VERSION ""

NS_ :

BS_:

BU_: ACM AMP BCM DIAG_TEST IPC LBSS SGW MCM MHM RBSS TTM VTM

BO_ 1884 BCM_IGNITION_ON_COUNTER: 2 BCM
 SG_ IgnitionOnCounter : 7|16@0+ (1,0) [0|65535] "-"  ACM,AMP,LBSS,SGW,MCM,RBSS,TTM,VTM

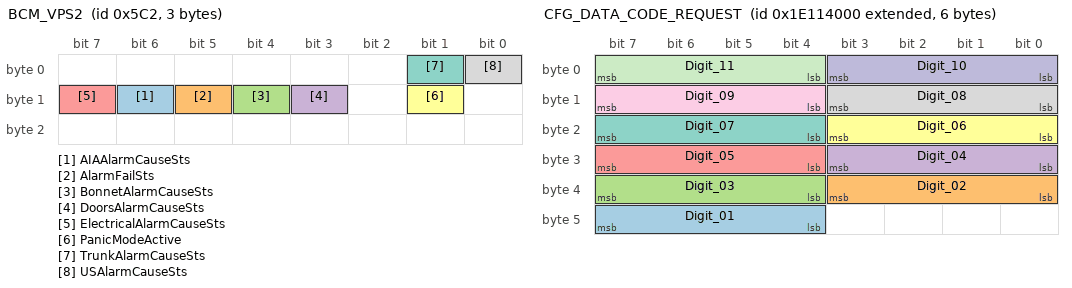
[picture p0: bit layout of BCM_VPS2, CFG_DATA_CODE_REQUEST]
BO_ 1474 BCM_VPS2: 3 BCM
 SG_ AIAAlarmCauseSts : 14|1@0+ (1,0) [0|1] "-"  IPC
 SG_ AlarmFailSts : 13|1@0+ (1,0) [0|1] "-"  IPC
 SG_ BonnetAlarmCauseSts : 12|1@0+ (1,0) [0|1] "-"  IPC
 SG_ DoorsAlarmCauseSts : 11|1@0+ (1,0) [0|1] "-"  IPC
 SG_ ElectricalAlarmCauseSts : 15|1@0+ (1,0) [0|1] "-"  IPC
 SG_ PanicModeActive : 9|1@0+ (1,0) [0|1] "-"  Vector__XXX
 SG_ TrunkAlarmCauseSts : 1|1@0+ (1,0) [0|1] "-"  IPC
 SG_ USAlarmCauseSts : 0|1@0+ (1,0) [0|1] "-"  IPC

BO_ 160 BODY6: 2 BCM
 SG_ BCMFpsCommand : 5|1@0+ (1,0) [0|1] "-"  ACM,MCM,MHM
 SG_ BCMFpsConfirm : 7|1@0+ (1,0) [0|1] "-"  ACM,MCM,MHM
 SG_ BCMFpsFailSts : 6|1@0+ (1,0) [0|1] "-"  ACM,MCM,MHM

BO_ 2651930624 CFG_DATA_CODE_REQUEST: 6 BCM
 SG_ Digit_01 : 47|4@0+ (1,0) [0|15] ""  ACM,AMP,LBSS,SGW,MCM,RBSS,TTM
 SG_ Digit_02 : 35|4@0+ (1,0) [0|15] ""  ACM,AMP,LBSS,SGW,MCM,RBSS,TTM
 SG_ Digit_03 : 39|4@0+ (1,0) [0|15] ""  ACM,AMP,LBSS,SGW,MCM,RBSS,TTM
 SG_ Digit_04 : 27|4@0+ (1,0) [0|15] ""  ACM,AMP,LBSS,SGW,MCM,RBSS,TTM
 SG_ Digit_05 : 31|4@0+ (1,0) [0|15] ""  ACM,AMP,LBSS,SGW,MCM,RBSS,TTM
 SG_ Digit_06 : 19|4@0+ (1,0) [0|15] ""  ACM,AMP,LBSS,SGW,MCM,RBSS,TTM
 SG_ Digit_07 : 23|4@0+ (1,0) [0|15] ""  ACM,AMP,LBSS,SGW,MCM,RBSS,TTM
 SG_ Digit_08 : 11|4@0+ (1,0) [0|15] ""  ACM,AMP,LBSS,SGW,MCM,RBSS,TTM
 SG_ Digit_09 : 15|4@0+ (1,0) [0|15] ""  ACM,AMP,LBSS,SGW,MCM,RBSS,TTM
 SG_ Digit_10 : 3|4@0+ (1,0) [0|15] ""  ACM,AMP,LBSS,SGW,MCM,RBSS,TTM
 SG_ Digit_11 : 7|4@0+ (1,0) [0|15] ""  ACM,AMP,LBSS,SGW,MCM,RBSS,TTM

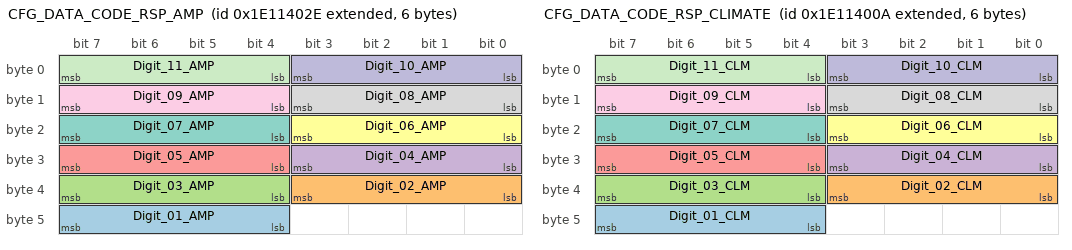
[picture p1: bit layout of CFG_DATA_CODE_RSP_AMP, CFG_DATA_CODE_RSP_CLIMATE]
BO_ 2651930670 CFG_DATA_CODE_RSP_AMP: 6 AMP
 SG_ Digit_01_AMP : 47|4@0+ (1,0) [0|15] "-"  BCM
 SG_ Digit_02_AMP : 35|4@0+ (1,0) [0|15] "-"  BCM
 SG_ Digit_03_AMP : 39|4@0+ (1,0) [0|15] "-"  BCM
 SG_ Digit_04_AMP : 27|4@0+ (1,0) [0|15] "-"  BCM
 SG_ Digit_05_AMP : 31|4@0+ (1,0) [0|15] "-"  BCM
 SG_ Digit_06_AMP : 19|4@0+ (1,0) [0|15] "-"  BCM
 SG_ Digit_07_AMP : 23|4@0+ (1,0) [0|15] "-"  BCM
 SG_ Digit_08_AMP : 11|4@0+ (1,0) [0|15] "-"  BCM
 SG_ Digit_09_AMP : 15|4@0+ (1,0) [0|15] "-"  BCM
 SG_ Digit_10_AMP : 3|4@0+ (1,0) [0|15] "-"  BCM
 SG_ Digit_11_AMP : 7|4@0+ (1,0) [0|15] "-"  BCM

BO_ 2651930634 CFG_DATA_CODE_RSP_CLIMATE: 6 ACM
 SG_ Digit_01_CLM : 47|4@0+ (1,0) [0|15] "-"  BCM
 SG_ Digit_02_CLM : 35|4@0+ (1,0) [0|15] "-"  BCM
 SG_ Digit_03_CLM : 39|4@0+ (1,0) [0|15] "-"  BCM
 SG_ Digit_04_CLM : 27|4@0+ (1,0) [0|15] "-"  BCM
 SG_ Digit_05_CLM : 31|4@0+ (1,0) [0|15] "-"  BCM
 SG_ Digit_06_CLM : 19|4@0+ (1,0) [0|15] "-"  BCM
 SG_ Digit_07_CLM : 23|4@0+ (1,0) [0|15] "-"  BCM
 SG_ Digit_08_CLM : 11|4@0+ (1,0) [0|15] "-"  BCM
 SG_ Digit_09_CLM : 15|4@0+ (1,0) [0|15] "-"  BCM
 SG_ Digit_10_CLM : 3|4@0+ (1,0) [0|15] "-"  BCM
 SG_ Digit_11_CLM : 7|4@0+ (1,0) [0|15] "-"  BCM

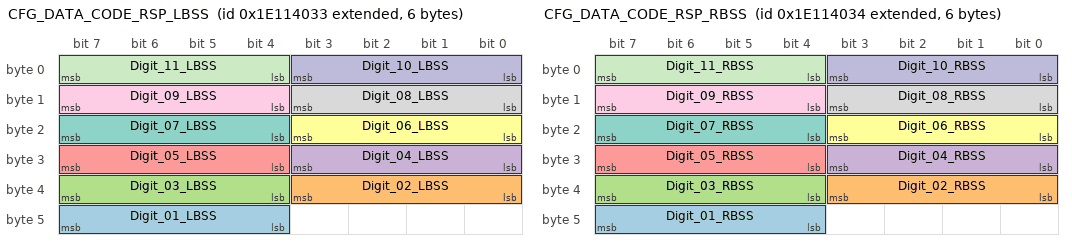
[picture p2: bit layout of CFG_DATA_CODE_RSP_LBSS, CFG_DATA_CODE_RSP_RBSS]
BO_ 2651930675 CFG_DATA_CODE_RSP_LBSS: 6 LBSS
 SG_ Digit_01_LBSS : 47|4@0+ (1,0) [0|15] "-"  BCM
 SG_ Digit_02_LBSS : 35|4@0+ (1,0) [0|15] "-"  BCM
 SG_ Digit_03_LBSS : 39|4@0+ (1,0) [0|15] "-"  BCM
 SG_ Digit_04_LBSS : 27|4@0+ (1,0) [0|15] "-"  BCM
 SG_ Digit_05_LBSS : 31|4@0+ (1,0) [0|15] "-"  BCM
 SG_ Digit_06_LBSS : 19|4@0+ (1,0) [0|15] "-"  BCM
 SG_ Digit_07_LBSS : 23|4@0+ (1,0) [0|15] "-"  BCM
 SG_ Digit_08_LBSS : 11|4@0+ (1,0) [0|15] "-"  BCM
 SG_ Digit_09_LBSS : 15|4@0+ (1,0) [0|15] "-"  BCM
 SG_ Digit_10_LBSS : 3|4@0+ (1,0) [0|15] "-"  BCM
 SG_ Digit_11_LBSS : 7|4@0+ (1,0) [0|15] "-"  BCM

BO_ 2651930676 CFG_DATA_CODE_RSP_RBSS: 6 RBSS
 SG_ Digit_01_RBSS : 47|4@0+ (1,0) [0|15] "-"  BCM
 SG_ Digit_02_RBSS : 35|4@0+ (1,0) [0|15] "-"  BCM
 SG_ Digit_03_RBSS : 39|4@0+ (1,0) [0|15] "-"  BCM
 SG_ Digit_04_RBSS : 27|4@0+ (1,0) [0|15] "-"  BCM
 SG_ Digit_05_RBSS : 31|4@0+ (1,0) [0|15] "-"  BCM
 SG_ Digit_06_RBSS : 19|4@0+ (1,0) [0|15] "-"  BCM
 SG_ Digit_07_RBSS : 23|4@0+ (1,0) [0|15] "-"  BCM
 SG_ Digit_08_RBSS : 11|4@0+ (1,0) [0|15] "-"  BCM
 SG_ Digit_09_RBSS : 15|4@0+ (1,0) [0|15] "-"  BCM
 SG_ Digit_10_RBSS : 3|4@0+ (1,0) [0|15] "-"  BCM
 SG_ Digit_11_RBSS : 7|4@0+ (1,0) [0|15] "-"  BCM

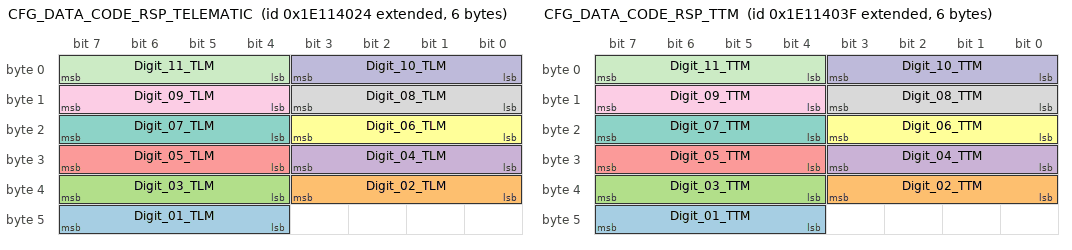
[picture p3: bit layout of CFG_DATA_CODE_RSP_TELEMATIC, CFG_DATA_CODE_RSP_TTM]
BO_ 2651930660 CFG_DATA_CODE_RSP_TELEMATIC: 6 SGW
 SG_ Digit_01_TLM : 47|4@0+ (1,0) [0|15] "-"  BCM
 SG_ Digit_02_TLM : 35|4@0+ (1,0) [0|15] "-"  BCM
 SG_ Digit_03_TLM : 39|4@0+ (1,0) [0|15] "-"  BCM
 SG_ Digit_04_TLM : 27|4@0+ (1,0) [0|15] "-"  BCM
 SG_ Digit_05_TLM : 31|4@0+ (1,0) [0|15] "-"  BCM
 SG_ Digit_06_TLM : 19|4@0+ (1,0) [0|15] "-"  BCM
 SG_ Digit_07_TLM : 23|4@0+ (1,0) [0|15] "-"  BCM
 SG_ Digit_08_TLM : 11|4@0+ (1,0) [0|15] "-"  BCM
 SG_ Digit_09_TLM : 15|4@0+ (1,0) [0|15] "-"  BCM
 SG_ Digit_10_TLM : 3|4@0+ (1,0) [0|15] "-"  BCM
 SG_ Digit_11_TLM : 7|4@0+ (1,0) [0|15] "-"  BCM

BO_ 2651930687 CFG_DATA_CODE_RSP_TTM: 6 TTM
 SG_ Digit_01_TTM : 47|4@0+ (1,0) [0|15] "-"  BCM
 SG_ Digit_02_TTM : 35|4@0+ (1,0) [0|15] "-"  BCM
 SG_ Digit_03_TTM : 39|4@0+ (1,0) [0|15] "-"  BCM
 SG_ Digit_04_TTM : 27|4@0+ (1,0) [0|15] "-"  BCM
 SG_ Digit_05_TTM : 31|4@0+ (1,0) [0|15] "-"  BCM
 SG_ Digit_06_TTM : 19|4@0+ (1,0) [0|15] "-"  BCM
 SG_ Digit_07_TTM : 23|4@0+ (1,0) [0|15] "-"  BCM
 SG_ Digit_08_TTM : 11|4@0+ (1,0) [0|15] "-"  BCM
 SG_ Digit_09_TTM : 15|4@0+ (1,0) [0|15] "-"  BCM
 SG_ Digit_10_TTM : 3|4@0+ (1,0) [0|15] "-"  BCM
 SG_ Digit_11_TTM : 7|4@0+ (1,0) [0|15] "-"  BCM

BO_ 134 CLIMATE_REQ: 2 ACM
 SG_ FPS_Status_Request : 7|1@0+ (1,0) [0|1] "-"  BCM

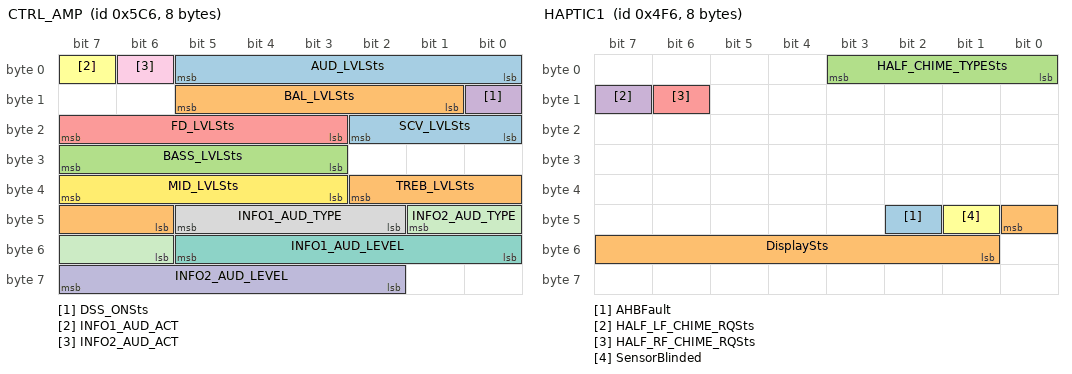
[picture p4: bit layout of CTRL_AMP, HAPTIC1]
BO_ 1478 CTRL_AMP: 8 SGW
 SG_ AUD_LVLSts : 5|6@0+ (1,0) [0|63] ""  AMP
 SG_ BAL_LVLSts : 13|5@0+ (1,0) [0|31] ""  AMP
 SG_ BASS_LVLSts : 31|5@0+ (1,0) [0|31] ""  AMP
 SG_ DSS_ONSts : 8|1@0+ (1,0) [0|1] ""  AMP
 SG_ FD_LVLSts : 23|5@0+ (1,0) [0|31] ""  AMP
 SG_ INFO1_AUD_ACT : 7|1@0+ (1,0) [0|1] ""  AMP
 SG_ INFO1_AUD_LEVEL : 53|6@0+ (1,0) [0|63] ""  AMP
 SG_ INFO1_AUD_TYPE : 45|4@0+ (1,0) [0|15] ""  AMP
 SG_ INFO2_AUD_ACT : 6|1@0+ (1,0) [0|1] ""  AMP
 SG_ INFO2_AUD_LEVEL : 63|6@0+ (1,0) [0|63] ""  AMP
 SG_ INFO2_AUD_TYPE : 41|4@0+ (1,0) [0|15] ""  AMP
 SG_ MID_LVLSts : 39|5@0+ (1,0) [0|31] ""  AMP
 SG_ SCV_LVLSts : 18|3@0+ (1,0) [0|6] ""  AMP
 SG_ TREB_LVLSts : 34|5@0+ (1,0) [0|31] ""  AMP

BO_ 2564554481 DIAGNOSTIC_REQ_FUNC_BH_C2: 8 DIAG_TEST
 SG_ N_PDU : 7|64@0+ (1,0) [0|0] ""  ACM,AMP,BCM,LBSS,MCM,RBSS,TTM,VTM

BO_ 2564457457 DIAGNOSTIC_REQUEST_AMP: 8 BCM
 SG_ N_PDU : 7|64@0+ (1,0) [0|0] ""  AMP

BO_ 2564462833 DIAGNOSTIC_REQUEST_CLIMATE: 8 BCM
 SG_ N_PDU : 7|64@0+ (1,0) [0|0] ""  ACM,MCM

BO_ 2564449009 DIAGNOSTIC_REQUEST_LBSS: 8 BCM
 SG_ N_PDU : 7|64@0+ (1,0) [0|0] ""  LBSS

BO_ 2564449777 DIAGNOSTIC_REQUEST_RBSS: 8 BCM
 SG_ N_PDU : 7|64@0+ (1,0) [0|0] ""  RBSS

BO_ 2564442865 DIAGNOSTIC_REQUEST_TTM: 8 BCM
 SG_ N_PDU : 7|64@0+ (1,0) [0|0] ""  TTM

BO_ 2564473329 DIAGNOSTIC_REQUEST_VTM: 8 BCM
 SG_ N_PDU : 7|64@0+ (1,0) [0|0] "-"  VTM

BO_ 2564485507 DIAGNOSTIC_RESPONSE_AMP: 8 AMP
 SG_ N_PDU : 7|64@0+ (1,0) [0|0] "-"  BCM,DIAG_TEST,SGW

BO_ 2564485528 DIAGNOSTIC_RESPONSE_CLIMATE: 8 ACM
 SG_ N_PDU : 7|64@0+ (1,0) [0|0] ""  BCM,DIAG_TEST,SGW

BO_ 2564485474 DIAGNOSTIC_RESPONSE_LBSS: 8 LBSS
 SG_ N_PDU : 7|64@0+ (1,0) [0|0] "-"  BCM,DIAG_TEST,SGW

BO_ 2564485477 DIAGNOSTIC_RESPONSE_RBSS: 8 RBSS
 SG_ N_PDU : 7|64@0+ (1,0) [0|0] "-"  BCM,DIAG_TEST,SGW

BO_ 2564485450 DIAGNOSTIC_RESPONSE_TTM: 8 TTM
 SG_ N_PDU : 7|64@0+ (1,0) [0|0] "-"  BCM,DIAG_TEST,SGW

BO_ 2564485569 DIAGNOSTIC_RESPONSE_VTM: 8 VTM
 SG_ N_PDU : 7|64@0+ (1,0) [0|0] "-"  BCM,DIAG_TEST,SGW

BO_ 852 EXTERNAL_LIGHTS: 4 BCM
 SG_ AHBFeature : 19|1@0+ (1,0) [0|1] "-"  IPC
 SG_ AlertLightsON : 31|1@0+ (1,0) [0|1] "-"  IPC
 SG_ DRLFault : 6|1@0+ (1,0) [0|1] "-"  IPC
 SG_ FHeatedWindowSts : 5|1@0+ (1,0) [0|1] "-"  ACM,MCM
 SG_ FrontFogLightSts : 4|1@0+ (1,0) [0|1] "-"  IPC
 SG_ HeatedMirrorSts : 3|1@0+ (1,0) [0|1] "-"  Vector__XXX
 SG_ HighBeamSts : 2|1@0+ (1,0) [0|1] "-"  IPC
 SG_ L_TurnLightActivationSts : 17|1@0+ (1,0) [0|1] "-"  TTM
 SG_ LHParkingLightSts : 1|1@0+ (1,0) [0|1] "-"  IPC,TTM
 SG_ LHTurnLightFault : 0|1@0+ (1,0) [0|1] "-"  IPC
 SG_ LHTurnSignalSts : 15|1@0+ (1,0) [0|1] "-"  IPC,TTM
 SG_ LowBeamSts : 14|1@0+ (1,0) [0|1] "-"  IPC
 SG_ ParkingLightFault : 13|1@0+ (1,0) [0|1] "-"  IPC
 SG_ PlateLightFault : 12|1@0+ (1,0) [0|1] "-"  IPC
 SG_ R_TurnLightActivationSts : 16|1@0+ (1,0) [0|1] "-"  TTM
 SG_ RearFogLightFault : 11|1@0+ (1,0) [0|1] "-"  IPC
 SG_ RearFogLightSts : 10|1@0+ (1,0) [0|1] "-"  IPC,TTM
 SG_ ReverseGearLightFault : 9|1@0+ (1,0) [0|1] "-"  IPC
 SG_ RHeatedWindowSts : 8|1@0+ (1,0) [0|1] "-"  ACM,MCM
 SG_ RHParkingLightSts : 23|1@0+ (1,0) [0|1] "-"  IPC,TTM
 SG_ RHTurnLightFault : 22|1@0+ (1,0) [0|1] "-"  IPC
 SG_ RHTurnSignalSts : 21|1@0+ (1,0) [0|1] "-"  IPC,TTM
 SG_ StopLightFault : 20|1@0+ (1,0) [0|1] "-"  IPC
 SG_ StopLightSts : 18|1@0+ (1,0) [0|1] "-"  TTM

BO_ 1270 HAPTIC1: 8 BCM
 SG_ AHBFault : 42|1@0+ (1,0) [0|1] ""  IPC
 SG_ DisplaySts : 40|8@0+ (1,0) [0|255] "-"  IPC
 SG_ HALF_CHIME_TYPESts : 3|4@0+ (1,0) [0|15] "-"  AMP,SGW
 SG_ HALF_LF_CHIME_RQSts : 15|1@0+ (1,0) [0|1] "-"  AMP,SGW
 SG_ HALF_RF_CHIME_RQSts : 14|1@0+ (1,0) [0|1] "-"  AMP,SGW
 SG_ SensorBlinded : 41|1@0+ (1,0) [0|1] ""  IPC

BO_ 986 IPC_ACK: 1 IPC
 SG_ DisplayInfoReceptionSts : 7|1@0+ (1,0) [0|1] "-"  SGW

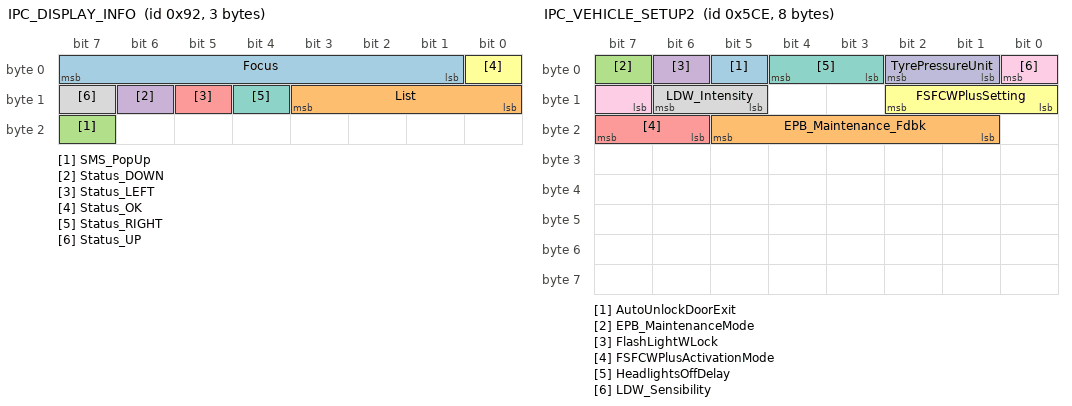
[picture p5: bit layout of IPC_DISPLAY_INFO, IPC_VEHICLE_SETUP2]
BO_ 146 IPC_DISPLAY_INFO: 3 IPC
 SG_ Focus : 7|7@0+ (1,0) [0|127] "-"  SGW
 SG_ List : 11|4@0+ (1,0) [0|15] ""  SGW
 SG_ SMS_PopUp : 23|1@0+ (1,0) [0|1] "-"  SGW
 SG_ Status_DOWN : 14|1@0+ (1,0) [0|1] "-"  SGW
 SG_ Status_LEFT : 13|1@0+ (1,0) [0|1] "-"  SGW
 SG_ Status_OK : 0|1@0+ (1,0) [0|1] "-"  SGW
 SG_ Status_RIGHT : 12|1@0+ (1,0) [0|1] "-"  SGW
 SG_ Status_UP : 15|1@0+ (1,0) [0|1] "-"  SGW

BO_ 1468 IPC_VEHICLE_SETUP: 8 IPC
 SG_ AmbientLightingLevel : 48|4@0+ (1,0) [0|15] ""  BCM,SGW
 SG_ AudioRepetition : 46|1@0+ (1,0) [0|1] ""  SGW
 SG_ AutoHighBeamEnable : 21|1@0+ (1,0) [0|1] "-"  BCM,SGW
 SG_ AutomaticResetTripB : 37|2@0+ (1,0) [0|3] ""  SGW
 SG_ AutoParkBrake : 47|1@0+ (1,0) [0|1] ""  SGW
 SG_ AutoRelock : 51|1@0+ (1,0) [0|1] ""  BCM
 SG_ BSDEnable : 30|2@0+ (1,0) [0|3] ""  LBSS,SGW,RBSS
 SG_ ConsumptionUnit : 15|3@0+ (1,0) [0|7] "-"  SGW
 SG_ CorneringEnable : 18|1@0+ (1,0) [0|1] "-"  BCM,SGW
 SG_ DistanceUnit : 10|1@0+ (1,0) [0|1] "-"  SGW
 SG_ DRLEnable : 12|1@0+ (1,0) [0|1] "-"  BCM,SGW
 SG_ ExternalLightSensorLevel : 9|2@0+ (1,0) [0|3] "-"  BCM,SGW
 SG_ GreetingLightsEnable : 11|1@0+ (1,0) [0|1] "-"  BCM,SGW
 SG_ HourMode : 23|1@0+ (1,0) [0|1] "-"  SGW
 SG_ LanguageSelection : 7|8@0+ (1,0) [0|255] "-"  SGW
 SG_ NavRepetition : 50|1@0+ (1,0) [0|1] ""  SGW
 SG_ PamAlertMode : 43|2@0+ (1,0) [0|3] "-"  AMP,BCM,SGW
 SG_ PamChimeVolumeFront : 45|2@0+ (1,0) [0|3] ""  AMP,SGW
 SG_ PamChimeVolumeRear : 41|2@0+ (1,0) [0|3] ""  AMP,SGW
 SG_ PassiveEntry : 28|1@0+ (1,0) [0|1] ""  BCM,SGW
 SG_ PhoneRepetition : 49|1@0+ (1,0) [0|1] ""  SGW
 SG_ RainSensorLevel : 22|1@0+ (1,0) [0|1] "-"  BCM,SGW
 SG_ RemoteDoorUnlock : 32|1@0+ (1,0) [0|1] ""  BCM,SGW
 SG_ Sdw : 55|2@0+ (1,0) [0|3] ""  AMP,BCM,SGW
 SG_ SdwChimeVolume : 53|2@0+ (1,0) [0|3] ""  AMP,SGW
 SG_ SoundHornLock : 35|2@0+ (1,0) [0|3] ""  SGW
 SG_ SoundHornRemoteStart : 33|1@0+ (1,0) [0|1] ""  SGW
 SG_ SpeedLockDoorEnable : 20|1@0+ (1,0) [0|1] "-"  BCM,SGW
 SG_ TelematicSetupACK : 16|2@0+ (1,0) [0|3] "-"  SGW
 SG_ TemperatureUnit : 19|1@0+ (1,0) [0|1] "-"  ACM,SGW

BO_ 1486 IPC_VEHICLE_SETUP2: 8 IPC
 SG_ AutoUnlockDoorExit : 5|1@0+ (1,0) [0|1] "-"  BCM,SGW
 SG_ EPB_Maintenance_Fdbk : 21|5@0+ (1,0) [0|31] "-"  SGW
 SG_ EPB_MaintenanceMode : 7|1@0+ (1,0) [0|1] "-"  SGW
 SG_ FlashLightWLock : 6|1@0+ (1,0) [0|1] "-"  BCM,SGW
 SG_ FSFCWPlusActivationMode : 23|2@0+ (1,0) [0|3] "-"  SGW
 SG_ FSFCWPlusSetting : 10|3@0+ (1,0) [0|7] "-"  SGW
 SG_ HeadlightsOffDelay : 4|2@0+ (1,0) [0|3] "-"  BCM,SGW
 SG_ LDW_Intensity : 14|2@0+ (1,0) [0|3] "-"  BCM,SGW
 SG_ LDW_Sensibility : 0|2@0+ (1,0) [0|3] "-"  BCM,SGW
 SG_ TyrePressureUnit : 2|2@0+ (1,0) [0|3] "-"  SGW

BO_ 773 LBSS_STAT: 2 LBSS
 SG_ LbssSysBlockIndSts : 7|1@0+ (1,0) [0|1] ""  RBSS
 SG_ LbssSysInterfIndSts : 3|1@0+ (1,0) [0|1] ""  RBSS
 SG_ LbssSysSrvIndSts : 5|1@0+ (1,0) [0|1] ""  RBSS
 SG_ LbssTmpUnavIndSts : 4|1@0+ (1,0) [0|1] ""  RBSS

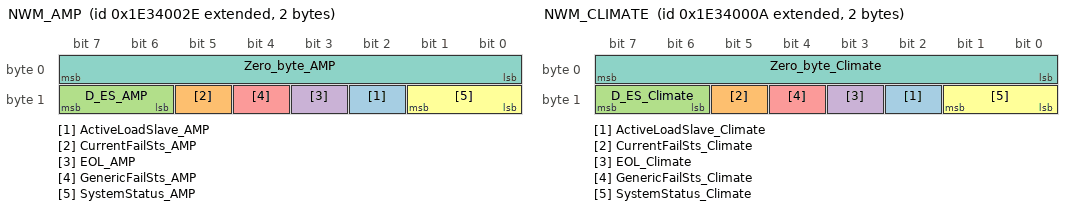
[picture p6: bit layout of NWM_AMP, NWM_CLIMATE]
BO_ 2654208046 NWM_AMP: 2 AMP
 SG_ ActiveLoadSlave_AMP : 10|1@0+ (1,0) [0|1] "-"  BCM
 SG_ CurrentFailSts_AMP : 13|1@0+ (1,0) [0|1] "-"  BCM
 SG_ D_ES_AMP : 15|2@0+ (1,0) [0|3] "-"  Vector__XXX
 SG_ EOL_AMP : 11|1@0+ (1,0) [0|1] "-"  BCM
 SG_ GenericFailSts_AMP : 12|1@0+ (1,0) [0|1] "-"  BCM
 SG_ SystemStatus_AMP : 9|2@0+ (1,0) [0|3] "-"  BCM
 SG_ Zero_byte_AMP : 7|8@0+ (1,0) [0|0] "-"  BCM

BO_ 2654208000 NWM_BCM: 6 BCM
 SG_ ActiveLoadMaster : 10|1@0+ (1,0) [0|1] "-"  ACM,AMP,IPC,LBSS,SGW,MCM,RBSS,TTM,VTM
 SG_ D_ES_BCM : 15|2@0+ (1,0) [0|3] "-"  ACM,AMP,IPC,LBSS,SGW,MCM,RBSS,TTM,VTM
 SG_ EOL_BCM : 11|1@0+ (1,0) [0|1] "-"  ACM,AMP,IPC,LBSS,SGW,MCM,RBSS,TTM,VTM
 SG_ GenericFailSts_BCM : 12|1@0+ (1,0) [0|1] "-"  ACM,AMP,IPC,LBSS,SGW,MCM,RBSS,TTM,VTM
 SG_ Node0 : 40|1@0+ (1,0) [0|1] "-"  ACM,AMP,IPC,LBSS,SGW,MCM,RBSS,TTM,VTM
 SG_ Node1 : 41|1@0+ (1,0) [0|1] "-"  ACM,AMP,IPC,LBSS,SGW,MCM,RBSS,TTM,VTM
 SG_ Node10 : 34|1@0+ (1,0) [0|1] "-"  ACM,AMP,IPC,LBSS,SGW,MCM,RBSS,TTM,VTM
 SG_ Node11 : 35|1@0+ (1,0) [0|1] "-"  ACM,AMP,IPC,LBSS,SGW,MCM,RBSS,TTM,VTM
 SG_ Node12 : 36|1@0+ (1,0) [0|1] "-"  ACM,AMP,IPC,LBSS,SGW,MCM,RBSS,TTM,VTM
 SG_ Node13 : 37|1@0+ (1,0) [0|1] "-"  ACM,AMP,IPC,LBSS,SGW,MCM,RBSS,TTM,VTM
 SG_ Node14 : 38|1@0+ (1,0) [0|1] "-"  ACM,AMP,IPC,LBSS,SGW,MCM,RBSS,TTM,VTM
 SG_ Node15 : 39|1@0+ (1,0) [0|1] "-"  ACM,AMP,IPC,LBSS,SGW,MCM,RBSS,TTM,VTM
 SG_ Node16 : 24|1@0+ (1,0) [0|1] "-"  ACM,AMP,IPC,LBSS,SGW,MCM,RBSS,TTM,VTM
 SG_ Node17 : 25|1@0+ (1,0) [0|1] "-"  ACM,AMP,IPC,LBSS,SGW,MCM,RBSS,TTM,VTM
 SG_ Node18 : 26|1@0+ (1,0) [0|1] "-"  ACM,AMP,IPC,LBSS,SGW,MCM,RBSS,TTM,VTM
 SG_ Node19 : 27|1@0+ (1,0) [0|1] "-"  ACM,AMP,IPC,LBSS,SGW,MCM,RBSS,TTM,VTM
 SG_ Node2 : 42|1@0+ (1,0) [0|1] "-"  ACM,AMP,IPC,LBSS,SGW,MCM,RBSS,TTM,VTM
 SG_ Node20 : 28|1@0+ (1,0) [0|1] "-"  ACM,AMP,IPC,LBSS,SGW,MCM,RBSS,TTM,VTM
 SG_ Node21 : 29|1@0+ (1,0) [0|1] "-"  ACM,AMP,IPC,LBSS,SGW,MCM,RBSS,TTM,VTM
 SG_ Node22 : 30|1@0+ (1,0) [0|1] "-"  ACM,AMP,IPC,LBSS,SGW,MCM,RBSS,TTM,VTM
 SG_ Node23 : 31|1@0+ (1,0) [0|1] "-"  ACM,AMP,IPC,LBSS,SGW,MCM,RBSS,TTM,VTM
 SG_ Node24 : 16|1@0+ (1,0) [0|1] "-"  ACM,AMP,IPC,LBSS,SGW,MCM,RBSS,TTM,VTM
 SG_ Node25 : 17|1@0+ (1,0) [0|1] "-"  ACM,AMP,IPC,LBSS,SGW,MCM,RBSS,TTM,VTM
 SG_ Node26 : 18|1@0+ (1,0) [0|1] "-"  ACM,AMP,IPC,LBSS,SGW,MCM,RBSS,TTM,VTM
 SG_ Node27 : 19|1@0+ (1,0) [0|1] "-"  ACM,AMP,IPC,LBSS,SGW,MCM,RBSS,TTM,VTM
 SG_ Node28 : 20|1@0+ (1,0) [0|1] "-"  ACM,AMP,IPC,LBSS,SGW,MCM,RBSS,TTM,VTM
 SG_ Node29 : 21|1@0+ (1,0) [0|1] "-"  ACM,AMP,IPC,LBSS,SGW,MCM,RBSS,TTM,VTM
 SG_ Node3 : 43|1@0+ (1,0) [0|1] "-"  ACM,AMP,IPC,LBSS,SGW,MCM,RBSS,TTM,VTM
 SG_ Node30 : 22|1@0+ (1,0) [0|1] "-"  ACM,AMP,IPC,LBSS,SGW,MCM,RBSS,TTM,VTM
 SG_ Node31 : 23|1@0+ (1,0) [0|1] "-"  ACM,AMP,IPC,LBSS,SGW,MCM,RBSS,TTM,VTM
 SG_ Node4 : 44|1@0+ (1,0) [0|1] "-"  ACM,AMP,IPC,LBSS,SGW,MCM,RBSS,TTM,VTM
 SG_ Node5 : 45|1@0+ (1,0) [0|1] "-"  ACM,AMP,IPC,LBSS,SGW,MCM,RBSS,TTM,VTM
 SG_ Node6 : 46|1@0+ (1,0) [0|1] "-"  ACM,AMP,IPC,LBSS,SGW,MCM,RBSS,TTM,VTM
 SG_ Node7 : 47|1@0+ (1,0) [0|1] "-"  ACM,AMP,IPC,LBSS,SGW,MCM,RBSS,TTM,VTM
 SG_ Node8 : 32|1@0+ (1,0) [0|1] "-"  ACM,AMP,IPC,LBSS,SGW,MCM,RBSS,TTM,VTM
 SG_ Node9 : 33|1@0+ (1,0) [0|1] "-"  ACM,AMP,IPC,LBSS,SGW,MCM,RBSS,TTM,VTM
 SG_ P_ES : 13|1@0+ (1,0) [0|1] "-"  ACM,AMP,IPC,LBSS,SGW,MCM,RBSS,TTM,VTM
 SG_ SystemCommand : 9|2@0+ (1,0) [0|3] "-"  ACM,AMP,IPC,LBSS,SGW,MCM,RBSS,TTM,VTM
 SG_ Zero_byte_BCM : 7|8@0+ (1,0) [0|0] "-"  ACM,AMP,IPC,LBSS,SGW,MCM,RBSS,TTM,VTM

BO_ 2654208010 NWM_CLIMATE: 2 ACM
 SG_ ActiveLoadSlave_Climate : 10|1@0+ (1,0) [0|1] "-"  BCM
 SG_ CurrentFailSts_Climate : 13|1@0+ (1,0) [0|1] "-"  BCM
 SG_ D_ES_Climate : 15|2@0+ (1,0) [0|3] "-"  Vector__XXX
 SG_ EOL_Climate : 11|1@0+ (1,0) [0|1] "-"  BCM
 SG_ GenericFailSts_Climate : 12|1@0+ (1,0) [0|1] "-"  BCM
 SG_ SystemStatus_Climate : 9|2@0+ (1,0) [0|3] "-"  BCM
 SG_ Zero_byte_Climate : 7|8@0+ (1,0) [0|0] "-"  BCM

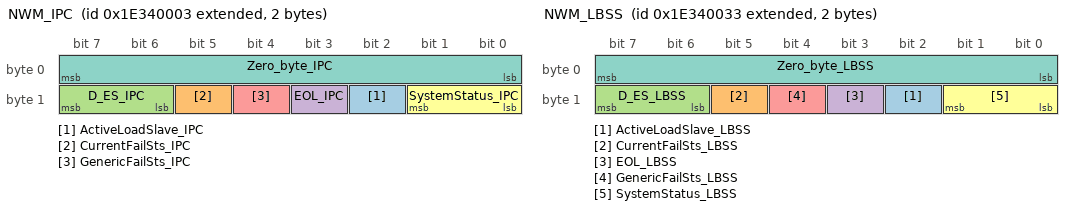
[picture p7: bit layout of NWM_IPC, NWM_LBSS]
BO_ 2654208003 NWM_IPC: 2 IPC
 SG_ ActiveLoadSlave_IPC : 10|1@0+ (1,0) [0|1] "-"  BCM
 SG_ CurrentFailSts_IPC : 13|1@0+ (1,0) [0|1] "-"  BCM
 SG_ D_ES_IPC : 15|2@0+ (1,0) [0|3] "-"  Vector__XXX
 SG_ EOL_IPC : 11|1@0+ (1,0) [0|1] "-"  BCM
 SG_ GenericFailSts_IPC : 12|1@0+ (1,0) [0|1] "-"  BCM
 SG_ SystemStatus_IPC : 9|2@0+ (1,0) [0|3] "-"  BCM
 SG_ Zero_byte_IPC : 7|8@0+ (1,0) [0|0] "-"  BCM

BO_ 2654208051 NWM_LBSS: 2 LBSS
 SG_ ActiveLoadSlave_LBSS : 10|1@0+ (1,0) [0|1] "-"  BCM
 SG_ CurrentFailSts_LBSS : 13|1@0+ (1,0) [0|1] "-"  BCM
 SG_ D_ES_LBSS : 15|2@0+ (1,0) [0|3] "-"  Vector__XXX
 SG_ EOL_LBSS : 11|1@0+ (1,0) [0|1] "-"  BCM
 SG_ GenericFailSts_LBSS : 12|1@0+ (1,0) [0|1] "-"  BCM
 SG_ SystemStatus_LBSS : 9|2@0+ (1,0) [0|3] "-"  BCM
 SG_ Zero_byte_LBSS : 7|8@0+ (1,0) [0|0] "-"  BCM

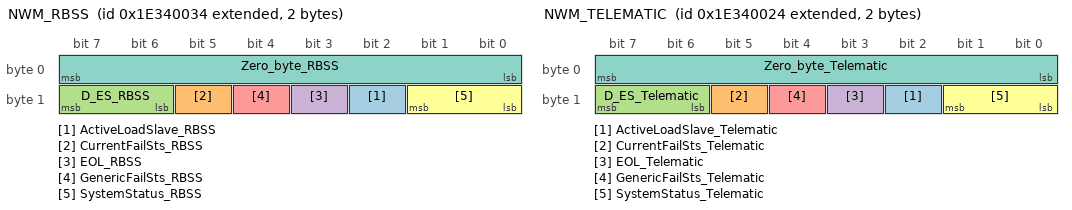
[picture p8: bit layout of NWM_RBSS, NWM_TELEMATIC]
BO_ 2654208052 NWM_RBSS: 2 RBSS
 SG_ ActiveLoadSlave_RBSS : 10|1@0+ (1,0) [0|1] "-"  BCM
 SG_ CurrentFailSts_RBSS : 13|1@0+ (1,0) [0|1] "-"  BCM
 SG_ D_ES_RBSS : 15|2@0+ (1,0) [0|3] "-"  Vector__XXX
 SG_ EOL_RBSS : 11|1@0+ (1,0) [0|1] "-"  BCM
 SG_ GenericFailSts_RBSS : 12|1@0+ (1,0) [0|1] "-"  BCM
 SG_ SystemStatus_RBSS : 9|2@0+ (1,0) [0|3] "-"  BCM
 SG_ Zero_byte_RBSS : 7|8@0+ (1,0) [0|0] "-"  BCM

BO_ 2654208036 NWM_TELEMATIC: 2 SGW
 SG_ ActiveLoadSlave_Telematic : 10|1@0+ (1,0) [0|1] "-"  BCM
 SG_ CurrentFailSts_Telematic : 13|1@0+ (1,0) [0|1] "-"  BCM
 SG_ D_ES_Telematic : 15|2@0+ (1,0) [0|3] "-"  Vector__XXX
 SG_ EOL_Telematic : 11|1@0+ (1,0) [0|1] "-"  BCM
 SG_ GenericFailSts_Telematic : 12|1@0+ (1,0) [0|1] "-"  BCM
 SG_ SystemStatus_Telematic : 9|2@0+ (1,0) [0|3] "-"  BCM
 SG_ Zero_byte_Telematic : 7|8@0+ (1,0) [0|0] "-"  BCM

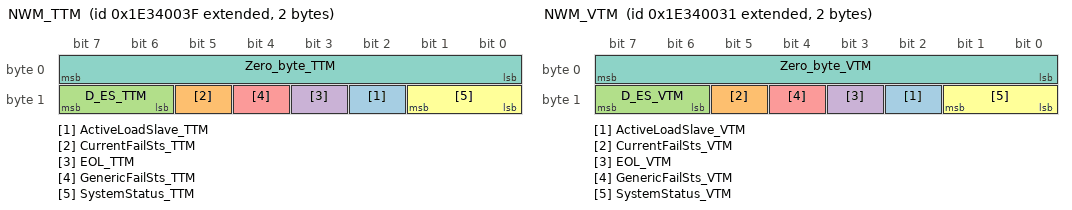
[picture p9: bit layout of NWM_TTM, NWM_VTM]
BO_ 2654208063 NWM_TTM: 2 TTM
 SG_ ActiveLoadSlave_TTM : 10|1@0+ (1,0) [0|1] "-"  BCM
 SG_ CurrentFailSts_TTM : 13|1@0+ (1,0) [0|1] "-"  BCM
 SG_ D_ES_TTM : 15|2@0+ (1,0) [0|3] "-"  Vector__XXX
 SG_ EOL_TTM : 11|1@0+ (1,0) [0|1] "-"  BCM
 SG_ GenericFailSts_TTM : 12|1@0+ (1,0) [0|1] "-"  BCM
 SG_ SystemStatus_TTM : 9|2@0+ (1,0) [0|3] "-"  BCM
 SG_ Zero_byte_TTM : 7|8@0+ (1,0) [0|0] "-"  BCM

BO_ 2654208049 NWM_VTM: 2 VTM
 SG_ ActiveLoadSlave_VTM : 10|1@0+ (1,0) [0|1] "-"  BCM
 SG_ CurrentFailSts_VTM : 13|1@0+ (1,0) [0|1] "-"  BCM
 SG_ D_ES_VTM : 15|2@0+ (1,0) [0|3] "-"  Vector__XXX
 SG_ EOL_VTM : 11|1@0+ (1,0) [0|1] "-"  BCM
 SG_ GenericFailSts_VTM : 12|1@0+ (1,0) [0|1] "-"  BCM
 SG_ SystemStatus_VTM : 9|2@0+ (1,0) [0|3] "-"  BCM
 SG_ Zero_byte_VTM : 7|8@0+ (1,0) [0|0] "-"  BCM

BO_ 950 PARK_INFO: 6 BCM
 SG_ Alert_CHF : 12|3@0+ (1,0) [0|7] "-"  IPC
 SG_ Alert_CHR : 5|3@0+ (1,0) [0|7] "-"  IPC
 SG_ Alert_LHF : 9|3@0+ (1,0) [0|7] "-"  IPC
 SG_ Alert_LHR : 2|3@0+ (1,0) [0|7] "-"  IPC
 SG_ Alert_RHF : 22|3@0+ (1,0) [0|7] "-"  IPC
 SG_ Alert_RHR : 15|3@0+ (1,0) [0|7] "-"  IPC
 SG_ ChimeActivation_LHF : 36|1@0+ (1,0) [0|1] "-"  AMP,SGW
 SG_ ChimeActivation_LHR : 38|1@0+ (1,0) [0|1] "-"  AMP,IPC,SGW
 SG_ ChimeActivation_RHF : 37|1@0+ (1,0) [0|1] "-"  AMP,SGW
 SG_ ChimeActivation_RHR : 39|1@0+ (1,0) [0|1] "-"  AMP,IPC,SGW
 SG_ ChimeRepetitionRate_Front : 47|4@0+ (1,0) [0|15] "Hz"  AMP,SGW
 SG_ ChimeRepetitionRate_Rear : 43|4@0+ (1,0) [0|15] "Hz"  AMP,IPC,SGW
 SG_ ChimeType_Front : 33|2@0+ (1,0) [0|3] "-"  AMP,SGW
 SG_ ChimeType_Rear : 35|2@0+ (1,0) [0|3] "-"  AMP,IPC,SGW
 SG_ DisplayActivation : 6|1@0+ (1,0) [0|1] "-"  IPC
 SG_ Graphic_CHF : 29|2@0+ (1,0) [0|3] "-"  IPC
 SG_ Graphic_CHR : 19|2@0+ (1,0) [0|3] "-"  IPC
 SG_ Graphic_LHF : 27|2@0+ (1,0) [0|3] "-"  IPC
 SG_ Graphic_LHR : 17|2@0+ (1,0) [0|3] "-"  IPC
 SG_ Graphic_RHF : 25|2@0+ (1,0) [0|3] "-"  IPC
 SG_ Graphic_RHR : 31|2@0+ (1,0) [0|3] "-"  IPC

BO_ 775 RBSS_STAT: 2 RBSS
 SG_ RbssSysBlockIndSts : 1|1@0+ (1,0) [0|1] ""  LBSS
 SG_ RbssSysInterfIndSts : 15|1@0+ (1,0) [0|1] ""  LBSS
 SG_ RbssSysSrvIndSts : 7|1@0+ (1,0) [0|1] ""  LBSS
 SG_ RbssTmpUnavIndSts : 0|1@0+ (1,0) [0|1] ""  LBSS

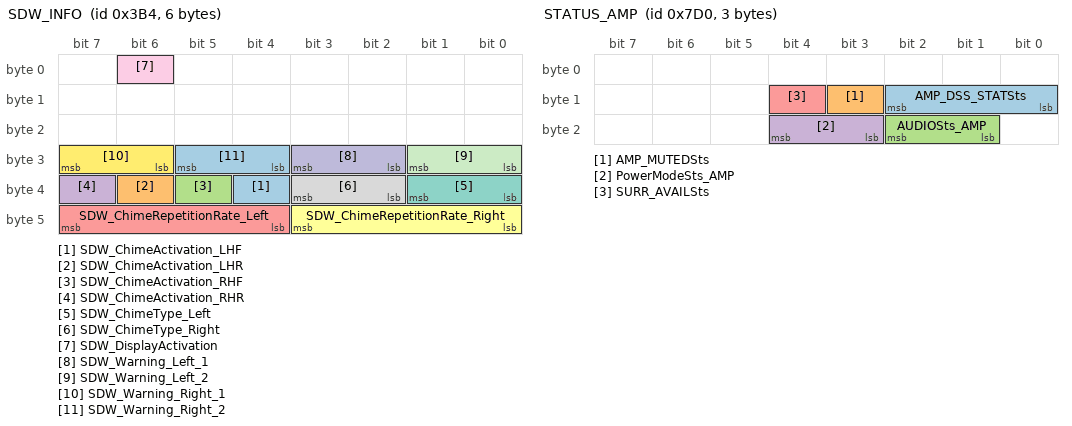
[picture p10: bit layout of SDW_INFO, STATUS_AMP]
BO_ 948 SDW_INFO: 6 BCM
 SG_ SDW_ChimeActivation_LHF : 36|1@0+ (1,0) [0|1] "-"  AMP,SGW
 SG_ SDW_ChimeActivation_LHR : 38|1@0+ (1,0) [0|1] "-"  AMP,SGW
 SG_ SDW_ChimeActivation_RHF : 37|1@0+ (1,0) [0|1] "-"  AMP,SGW
 SG_ SDW_ChimeActivation_RHR : 39|1@0+ (1,0) [0|1] "-"  AMP,SGW
 SG_ SDW_ChimeRepetitionRate_Left : 47|4@0+ (1,0) [0|15] "Hz"  AMP,SGW
 SG_ SDW_ChimeRepetitionRate_Right : 43|4@0+ (1,0) [0|15] "Hz"  AMP,SGW
 SG_ SDW_ChimeType_Left : 33|2@0+ (1,0) [0|3] "-"  AMP,SGW
 SG_ SDW_ChimeType_Right : 35|2@0+ (1,0) [0|3] "-"  AMP,SGW
 SG_ SDW_DisplayActivation : 6|1@0+ (1,0) [0|1] "-"  IPC
 SG_ SDW_Warning_Left_1 : 27|2@0+ (1,0) [0|2] "-"  IPC
 SG_ SDW_Warning_Left_2 : 25|2@0+ (1,0) [0|2] "-"  IPC
 SG_ SDW_Warning_Right_1 : 31|2@0+ (1,0) [0|2] "-"  IPC
 SG_ SDW_Warning_Right_2 : 29|2@0+ (1,0) [0|2] "-"  IPC

BO_ 1890 SERVICEINFO2: 6 IPC
 SG_ DaysToService : 22|9@0+ (1,0) [0|366] "day"  Vector__XXX
 SG_ DistanceToService : 7|17@0+ (1,0) [0|131071] "km_or_mi"  SGW

BO_ 2000 STATUS_AMP: 3 AMP
 SG_ AMP_DSS_STATSts : 10|3@0+ (1,0) [0|7] ""  SGW
 SG_ AMP_MUTEDSts : 11|1@0+ (1,0) [0|1] ""  SGW
 SG_ AUDIOSts_AMP : 18|2@0+ (1,0) [0|3] ""  SGW
 SG_ PowerModeSts_AMP : 20|2@0+ (1,0) [0|3] ""  BCM
 SG_ SURR_AVAILSts : 12|1@0+ (1,0) [0|1] ""  SGW

BO_ 854 STATUS_BH_BCM1: 8 BCM
 SG_ AlarmSysTurnOn : 49|5@0+ (1,0) [0|31] "-"  Vector__XXX
 SG_ AutoCloseSts : 60|1@0+ (1,0) [0|1] ""  Vector__XXX
 SG_ AutoOpenSts : 59|1@0+ (1,0) [0|1] ""  Vector__XXX
 SG_ BonnetSts : 26|1@0+ (1,0) [0|1] "-"  IPC
 SG_ BrakeFluidLevelSts : 25|1@0+ (1,0) [0|1] "-"  SGW
 SG_ BrakePedalSwitchNOSts : 36|1@0+ (1,0) [0|1] "-"  SGW
 SG_ DriverDoorSts : 31|1@0+ (1,0) [0|1] "-"  ACM,IPC,SGW,MCM
 SG_ FrontWiperMoveSts : 42|1@0+ (1,0) [0|1] ""  ACM,MCM
 SG_ FuelLevel : 7|8@0+ (1,0) [0|255] "%"  SGW
 SG_ FuelLevelFailSts : 15|1@0+ (1,0) [0|1] "-"  SGW
 SG_ IMMOCodeWarningLightSts : 14|7@0+ (1,0) [0|18] "-"  IPC
 SG_ LHRDoorSts : 29|1@0+ (1,0) [0|1] "-"  ACM,IPC,MCM
 SG_ LowFuelWarningSts : 39|1@0+ (1,0) [0|1] "-"  IPC
 SG_ NightAndDaySensorFailSts : 33|1@0+ (1,0) [0|1] ""  IPC
 SG_ OperationalModeSts : 23|4@0+ (1,0) [0|15] ""  ACM,AMP,LBSS,SGW,MCM,RBSS,TTM,VTM
 SG_ ParkBrakeSts : 24|1@0+ (1,0) [0|1] "-"  LBSS,RBSS
 SG_ PowerModeSts : 19|2@0+ (1,0) [0|3] ""  ACM,AMP,SGW,MCM
 SG_ PsngrDoorSts : 30|1@0+ (1,0) [0|1] "-"  ACM,IPC,SGW,MCM
 SG_ RainSensorFailSts : 38|1@0+ (1,0) [0|1] "-"  IPC
 SG_ RHatchSts : 35|1@0+ (1,0) [0|1] "-"  ACM,IPC,SGW,MCM
 SG_ RHRDoorSts : 28|1@0+ (1,0) [0|1] "-"  ACM,IPC,MCM
 SG_ StopStartActivationSts : 32|2@0+ (1,0) [0|3] ""  IPC
 SG_ StopStartVisualizationCode : 46|3@0+ (1,0) [0|7] ""  IPC
 SG_ SysEOLSts : 34|1@0+ (1,0) [0|1] "-"  IPC
 SG_ WarningKeyInSts : 37|1@0+ (1,0) [0|1] ""  IPC

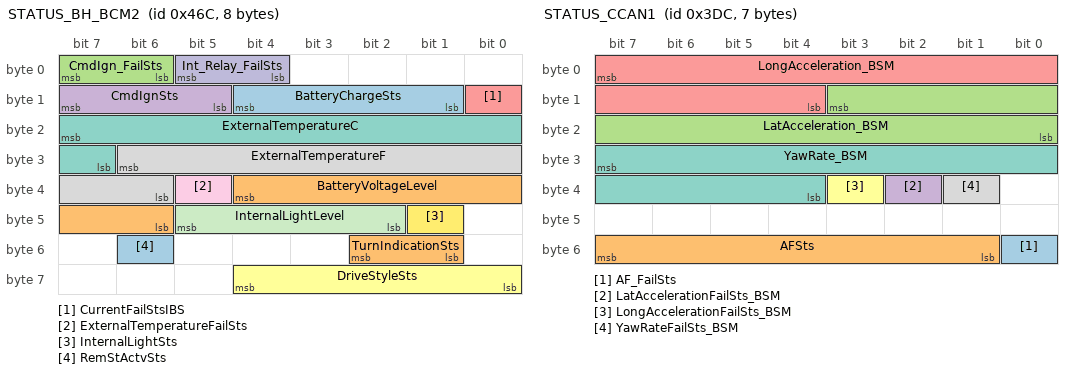
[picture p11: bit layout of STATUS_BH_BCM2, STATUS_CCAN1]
BO_ 1132 STATUS_BH_BCM2: 8 BCM
 SG_ BatteryChargeSts : 12|4@0+ (5,40) [40|110] "%"  Vector__XXX
 SG_ BatteryVoltageLevel : 36|7@0+ (0.16,0) [0|18] "Volt"  ACM,IPC,LBSS,MCM,RBSS
 SG_ CmdIgn_FailSts : 7|2@0+ (1,0) [0|3] ""  ACM,AMP,LBSS,SGW,MCM,RBSS,TTM,VTM
 SG_ CmdIgnSts : 15|3@0+ (1,0) [0|7] ""  ACM,AMP,LBSS,SGW,MCM,RBSS,TTM,VTM
 SG_ CurrentFailStsIBS : 8|1@0+ (1,0) [0|1] "-"  Vector__XXX
 SG_ DriveStyleSts : 60|5@0+ (1,0) [0|31] "-"  SGW
 SG_ ExternalTemperatureC : 23|9@0+ (0.5,-85) [-85|170] "°C"  ACM,IPC,SGW,MCM
 SG_ ExternalTemperatureF : 30|9@0+ (1,-121) [-121|389] "°F"  IPC,SGW
 SG_ ExternalTemperatureFailSts : 37|1@0+ (1,0) [0|1] "-"  ACM,IPC,SGW,MCM
 SG_ Int_Relay_FailSts : 5|2@0+ (1,0) [0|3] ""  Vector__XXX
 SG_ InternalLightLevel : 45|4@0+ (1,0) [0|15] ""  ACM,SGW,MCM
 SG_ InternalLightSts : 41|1@0+ (1,0) [0|1] ""  ACM,LBSS,SGW,MCM,RBSS
 SG_ RemStActvSts : 54|1@0+ (1,0) [0|1] ""  ACM,SGW,MCM
 SG_ TurnIndicationSts : 50|2@0+ (1,0) [0|3] ""  LBSS,RBSS

BO_ 1128 STATUS_BH_IPC: 2 IPC
 SG_ ClusterLightSts : 5|1@0+ (1,0) [0|1] ""  BCM
 SG_ SPM_Mode_Selection : 14|3@0+ (1,0) [0|3] "-"  BCM

BO_ 988 STATUS_CCAN1: 7 BCM
 SG_ AF_FailSts : 48|1@0+ (1,0) [0|1] ""  SGW
 SG_ AFSts : 55|7@0+ (0.1,8) [8|20.7] ""  SGW
 SG_ LatAcceleration_BSM : 11|12@0+ (0.02,-40.96) [-40.96|40.92] "m/s^2"  SGW
 SG_ LatAccelerationFailSts_BSM : 34|1@0+ (1,0) [0|1] "-"  SGW
 SG_ LongAcceleration_BSM : 7|12@0+ (0.02,-40.96) [-40.96|40.92] "m/s^2"  SGW
 SG_ LongAccelerationFailSts_BSM : 35|1@0+ (1,0) [0|1] "-"  SGW
 SG_ YawRate_BSM : 31|12@0+ (0.08,-163.84) [-163.84|163.68] "deg/s"  LBSS,SGW,RBSS
 SG_ YawRateFailSts_BSM : 33|1@0+ (1,0) [0|1] "-"  LBSS,SGW,RBSS

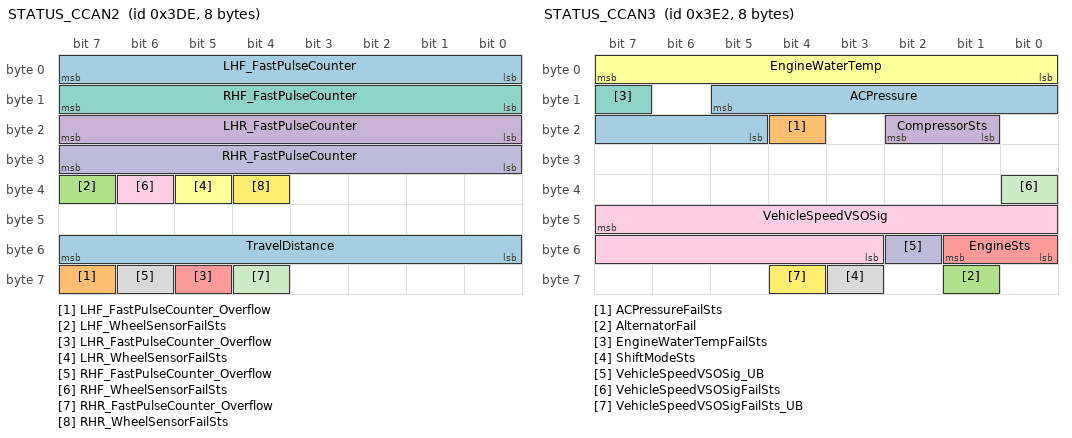
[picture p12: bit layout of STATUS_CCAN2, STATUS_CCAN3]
BO_ 990 STATUS_CCAN2: 8 BCM
 SG_ LHF_FastPulseCounter : 7|8@0+ (1,0) [0|255] "pulse"  SGW
 SG_ LHF_FastPulseCounter_Overflow : 63|1@0+ (1,0) [0|1] "-"  SGW
 SG_ LHF_WheelSensorFailSts : 39|1@0+ (1,0) [0|1] "-"  SGW
 SG_ LHR_FastPulseCounter : 23|8@0+ (1,0) [0|255] "pulse"  SGW
 SG_ LHR_FastPulseCounter_Overflow : 61|1@0+ (1,0) [0|1] "-"  SGW
 SG_ LHR_WheelSensorFailSts : 37|1@0+ (1,0) [0|1] "-"  SGW
 SG_ RHF_FastPulseCounter : 15|8@0+ (1,0) [0|255] "pulse"  SGW
 SG_ RHF_FastPulseCounter_Overflow : 62|1@0+ (1,0) [0|1] "-"  SGW
 SG_ RHF_WheelSensorFailSts : 38|1@0+ (1,0) [0|1] "-"  SGW
 SG_ RHR_FastPulseCounter : 31|8@0+ (1,0) [0|255] "pulse"  SGW
 SG_ RHR_FastPulseCounter_Overflow : 60|1@0+ (1,0) [0|1] "-"  SGW
 SG_ RHR_WheelSensorFailSts : 36|1@0+ (1,0) [0|1] "-"  SGW
 SG_ TravelDistance : 55|8@0+ (1,0) [0|255] "m"  SGW

BO_ 994 STATUS_CCAN3: 8 BCM
 SG_ ACPressure : 13|9@0+ (0.1,0) [0|40] "bar"  ACM,MCM
 SG_ ACPressureFailSts : 20|1@0+ (1,0) [0|1] ""  ACM,MCM
 SG_ AlternatorFail : 57|1@0+ (1,0) [0|1] ""  ACM,MCM
 SG_ CompressorSts : 18|2@0+ (1,0) [0|3] ""  ACM,SGW,MCM
 SG_ EngineSts : 49|2@0+ (1,0) [0|3] ""  ACM,AMP,LBSS,SGW,MCM,RBSS,TTM,VTM
 SG_ EngineWaterTemp : 7|8@0+ (1,-40) [-40|215] "°C"  ACM,SGW,MCM
 SG_ EngineWaterTempFailSts : 15|1@0+ (1,0) [0|1] "-"  ACM,SGW,MCM
 SG_ ShiftModeSts : 59|1@0+ (1,0) [0|1] ""  SGW
 SG_ VehicleSpeedVSOSig : 47|13@0+ (0.0625,0) [0|511.9375] "Km/h"  ACM,AMP,LBSS,SGW,MCM,RBSS,TTM,VTM
 SG_ VehicleSpeedVSOSig_UB : 50|1@0+ (1,0) [0|1] ""  VTM
 SG_ VehicleSpeedVSOSigFailSts : 32|1@0+ (1,0) [0|1] ""  ACM,AMP,LBSS,SGW,MCM,RBSS,TTM,VTM
 SG_ VehicleSpeedVSOSigFailSts_UB : 60|1@0+ (1,0) [0|1] ""  VTM

BO_ 996 STATUS_CCAN4: 8 BCM
 SG_ DPFSts : 41|1@0+ (1,0) [0|1] ""  SGW
 SG_ FuelConsumption_GAG : 31|16@0+ (0.0022,0) [0|144.1748] "litres/hour"  SGW
 SG_ GearShiftIndication : 55|2@0+ (1,0) [0|3] "-"  SGW
 SG_ OilLifeSts : 49|2@0+ (1,0) [0|3] ""  SGW
 SG_ ReverseGearSts : 62|2@0+ (1,0) [0|3] ""  LBSS,SGW,RBSS,TTM

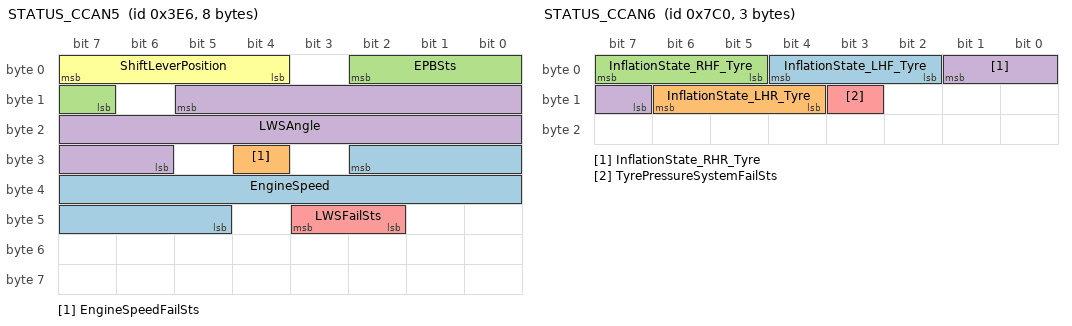
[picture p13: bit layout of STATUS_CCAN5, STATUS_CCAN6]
BO_ 998 STATUS_CCAN5: 8 BCM
 SG_ EngineSpeed : 26|14@0+ (1,0) [0|16382] "1/min"  ACM,SGW,MCM
 SG_ EngineSpeedFailSts : 28|1@0+ (1,0) [0|1] ""  ACM,SGW,MCM
 SG_ EPBSts : 2|4@0+ (1,0) [0|14] ""  LBSS,RBSS
 SG_ LWSAngle : 13|16@0+ (0.1,-720) [-720|720] "°"  LBSS,RBSS
 SG_ LWSFailSts : 43|2@0+ (1,0) [0|3] ""  LBSS,RBSS
 SG_ ShiftLeverPosition : 7|4@0+ (1,0) [0|15] ""  LBSS,SGW,RBSS

BO_ 1984 STATUS_CCAN6: 3 BCM
 SG_ InflationState_LHF_Tyre : 4|3@0+ (1,0) [0|4] "-"  SGW
 SG_ InflationState_LHR_Tyre : 14|3@0+ (1,0) [0|4] "-"  SGW
 SG_ InflationState_RHF_Tyre : 7|3@0+ (1,0) [0|4] "-"  SGW
 SG_ InflationState_RHR_Tyre : 1|3@0+ (1,0) [0|4] "-"  SGW
 SG_ TyrePressureSystemFailSts : 11|1@0+ (1,0) [0|1] "-"  SGW

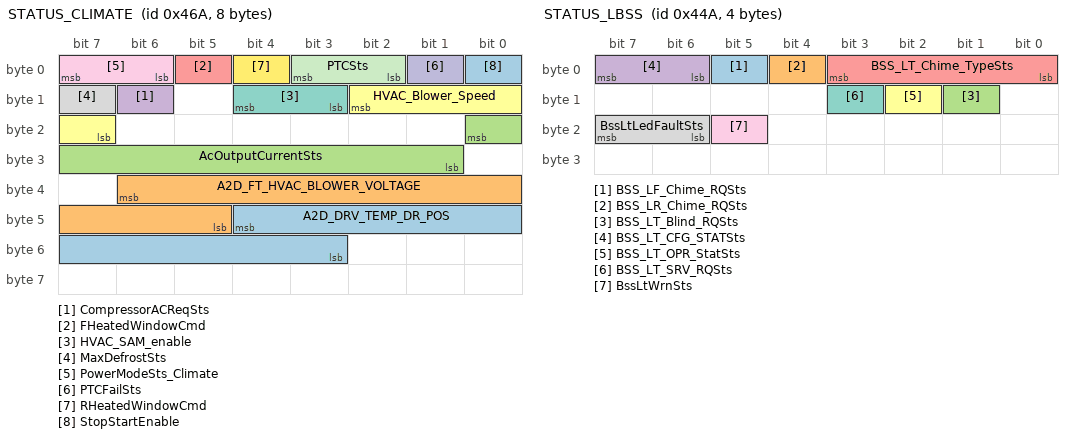
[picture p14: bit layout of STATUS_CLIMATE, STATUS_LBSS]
BO_ 1130 STATUS_CLIMATE: 8 ACM
 SG_ A2D_DRV_TEMP_DR_POS : 44|10@0+ (0.0048828125,0) [0|4.9951171875] "Volt"  BCM
 SG_ A2D_FT_HVAC_BLOWER_VOLTAGE : 38|10@0+ (0.0048828125,0) [0|4.9951171875] "Volt"  BCM
 SG_ AcOutputCurrentSts : 16|8@0+ (0.008,0) [0|2.04] "A"  BCM
 SG_ CompressorACReqSts : 14|1@0+ (1,0) [0|1] "-"  BCM
 SG_ FHeatedWindowCmd : 5|1@0+ (1,0) [0|1] "-"  BCM
 SG_ HVAC_Blower_Speed : 10|4@0+ (1,0) [0|14] ""  Vector__XXX
 SG_ HVAC_SAM_enable : 12|2@0+ (1,0) [0|3] "-"  BCM
 SG_ MaxDefrostSts : 15|1@0+ (1,0) [0|1] "-"  BCM
 SG_ PowerModeSts_Climate : 7|2@0+ (1,0) [0|3] "-"  BCM
 SG_ PTCFailSts : 1|1@0+ (1,0) [0|1] "-"  BCM
 SG_ PTCSts : 3|2@0+ (1,0) [0|3] "-"  BCM
 SG_ RHeatedWindowCmd : 4|1@0+ (1,0) [0|1] "-"  BCM
 SG_ StopStartEnable : 0|1@0+ (1,0) [0|1] "-"  BCM

BO_ 1098 STATUS_LBSS: 4 LBSS
 SG_ BSS_LF_Chime_RQSts : 5|1@0+ (1,0) [0|1] ""  AMP,IPC,SGW,RBSS
 SG_ BSS_LR_Chime_RQSts : 4|1@0+ (1,0) [0|1] ""  AMP,IPC,SGW,RBSS
 SG_ BSS_LT_Blind_RQSts : 9|1@0+ (1,0) [0|1] ""  IPC
 SG_ BSS_LT_CFG_STATSts : 7|2@0+ (1,0) [0|2] ""  AMP,IPC,SGW,RBSS
 SG_ BSS_LT_Chime_TypeSts : 3|4@0+ (1,0) [0|14] ""  AMP,IPC,SGW,RBSS
 SG_ BSS_LT_OPR_StatSts : 10|1@0+ (1,0) [0|1] ""  IPC
 SG_ BSS_LT_SRV_RQSts : 11|1@0+ (1,0) [0|1] ""  IPC
 SG_ BssLtLedFaultSts : 23|2@0+ (1,0) [0|3] ""  RBSS
 SG_ BssLtWrnSts : 21|1@0+ (1,0) [0|1] ""  RBSS

BO_ 1462 STATUS_LIN: 8 BCM
 SG_ DynamicGridFailSts : 2|1@0+ (1,0) [0|1] ""  SGW
 SG_ DynamicGridSts : 3|1@0+ (1,0) [0|1] ""  SGW
 SG_ SWSError : 17|1@0+ (1,0) [0|1] ""  IPC,SGW

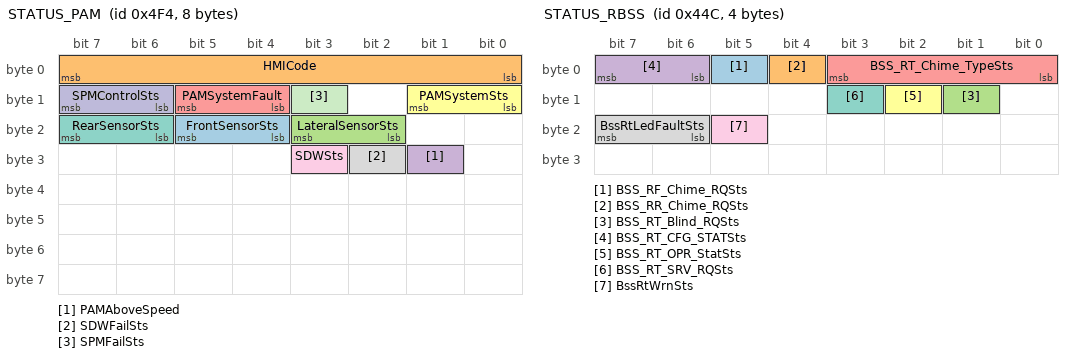
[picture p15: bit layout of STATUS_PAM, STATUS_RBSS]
BO_ 1268 STATUS_PAM: 8 BCM
 SG_ FrontSensorSts : 21|2@0+ (1,0) [0|3] ""  IPC
 SG_ HMICode : 7|8@0+ (1,0) [0|255] "-"  IPC
 SG_ LateralSensorSts : 19|2@0+ (1,0) [0|3] ""  IPC
 SG_ PAMAboveSpeed : 25|1@0+ (1,0) [0|1] ""  IPC
 SG_ PAMSystemFault : 13|2@0+ (1,0) [0|3] "-"  IPC
 SG_ PAMSystemSts : 9|2@0+ (1,0) [0|3] ""  IPC
 SG_ RearSensorSts : 23|2@0+ (1,0) [0|3] ""  IPC
 SG_ SDWFailSts : 26|1@0+ (1,0) [0|1] ""  IPC
 SG_ SDWSts : 27|1@0+ (1,0) [0|1] ""  IPC
 SG_ SPMControlSts : 15|2@0+ (1,0) [0|1] ""  IPC
 SG_ SPMFailSts : 11|1@0+ (1,0) [0|1] "-"  IPC

BO_ 1100 STATUS_RBSS: 4 RBSS
 SG_ BSS_RF_Chime_RQSts : 5|1@0+ (1,0) [0|1] ""  AMP,IPC,LBSS,SGW
 SG_ BSS_RR_Chime_RQSts : 4|1@0+ (1,0) [0|1] ""  AMP,IPC,LBSS,SGW
 SG_ BSS_RT_Blind_RQSts : 9|1@0+ (1,0) [0|1] ""  IPC
 SG_ BSS_RT_CFG_STATSts : 7|2@0+ (1,0) [0|2] ""  AMP,IPC,LBSS,SGW
 SG_ BSS_RT_Chime_TypeSts : 3|4@0+ (1,0) [0|14] ""  AMP,IPC,LBSS,SGW
 SG_ BSS_RT_OPR_StatSts : 10|1@0+ (1,0) [0|1] ""  IPC
 SG_ BSS_RT_SRV_RQSts : 11|1@0+ (1,0) [0|1] ""  IPC
 SG_ BssRtLedFaultSts : 23|2@0+ (1,0) [0|3] ""  LBSS
 SG_ BssRtWrnSts : 21|1@0+ (1,0) [0|1] ""  LBSS

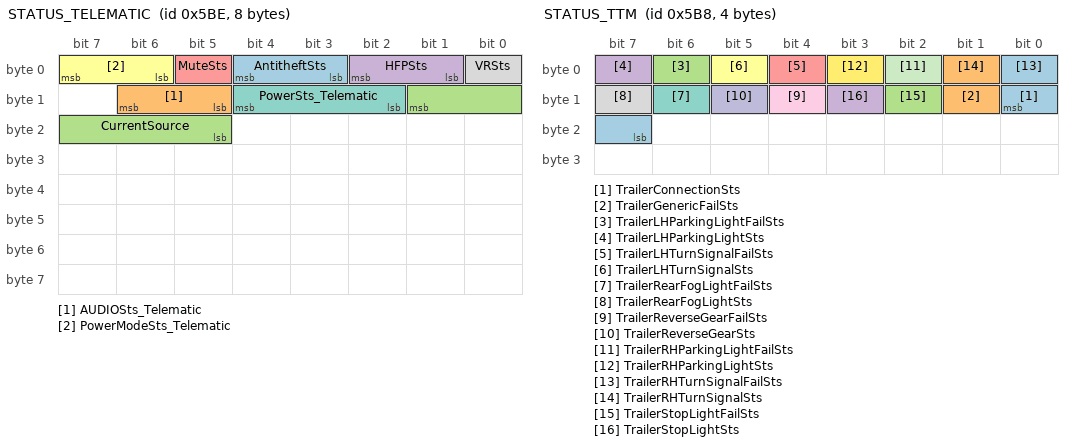
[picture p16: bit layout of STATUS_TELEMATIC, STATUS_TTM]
BO_ 1470 STATUS_TELEMATIC: 8 SGW
 SG_ AntitheftSts : 4|2@0+ (1,0) [0|3] "-"  Vector__XXX
 SG_ AUDIOSts_Telematic : 14|2@0+ (1,0) [0|3] "-"  AMP,BCM,IPC
 SG_ CurrentSource : 9|5@0+ (1,0) [0|31] "-"  AMP
 SG_ HFPSts : 2|2@0+ (1,0) [0|3] "-"  Vector__XXX
 SG_ MuteSts : 5|1@0+ (1,0) [0|1] "-"  AMP
 SG_ PowerModeSts_Telematic : 7|2@0+ (1,0) [0|3] "-"  BCM
 SG_ PowerSts_Telematic : 12|3@0+ (1,0) [0|7] "-"  AMP
 SG_ VRSts : 0|1@0+ (1,0) [0|1] "-"  Vector__XXX

BO_ 1464 STATUS_TTM: 4 TTM
 SG_ TrailerConnectionSts : 8|2@0+ (1,0) [0|3] ""  BCM,LBSS,RBSS
 SG_ TrailerGenericFailSts : 9|1@0+ (1,0) [0|1] ""  BCM,IPC,LBSS,RBSS
 SG_ TrailerLHParkingLightFailSts : 6|1@0+ (1,0) [0|1] ""  IPC
 SG_ TrailerLHParkingLightSts : 7|1@0+ (1,0) [0|1] ""  Vector__XXX
 SG_ TrailerLHTurnSignalFailSts : 4|1@0+ (1,0) [0|1] ""  BCM,IPC
 SG_ TrailerLHTurnSignalSts : 5|1@0+ (1,0) [0|1] ""  Vector__XXX
 SG_ TrailerRearFogLightFailSts : 14|1@0+ (1,0) [0|1] ""  Vector__XXX
 SG_ TrailerRearFogLightSts : 15|1@0+ (1,0) [0|1] ""  Vector__XXX
 SG_ TrailerReverseGearFailSts : 12|1@0+ (1,0) [0|1] ""  Vector__XXX
 SG_ TrailerReverseGearSts : 13|1@0+ (1,0) [0|1] ""  Vector__XXX
 SG_ TrailerRHParkingLightFailSts : 2|1@0+ (1,0) [0|1] ""  IPC
 SG_ TrailerRHParkingLightSts : 3|1@0+ (1,0) [0|1] ""  Vector__XXX
 SG_ TrailerRHTurnSignalFailSts : 0|1@0+ (1,0) [0|1] ""  BCM,IPC
 SG_ TrailerRHTurnSignalSts : 1|1@0+ (1,0) [0|1] ""  Vector__XXX
 SG_ TrailerStopLightFailSts : 10|1@0+ (1,0) [0|1] ""  IPC
 SG_ TrailerStopLightSts : 11|1@0+ (1,0) [0|1] ""  Vector__XXX

BO_ 846 STATUS_VTM: 2 VTM
 SG_ VTMFailSts : 5|1@0+ (1,0) [0|1] "-"  Vector__XXX
 SG_ VTMLightFailSts : 4|1@0+ (1,0) [0|1] "-"  Vector__XXX
 SG_ VTMSts : 7|2@0+ (1,0) [0|3] ""  Vector__XXX

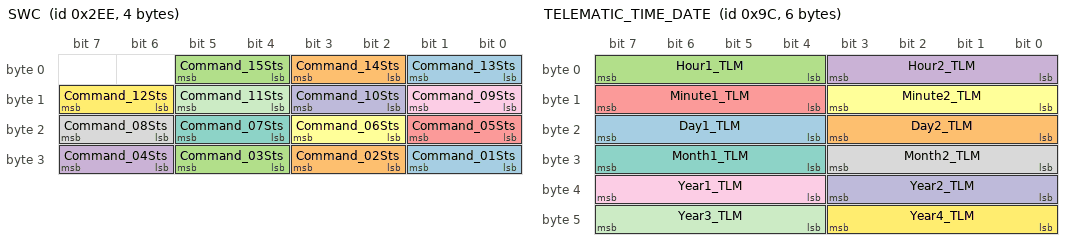
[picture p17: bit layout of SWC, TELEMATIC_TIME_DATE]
BO_ 750 SWC: 4 BCM
 SG_ Command_01Sts : 25|2@0+ (1,0) [0|2] ""  SGW
 SG_ Command_02Sts : 27|2@0+ (1,0) [0|2] ""  SGW
 SG_ Command_03Sts : 29|2@0+ (1,0) [0|2] ""  SGW
 SG_ Command_04Sts : 31|2@0+ (1,0) [0|2] ""  SGW
 SG_ Command_05Sts : 17|2@0+ (1,0) [0|2] ""  SGW
 SG_ Command_06Sts : 19|2@0+ (1,0) [0|2] ""  SGW
 SG_ Command_07Sts : 21|2@0+ (1,0) [0|2] ""  SGW
 SG_ Command_08Sts : 23|2@0+ (1,0) [0|2] ""  SGW
 SG_ Command_09Sts : 9|2@0+ (1,0) [0|2] ""  SGW
 SG_ Command_10Sts : 11|2@0+ (1,0) [0|2] ""  SGW
 SG_ Command_11Sts : 13|2@0+ (1,0) [0|2] ""  IPC
 SG_ Command_12Sts : 15|2@0+ (1,0) [0|2] ""  IPC
 SG_ Command_13Sts : 1|2@0+ (1,0) [0|2] ""  IPC
 SG_ Command_14Sts : 3|2@0+ (1,0) [0|2] ""  IPC
 SG_ Command_15Sts : 5|2@0+ (1,0) [0|2] ""  IPC

BO_ 144 TELEMATIC_DISPLAY_INFO: 8 SGW
 SG_ FrameNumber : 2|5@0+ (1,0) [0|31] "-"  IPC
 SG_ InfoCode : 13|6@0+ (1,0) [0|63] "-"  IPC
 SG_ TotalFrameNumber : 7|5@0+ (1,0) [0|31] "-"  IPC
 SG_ UTF_Text_1 : 23|16@0+ (1,0) [0|65535] "-"  IPC
 SG_ UTF_Text_2 : 39|16@0+ (1,0) [0|65535] "-"  IPC
 SG_ UTF_Text_3 : 55|16@0+ (1,0) [0|65535] "-"  IPC

BO_ 136 TELEMATIC_NAV_INFO: 5 SGW
 SG_ Direction : 17|7@0+ (1,0) [0|127] "-"  IPC
 SG_ DistToTurn : 7|20@0+ (1,0) [0|1048575] "-"  IPC
 SG_ LastAnnouncement : 39|1@0+ (1,0) [0|1] "-"  IPC
 SG_ ResolutionDistToTurn : 19|2@0+ (1,0) [0|2] "-"  IPC
 SG_ Unit : 26|3@0+ (1,0) [0|6] "-"  IPC

BO_ 156 TELEMATIC_TIME_DATE: 6 SGW
 SG_ Day1_TLM : 23|4@0+ (1,0) [0|3] "-"  IPC
 SG_ Day2_TLM : 19|4@0+ (1,0) [0|9] "-"  IPC
 SG_ Hour1_TLM : 7|4@0+ (1,0) [0|2] "-"  IPC
 SG_ Hour2_TLM : 3|4@0+ (1,0) [0|9] "-"  IPC
 SG_ Minute1_TLM : 15|4@0+ (1,0) [0|5] "-"  IPC
 SG_ Minute2_TLM : 11|4@0+ (1,0) [0|9] "-"  IPC
 SG_ Month1_TLM : 31|4@0+ (1,0) [0|1] "-"  IPC
 SG_ Month2_TLM : 27|4@0+ (1,0) [0|9] "-"  IPC
 SG_ Year1_TLM : 39|4@0+ (1,0) [0|2] "-"  IPC
 SG_ Year2_TLM : 35|4@0+ (1,0) [0|9] "-"  IPC
 SG_ Year3_TLM : 47|4@0+ (1,0) [0|9] "-"  IPC
 SG_ Year4_TLM : 43|4@0+ (1,0) [0|9] "-"  IPC

BO_ 158 TELEMATIC_VEHICLE_SETUP: 8 SGW
 SG_ AmbientLightingLevel_Req : 50|4@0+ (1,0) [0|15] ""  IPC
 SG_ AutoHighBeamEnable_Req : 21|1@0+ (1,0) [0|1] "-"  IPC
 SG_ AutoParkBrake_Req : 33|1@0+ (1,0) [0|1] ""  IPC
 SG_ BSDEnable_Req : 30|2@0+ (1,0) [0|2] "-"  IPC
 SG_ ConsumptionUnit_Req : 15|3@0+ (1,0) [0|3] "-"  IPC
 SG_ CorneringEnable_Req : 18|1@0+ (1,0) [0|1] "-"  IPC
 SG_ DistanceUnit_Req : 10|1@0+ (1,0) [0|1] "-"  IPC
 SG_ DRLEnable_Req : 12|1@0+ (1,0) [0|1] "-"  IPC
 SG_ DynamicGrid_Req : 24|1@0+ (1,0) [0|1] ""  BCM
 SG_ ExternalLightSensorLevel_Req : 9|2@0+ (1,0) [0|3] "-"  IPC
 SG_ GreetingLightsEnable_Req : 11|1@0+ (1,0) [0|1] "-"  IPC
 SG_ HourMode_Req : 23|1@0+ (1,0) [0|1] "-"  IPC
 SG_ LanguageSelection_Req : 7|8@0+ (1,0) [0|255] "-"  IPC
 SG_ PamAlertMode_Req : 43|2@0+ (1,0) [0|3] ""  IPC
 SG_ PamChimeVolumeFront_Req : 45|2@0+ (1,0) [0|3] ""  IPC
 SG_ PamChimeVolumeRear_Req : 41|2@0+ (1,0) [0|3] ""  IPC
 SG_ PassiveEntry_Req : 28|1@0+ (1,0) [0|1] ""  IPC
 SG_ PhoneRepetition_Req : 47|1@0+ (1,0) [0|1] ""  Vector__XXX
 SG_ RainSensorLevel_Req : 22|1@0+ (1,0) [0|1] "-"  IPC
 SG_ RemoteDoorUnlock_Req : 34|1@0+ (1,0) [0|1] ""  IPC
 SG_ ResetTripA_Req : 16|1@0+ (1,0) [0|1] "-"  IPC
 SG_ ResetTripB_Req : 31|1@0+ (1,0) [0|1] "-"  IPC
 SG_ Sdw_Req : 55|2@0+ (1,0) [0|3] ""  IPC
 SG_ SdwChimeVolume_Req : 53|2@0+ (1,0) [0|3] ""  IPC
 SG_ SoundHornLock_Req : 37|2@0+ (1,0) [0|3] ""  IPC
 SG_ SoundHornRemoteStart_Req : 35|1@0+ (1,0) [0|1] ""  IPC
 SG_ SpeedLockDoorEnable_Req : 20|1@0+ (1,0) [0|1] "-"  IPC
 SG_ TemperatureUnit_Req : 19|1@0+ (1,0) [0|1] "-"  IPC

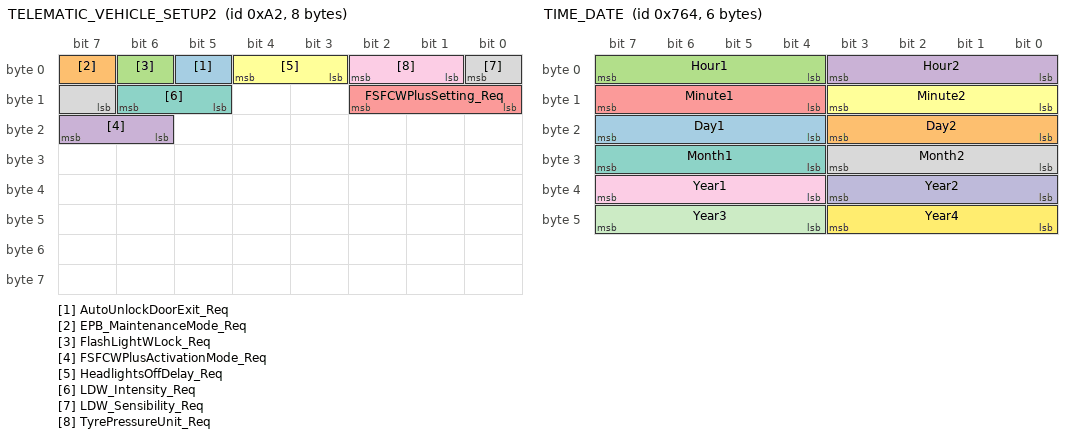
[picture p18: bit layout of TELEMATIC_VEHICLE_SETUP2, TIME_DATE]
BO_ 162 TELEMATIC_VEHICLE_SETUP2: 8 SGW
 SG_ AutoUnlockDoorExit_Req : 5|1@0+ (1,0) [0|1] "-"  IPC
 SG_ EPB_MaintenanceMode_Req : 7|1@0+ (1,0) [0|1] "-"  IPC
 SG_ FlashLightWLock_Req : 6|1@0+ (1,0) [0|1] "-"  IPC
 SG_ FSFCWPlusActivationMode_Req : 23|2@0+ (1,0) [0|3] "-"  IPC
 SG_ FSFCWPlusSetting_Req : 10|3@0+ (1,0) [0|7] "-"  IPC
 SG_ HeadlightsOffDelay_Req : 4|2@0+ (1,0) [0|3] "-"  IPC
 SG_ LDW_Intensity_Req : 14|2@0+ (1,0) [0|3] "-"  IPC
 SG_ LDW_Sensibility_Req : 0|2@0+ (1,0) [0|3] "-"  IPC
 SG_ TyrePressureUnit_Req : 2|2@0+ (1,0) [0|3] "-"  IPC

BO_ 1892 TIME_DATE: 6 IPC
 SG_ Day1 : 23|4@0+ (1,0) [0|9] "-"  SGW
 SG_ Day2 : 19|4@0+ (1,0) [0|9] "-"  SGW
 SG_ Hour1 : 7|4@0+ (1,0) [0|9] "-"  SGW
 SG_ Hour2 : 3|4@0+ (1,0) [0|9] "-"  SGW
 SG_ Minute1 : 15|4@0+ (1,0) [0|9] "-"  SGW
 SG_ Minute2 : 11|4@0+ (1,0) [0|9] "-"  SGW
 SG_ Month1 : 31|4@0+ (1,0) [0|9] "-"  SGW
 SG_ Month2 : 27|4@0+ (1,0) [0|9] "-"  SGW
 SG_ Year1 : 39|4@0+ (1,0) [0|9] "-"  SGW
 SG_ Year2 : 35|4@0+ (1,0) [0|9] "-"  SGW
 SG_ Year3 : 47|4@0+ (1,0) [0|9] "-"  SGW
 SG_ Year4 : 43|4@0+ (1,0) [0|9] "-"  SGW

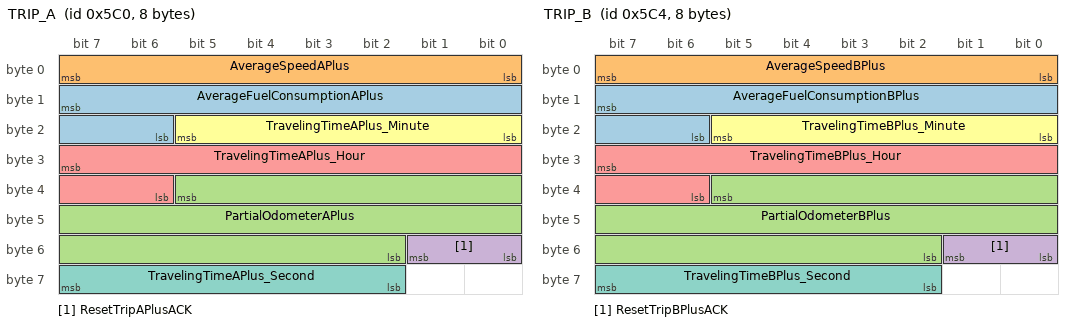
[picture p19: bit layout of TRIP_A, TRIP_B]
BO_ 1472 TRIP_A: 8 IPC
 SG_ AverageFuelConsumptionAPlus : 15|10@0+ (0.1,0) [0|102.3] "km/l or l/100km"  SGW
 SG_ AverageSpeedAPlus : 7|8@0+ (1,0) [0|255] "km/h or mph"  SGW
 SG_ PartialOdometerAPlus : 37|20@0+ (0.1,0) [0|104857.5] "km or mi."  SGW
 SG_ ResetTripAPlusACK : 49|2@0+ (1,0) [0|3] "-"  SGW
 SG_ TravelingTimeAPlus_Hour : 31|10@0+ (1,0) [0|1023] "Hour"  SGW
 SG_ TravelingTimeAPlus_Minute : 21|6@0+ (1,0) [0|63] "Minute"  SGW
 SG_ TravelingTimeAPlus_Second : 63|6@0+ (1,0) [0|63] "Second"  SGW

BO_ 1888 TRIP_A_B: 6 IPC
 SG_ AutonomyDistance : 39|11@0+ (1,0) [0|2047] "km"  SGW
 SG_ InstantaneousFuelConsumption1 : 7|4@0+ (1,0) [0|15] "-"  SGW
 SG_ InstantaneousFuelConsumption2 : 3|4@0+ (1,0) [0|15] "-"  SGW
 SG_ InstantaneousFuelConsumption3 : 15|4@0+ (1,0) [0|15] "-"  SGW
 SG_ TotalOdometer : 11|20@0+ (1,0) [0|1048575] "km"  ACM,AMP,LBSS,SGW,MCM,RBSS,TTM

BO_ 1476 TRIP_B: 8 IPC
 SG_ AverageFuelConsumptionBPlus : 15|10@0+ (0.1,0) [0|102.3] "km/l or l/100km"  SGW
 SG_ AverageSpeedBPlus : 7|8@0+ (1,0) [0|255] "km/h or mph"  SGW
 SG_ PartialOdometerBPlus : 37|20@0+ (0.1,0) [0|104857.5] "km or mi."  SGW
 SG_ ResetTripBPlusACK : 49|2@0+ (1,0) [0|3] "-"  SGW
 SG_ TravelingTimeBPlus_Hour : 31|10@0+ (1,0) [0|1023] "Hour"  SGW
 SG_ TravelingTimeBPlus_Minute : 21|6@0+ (1,0) [0|63] "Minute"  SGW
 SG_ TravelingTimeBPlus_Second : 63|6@0+ (1,0) [0|63] "Second"  SGW

BO_ 748 U_CONN_REQ: 5 Vector__XXX
 SG_ UConnReq : 7|5@0+ (1,0) [0|31] "-"  BCM
 SG_ UConnReqAuthCode : 2|16@0+ (1,0) [0|65535] "-"  BCM
 SG_ UConnReqFOBNum : 18|4@0+ (1,0) [0|15] "-"  BCM

BO_ 1976 U_CONN_SEED: 4 BCM
 SG_ UConnSeed1 : 31|8@0+ (1,0) [0|255] ""  Vector__XXX
 SG_ UConnSeed2 : 23|8@0+ (1,0) [0|255] ""  Vector__XXX
 SG_ UConnSeed3 : 15|8@0+ (1,0) [0|255] ""  Vector__XXX
 SG_ UConnSeed4 : 7|8@0+ (1,0) [0|255] ""  Vector__XXX

BO_ 992 VIN: 8 BCM
 SG_ VIN_DATA : 15|56@0+ (1,0) [0|7.20575940379279E+016] ""  ACM,AMP,LBSS,SGW,MCM,RBSS,TTM
 SG_ VIN_MSG : 1|2@0+ (1,0) [0|3] ""  ACM,AMP,LBSS,SGW,MCM,RBSS,TTM

BO_ 152 VTM_CODE_REQUEST: 8 BCM
 SG_ ControlEncoding : 7|8@0+ (1,0) [0|255] "-"  VTM
 SG_ F11 : 47|8@0+ (1,0) [0|255] "-"  VTM
 SG_ F12 : 55|8@0+ (1,0) [0|255] "-"  VTM
 SG_ Rnd1 : 15|8@0+ (1,0) [0|255] "-"  VTM
 SG_ Rnd2 : 23|8@0+ (1,0) [0|255] "-"  VTM
 SG_ Rnd3 : 31|8@0+ (1,0) [0|255] "-"  VTM
 SG_ Rnd4 : 39|8@0+ (1,0) [0|255] "-"  VTM

BO_ 154 VTM_CODE_RESPONSE: 4 VTM
 SG_ BlockSts : 31|2@0+ (1,0) [3|3] "-"  BCM
 SG_ ControlEncoding : 7|8@0+ (1,0) [0|255] "-"  BCM
 SG_ G21 : 15|8@0+ (1,0) [0|255] "-"  BCM
 SG_ G22 : 23|8@0+ (1,0) [0|255] "-"  BCM

BO_TX_BU_ 2651930634 : ACM,MCM;
BO_TX_BU_ 134 : ACM,MCM,MHM;
BO_TX_BU_ 2564554481 : DIAG_TEST,SGW;
BO_TX_BU_ 2564457457 : BCM,DIAG_TEST,SGW;
BO_TX_BU_ 2564462833 : BCM,DIAG_TEST,SGW;
BO_TX_BU_ 2564449009 : BCM,DIAG_TEST,SGW;
BO_TX_BU_ 2564449777 : BCM,DIAG_TEST,SGW;
BO_TX_BU_ 2564442865 : BCM,DIAG_TEST,SGW;
BO_TX_BU_ 2564473329 : BCM,DIAG_TEST,SGW;
BO_TX_BU_ 2564485528 : ACM,MCM;
BO_TX_BU_ 2654208010 : ACM,MCM;
BO_TX_BU_ 1130 : ACM,MCM;

CM_ SG_ 1474 PanicModeActive  "Panic Status";
CM_ SG_ 160 BCMFpsCommand  "The signal is used to command the FPS strategy actuation";
CM_ SG_ 160 BCMFpsConfirm  "The signal is used to confirm the FPS strategy command";
CM_ SG_ 160 BCMFpsFailSts  "This signal is used to give information of a fault present on the FPS sensing device .";
CM_ SG_ 134 FPS_Status_Request  "The signal is used to request the status of FPS system.";
CM_ SG_ 1478 AUD_LVLSts  "Audio level";
CM_ SG_ 1478 BAL_LVLSts  "Balance level [ P = right N = left ]";
CM_ SG_ 1478 BASS_LVLSts  "Bass range level";
CM_ SG_ 1478 DSS_ONSts  "Driver Surround Sound On/Off";
CM_ SG_ 1478 FD_LVLSts  "Fade level [ P = right N = left ]";
CM_ SG_ 1478 INFO1_AUD_ACT  "Information source 1 audio active";
CM_ SG_ 1478 INFO1_AUD_LEVEL  "Information source 1 audio level";
CM_ SG_ 1478 INFO1_AUD_TYPE  "Mono Audio Control Enable";
CM_ SG_ 1478 INFO2_AUD_ACT  "Information source 2 audio active";
CM_ SG_ 1478 INFO2_AUD_LEVEL  "Information source 2 audio level";
CM_ SG_ 1478 INFO2_AUD_TYPE  "Mono Audio Control Enable";
CM_ SG_ 1478 MID_LVLSts  "Mid range level";
CM_ SG_ 1478 SCV_LVLSts  "Speed controlled volume level";
CM_ SG_ 1478 TREB_LVLSts  "Treble range level";
CM_ SG_ 2564554481 N_PDU  "This signal is used for diagnostic purposes";
CM_ SG_ 2564457457 N_PDU  "This signal is used for diagnostic purposes";
CM_ SG_ 2564462833 N_PDU  "This signal is used for diagnostic purposes";
CM_ SG_ 2564449009 N_PDU  "This signal is used for diagnostic purposes";
CM_ SG_ 2564449777 N_PDU  "This signal is used for diagnostic purposes";
CM_ SG_ 2564442865 N_PDU  "This signal is used for diagnostic purposes";
CM_ SG_ 2564473329 N_PDU  "-";
CM_ SG_ 2564485507 N_PDU  "-";
CM_ SG_ 2564485528 N_PDU  "This signal is used for diagnostic purposes";
CM_ SG_ 2564485474 N_PDU  "-";
CM_ SG_ 2564485477 N_PDU  "-";
CM_ SG_ 2564485450 N_PDU  "-";
CM_ SG_ 2564485569 N_PDU  "-";
CM_ SG_ 852 AHBFeature  "This signal indicates the Auto High Beam Feature status";
CM_ SG_ 852 AlertLightsON  "This signal is used to activate an indication with buzzer when the user left the Lights ON at Ignition OFF";
CM_ SG_ 852 FHeatedWindowSts  "Used to indicate the Front heated window activation/deactivation status";
CM_ SG_ 852 L_TurnLightActivationSts  "Request of Left Turn Lights activation";
CM_ SG_ 852 R_TurnLightActivationSts  "Request of Right Turn Lights activation";
CM_ SG_ 852 RHeatedWindowSts  "Used to indicate the Rear heated window activation/deactivation status";
CM_ SG_ 852 StopLightSts  "Request of Stop Lights activation";
CM_ SG_ 1270 AHBFault  "HALF sends to the BCM the fault condition";
CM_ SG_ 1270 SensorBlinded  "This signal indicates the HALF state";
CM_ SG_ 146 SMS_PopUp  "Used to give information about the Popup-SMS visualization status";
CM_ SG_ 1468 AmbientLightingLevel  "This signal is used to give information about the Ambient Lighting Level selected";
CM_ SG_ 1468 AudioRepetition  "This signal is used to give information about the Audio Repetition selected";
CM_ SG_ 1468 AutoHighBeamEnable  "This signal is used to give information about the Auto High Beam feature selected";
CM_ SG_ 1468 AutomaticResetTripB  "This signal is used to give information about the Automatic Reset of Trip B selected";
CM_ SG_ 1468 AutoParkBrake  "This signal is used to give information about the Auto Park Brake selected";
CM_ SG_ 1468 AutoRelock  "This signal is used to give information about the Auto Relock feature selected";
CM_ SG_ 1468 BSDEnable  "This signal is used to give information about the Blind Spot Alert feature selected";
CM_ SG_ 1468 ConsumptionUnit  "This signal is used to give information about the Consumption Unit selected";
CM_ SG_ 1468 CorneringEnable  "This signal is used to give information about the Cornering Lights selected";
CM_ SG_ 1468 DistanceUnit  "This signal is used to give information about the Distance Unit selected";
CM_ SG_ 1468 DRLEnable  "This signal is used to give information about the DRL feature selected";
CM_ SG_ 1468 ExternalLightSensorLevel  "This signal is used to give information about the External Light Sensor Level selected";
CM_ SG_ 1468 GreetingLightsEnable  "This signal is used to give information about the Greeting Lights selected";
CM_ SG_ 1468 HourMode  "This signal is used to give information about the Hour Mode selected.";
CM_ SG_ 1468 LanguageSelection  "This signal is used to give information about the Language selected";
CM_ SG_ 1468 NavRepetition  "This signal is used to give information about the Navigation Repetition selected";
CM_ SG_ 1468 PamAlertMode  "This signal is used to give information about the PAM Alert Mode selected";
CM_ SG_ 1468 PamChimeVolumeFront  "This signal is used to give information about the PAM Chime Volume selected";
CM_ SG_ 1468 PamChimeVolumeRear  "This signal is used to give information about the PAM 8Ch Chime Volume selected";
CM_ SG_ 1468 PassiveEntry  "This signal is used to give information about the Passive Entry selected";
CM_ SG_ 1468 PhoneRepetition  "This signal is used to give information about the Phone Repetition selected";
CM_ SG_ 1468 RainSensorLevel  "This signal is used to give information about the Rain Sensor Level selected";
CM_ SG_ 1468 RemoteDoorUnlock  "This signal is used to give information about the Remote Door Unlock selected";
CM_ SG_ 1468 Sdw  "This signal is used to give information about the Side Distance Warning feature selected";
CM_ SG_ 1468 SdwChimeVolume  "This signal is used to give information about the SDW Chime Volume selected";
CM_ SG_ 1468 SoundHornLock  "This signal is used to give information about the Sound Horn with Lock selected";
CM_ SG_ 1468 SoundHornRemoteStart  "This signal is used to give information about the Sound Horn with Remote Start selected";
CM_ SG_ 1468 SpeedLockDoorEnable  "This signal is used to give information about the Autoclose feature selected";
CM_ SG_ 1468 TelematicSetupACK  "Used to give information about the acknowledge of the requested setup changes by telematic module.";
CM_ SG_ 1468 TemperatureUnit  "This signal is used to give information about the Temperature Unit selected";
CM_ SG_ 1486 AutoUnlockDoorExit  "This signal is used to give information about the Auto Unlock Door on Exit feature selected";
CM_ SG_ 1486 EPB_Maintenance_Fdbk  "It indicates the HMI state of the EPB Functionality for the Maintenance Procedure";
CM_ SG_ 1486 EPB_MaintenanceMode  "This signal is used to give information about the Maintenance Mode feature selected";
CM_ SG_ 1486 FlashLightWLock  "This signal is used to give information about the Flash Light With Lock selected";
CM_ SG_ 1486 FSFCWPlusActivationMode  "This signal is used to give information about the FSFCW Activation Mode setting";
CM_ SG_ 1486 FSFCWPlusSetting  "This signal is used to give information about the FSFCW setting";
CM_ SG_ 1486 HeadlightsOffDelay  "This signal is used to give information about the Headlights Off Delay selected";
CM_ SG_ 1486 LDW_Intensity  "This signal is used to give information about the LDW Intensity selected";
CM_ SG_ 1486 LDW_Sensibility  "This signal is used to give information about the LDW Sensibility selected";
CM_ SG_ 1486 TyrePressureUnit  "This signal is used to give information about the Tyre Pressure Unit selected";
CM_ SG_ 773 LbssSysBlockIndSts  "LBSS system indication status";
CM_ SG_ 773 LbssSysInterfIndSts  "LBSS system interference indication status";
CM_ SG_ 773 LbssSysSrvIndSts  "LBSS system service indication status";
CM_ SG_ 773 LbssTmpUnavIndSts  "LBSS system Temporarily unavailable indication status";
CM_ SG_ 950 Alert_CHF  "This signal indicates which arc shall be displayed in the central hand, front position of the car graphics.";
CM_ SG_ 950 Alert_CHR  "This signal indicates which arc shall be displayed in the central hand, rear position of the car graphics.";
CM_ SG_ 950 Alert_LHF  "This signal indicates which arc shall be displayed in the left hand, front position of the car graphics.";
CM_ SG_ 950 Alert_LHR  "This signal indicates which arc shall be displayed in the left hand, rear position of the car graphics.";
CM_ SG_ 950 Alert_RHF  "This signal indicates which arc shall be displayed in the right hand, front position of the car graphics.";
CM_ SG_ 950 Alert_RHR  "This signal indicates which arc shall be displayed in the right hand, rear position of the car graphics.";
CM_ SG_ 950 ChimeActivation_LHF  "This signal indicates the chime activation request for the left hand, front audio speaker, or rear hardwired buzzer.";
CM_ SG_ 950 ChimeActivation_LHR  "This signal indicates the chime activation request for the left hand, rear audio speaker, or rear hardwired buzzer.";
CM_ SG_ 950 ChimeActivation_RHF  "This signal indicates the chime activation request for the right hand, front audio speaker, or rear hardwired buzzer.";
CM_ SG_ 950 ChimeActivation_RHR  "This signal indicates the chime activation request for the right hand, rear audio speaker, or rear hardwired buzzer.";
CM_ SG_ 950 ChimeRepetitionRate_Front  "This signal indicates the repetition rate for the front audio speakers.";
CM_ SG_ 950 ChimeRepetitionRate_Rear  "This signal indicates the repetition rate for the rear audio speakers.";
CM_ SG_ 950 ChimeType_Front  "This signal indicates the Chime Type for the front audio speakers.";
CM_ SG_ 950 ChimeType_Rear  "This signal indicates the Chime Type for the rear audio speakers.";
CM_ SG_ 950 DisplayActivation  "This signal indicates the request to display the car graphics layout on the IPC/EVIC screen.";
CM_ SG_ 950 Graphic_CHF  "This signal indicates the flash rate of the arc displayed in the central hand, front position of the car graphics.";
CM_ SG_ 950 Graphic_CHR  "This signal indicates the flash rate of the arc displayed in the central hand, rear position of the car graphics.";
CM_ SG_ 950 Graphic_LHF  "This signal indicates the flash rate of the arc displayed in the left hand, front position of the car graphics.";
CM_ SG_ 950 Graphic_LHR  "This signal indicates the flash rate of the arc displayed in the left hand, rear position of the car graphics.";
CM_ SG_ 950 Graphic_RHF  "This signal indicates the flash rate of the arc displayed in the right hand, front position of the car graphics.";
CM_ SG_ 950 Graphic_RHR  "This signal indicates the flash rate of the arc displayed in the right hand, rear position of the car graphics.";
CM_ SG_ 775 RbssSysBlockIndSts  "RBSS system block indication status";
CM_ SG_ 775 RbssSysInterfIndSts  "RBSS system interference indication status";
CM_ SG_ 775 RbssSysSrvIndSts  "RBSS system indication status";
CM_ SG_ 775 RbssTmpUnavIndSts  "RBSS system temporarily unavailable indication status";
CM_ SG_ 948 SDW_ChimeActivation_LHF  "This signal indicates the chime activation request for the left hand, front audio speaker, or rear hardwired buzzer.";
CM_ SG_ 948 SDW_ChimeActivation_LHR  "This signal indicates the chime activation request for the left hand, rear audio speaker, or rear hardwired buzzer.";
CM_ SG_ 948 SDW_ChimeActivation_RHF  "This signal indicates the chime activation request for the right hand, front audio speaker, or rear hardwired buzzer.";
CM_ SG_ 948 SDW_ChimeActivation_RHR  "This signal indicates the chime activation request for the right hand, rear audio speaker, or rear hardwired buzzer.";
CM_ SG_ 948 SDW_ChimeRepetitionRate_Left  "This signal indicates the repetition rate for the left audio speakers.";
CM_ SG_ 948 SDW_ChimeRepetitionRate_Right  "This signal indicates the repetition rate for the right audio speakers.";
CM_ SG_ 948 SDW_ChimeType_Left  "This signal indicates the Chime Type for the left audio speakers.";
CM_ SG_ 948 SDW_ChimeType_Right  "This signal indicates the Chime Type for the right audio speakers.";
CM_ SG_ 948 SDW_DisplayActivation  "This signal indicates the request to display the car graphics layout on the IPC/EVIC screen.";
CM_ SG_ 948 SDW_Warning_Left_1  "This signal is used to turn lateral arc";
CM_ SG_ 948 SDW_Warning_Left_2  "This signal is used to turn lateral arc";
CM_ SG_ 948 SDW_Warning_Right_1  "This signal is used to turn lateral arc";
CM_ SG_ 948 SDW_Warning_Right_2  "This signal is used to turn lateral arc";
CM_ SG_ 1890 DaysToService  "Used to give information about the missing days for the next vehicle service.";
CM_ SG_ 1890 DistanceToService  "Used to give information about the missing distance for the next vehicle service.";
CM_ SG_ 2000 AMP_DSS_STATSts  "Driver Select Surround Status";
CM_ SG_ 2000 AMP_MUTEDSts  "Amplifer mute status unmuted = [0], muted = [1]";
CM_ SG_ 2000 AUDIOSts_AMP  "Used to give information about Telematic Module audio availability";
CM_ SG_ 2000 SURR_AVAILSts  "Surround sound available for selected cabin mode [1] = True";
CM_ SG_ 854 BonnetSts  "Used to indicate the status of the bonnet";
CM_ SG_ 854 BrakePedalSwitchNOSts  "It is the Brake Light Switch (Normally Open) position status, acquired by BCM and transmitted on CAN.";
CM_ SG_ 854 DriverDoorSts  "Used to indicate the status of driver door";
CM_ SG_ 854 FrontWiperMoveSts  "This signal indicates the position of the front wiper (contact cam open or close).";
CM_ SG_ 854 FuelLevel  "Used to give information about the percentage of the fuel level present in the tank.";
CM_ SG_ 854 FuelLevelFailSts  "Used to give information about the fail status of the FuelLevel signal.";
CM_ SG_ 854 LHRDoorSts  "Used to indicate the status of left rear door";
CM_ SG_ 854 LowFuelWarningSts  "Used to give information about the status of the low fuel warning.";
CM_ SG_ 854 ParkBrakeSts  "Status of Park Brake";
CM_ SG_ 854 PsngrDoorSts  "Used to indicate the status of passenger door";
CM_ SG_ 854 RainSensorFailSts  "This signal indicates a Rain sensor fail.";
CM_ SG_ 854 RHatchSts  "Used to indicate the status of the trunk liftgate";
CM_ SG_ 854 RHRDoorSts  "Used to indicate the status of right rear door";
CM_ SG_ 854 StopStartActivationSts  "It signals to IPC tha status (deactivated/activated) of StopStart functionality.";
CM_ SG_ 854 StopStartVisualizationCode  "Sent by BCM, it signals to IPC the visualization to be swown to the user";
CM_ SG_ 854 WarningKeyInSts  "This signal activates a buzzer when the driver door is open and the key is in the starting system.";
CM_ SG_ 1132 BatteryChargeSts  "Battery State of Charge (in %), as acquired from the battery sensor";
CM_ SG_ 1132 BatteryVoltageLevel  "This signal is used to indicate the voltage level of the battery";
CM_ SG_ 1132 CmdIgnSts  "Used to give information about the key selector position";
CM_ SG_ 1132 CurrentFailStsIBS  "It signals a possible fault of the battery sensor";
CM_ SG_ 1132 DriveStyleSts  "This signal gives indications about drive style status required.";
CM_ SG_ 1132 ExternalTemperatureC  "Used to indicate the external temperature value in °C";
CM_ SG_ 1132 ExternalTemperatureF  "Used to indicate the external temperature value in °F";
CM_ SG_ 1132 ExternalTemperatureFailSts  "Used to indicate if a Fail is present for the external temperature value";
CM_ SG_ 1132 InternalLightLevel  "Used to give information about the backlight dimming level selected.";
CM_ SG_ 1132 InternalLightSts  "Used to give information about backlight mode selected (Day or Night).";
CM_ SG_ 1132 RemStActvSts  "Ignition Run active for remote start";
CM_ SG_ 1128 ClusterLightSts  "Used to give information about the status of the cluster light sensor.";
CM_ SG_ 1128 SPM_Mode_Selection  "It indicates the Semiautomatic Parking Mode selected by the driver by IPC menu";
CM_ SG_ 988 AFSts  "This signal indicates the instantaneous Air Fuel relation";
CM_ SG_ 988 LatAcceleration_BSM  "This signal indicates the Lateral Acceleration Value";
CM_ SG_ 988 LatAccelerationFailSts_BSM  "This signal indicates the status of Lateral Acceleration Signal";
CM_ SG_ 988 LongAcceleration_BSM  "This signal indicates the Longitudinal Acceleration Value";
CM_ SG_ 988 LongAccelerationFailSts_BSM  "This signal indicates the status of Longitudinal acceleration signal";
CM_ SG_ 988 YawRate_BSM  "This signal indicates the Yaw Rate Value";
CM_ SG_ 988 YawRateFailSts_BSM  "This signal indicates the Status of Yaw Rate Signal";
CM_ SG_ 990 LHF_FastPulseCounter  "This signal is the left front wheel pulse counter.";
CM_ SG_ 990 LHF_FastPulseCounter_Overflow  "It checks the presence of overflow in LHF_FastPulseCounter value";
CM_ SG_ 990 LHF_WheelSensorFailSts  "This signal indicates the fail status of LHF sensor";
CM_ SG_ 990 LHR_FastPulseCounter  "This signal is the left rear wheel pulse counter.";
CM_ SG_ 990 LHR_FastPulseCounter_Overflow  "It checks the presence of overflow in LHR_FastPulseCounter value";
CM_ SG_ 990 LHR_WheelSensorFailSts  "This signal indicates the fail status of LHR sensor";
CM_ SG_ 990 RHF_FastPulseCounter  "This signal is the right front wheel pulse counter.";
CM_ SG_ 990 RHF_FastPulseCounter_Overflow  "It checks the presence of overflow in RHF_FastPulseCounter value";
CM_ SG_ 990 RHF_WheelSensorFailSts  "This signal indicates the fail status of RHF sensor";
CM_ SG_ 990 RHR_FastPulseCounter  "This signal is the right rear wheel pulse counter.";
CM_ SG_ 990 RHR_FastPulseCounter_Overflow  "It checks the presence of overflow in RHR_FastPulseCounter value";
CM_ SG_ 990 RHR_WheelSensorFailSts  "This signal indicates the fail status of RHR sensor";
CM_ SG_ 990 TravelDistance  "This signal indicates the travel distance value.";
CM_ SG_ 994 ACPressure  "It indicates air conditioning pressure read from the AC linear pressure sensor.";
CM_ SG_ 994 ACPressureFailSts  "This signal indicates if the ACpressure sensor is in fail.";
CM_ SG_ 994 AlternatorFail  "Indicates if the alternator is in fail condition";
CM_ SG_ 994 CompressorSts  "This signal gives information about the present status of A/C external request and actual A/C activation by ECM.";
CM_ SG_ 994 EngineSts  "It is the current engine status";
CM_ SG_ 994 EngineWaterTemp  "It is the engine water temperature, measured through the related sensor.";
CM_ SG_ 994 EngineWaterTempFailSts  "It is the Fail Status bit of EngineWaterTemp signal the signal is set to Fail Present when the engine temperature sensor is faulty.";
CM_ SG_ 994 ShiftModeSts  "This signal indicates the gear selector modality selected by driver (Manual or Automatic).";
CM_ SG_ 994 VehicleSpeedVSOSig  "It is the average vehicle speed calculated.";
CM_ SG_ 994 VehicleSpeedVSOSig_UB  "It indicates if the signal VehicleSpeedVSOSig has been updated";
CM_ SG_ 994 VehicleSpeedVSOSigFailSts  "It is the average vehicle speed fail status.";
CM_ SG_ 994 VehicleSpeedVSOSigFailSts_UB  "It indicates if the signal VehicleSpeedVSOSigFailSts has been updated";
CM_ SG_ 996 DPFSts  "It is required only on diesel systems equipped with Diesel Particulate Filter. It is used to signalize that the current operating conditions (engine load, DPF pressure and temperature) do not allow performing the DPF regeneration strategy (signa(...)";
CM_ SG_ 996 FuelConsumption_GAG  "It represents instantaneous consumption information sent on network";
CM_ SG_ 996 GearShiftIndication  "It gives indication of gear shifting";
CM_ SG_ 996 OilLifeSts  "This information is related to engine oil life algorithm, currently used on Diesel engines equipped with DPF.";
CM_ SG_ 996 ReverseGearSts  "It gives information of reverse gear status.";
CM_ SG_ 998 EngineSpeed  "Used to indicate the engine speed";
CM_ SG_ 998 EngineSpeedFailSts  "Used to indicate if a Fail is present for the engine speed";
CM_ SG_ 1984 InflationState_LHF_Tyre  "It signal indicated the state for the pressure of the wheel identified";
CM_ SG_ 1984 InflationState_LHR_Tyre  "It signal indicated the state for the pressure of the wheel identified";
CM_ SG_ 1984 InflationState_RHF_Tyre  "It signal indicated the state for the pressure of the wheel identified";
CM_ SG_ 1984 InflationState_RHR_Tyre  "It signal indicated the state for the pressure of the wheel identified";
CM_ SG_ 1984 TyrePressureSystemFailSts  "It indicates that the TPM System is in Fault or not";
CM_ SG_ 1130 A2D_DRV_TEMP_DR_POS  "Transmit raw A/D driver temp door position to ECM, the information is used to make OBD model more robust";
CM_ SG_ 1130 A2D_FT_HVAC_BLOWER_VOLTAGE  "Transmit raw A/D blower voltage to ECM, the information is used to make OBD model more robust";
CM_ SG_ 1130 AcOutputCurrentSts  "It is the ECVD electrovalve current";
CM_ SG_ 1130 CompressorACReqSts  "Used to indicate the user request of compressor activation";
CM_ SG_ 1130 FHeatedWindowCmd  "Used to require the Front heated window activation/deactivation";
CM_ SG_ 1130 HVAC_Blower_Speed  "The signal indicates the PWM command for Blower and blower status";
CM_ SG_ 1130 HVAC_SAM_enable  "Disable the SAM if high blower speed is required";
CM_ SG_ 1130 MaxDefrostSts  "Used to indicate the user request status of Max Defrost";
CM_ SG_ 1130 PTCFailSts  "Used to indicate if a Fail is present for the PTC activation status";
CM_ SG_ 1130 PTCSts  "Used to indicate the PTC activation status";
CM_ SG_ 1130 RHeatedWindowCmd  "Used to require the Rear heated window activation/deactivation.";
CM_ SG_ 1130 StopStartEnable  "Sent by ECC (if present) it signals the consent by climate control to the Stop&Start function";
CM_ SG_ 1098 BSS_LF_Chime_RQSts  "BSM left front chime on request";
CM_ SG_ 1098 BSS_LR_Chime_RQSts  "BSM Left rear chime on request";
CM_ SG_ 1098 BSS_LT_Blind_RQSts  "Sensor blinded request from BSS Left";
CM_ SG_ 1098 BSS_LT_CFG_STATSts  "Blind Spot left Side configuration status";
CM_ SG_ 1098 BSS_LT_Chime_TypeSts  "BSS left side chime type";
CM_ SG_ 1098 BSS_LT_OPR_StatSts  "BSS Left Side operation status";
CM_ SG_ 1098 BSS_LT_SRV_RQSts  "BSS Left Side service warning request";
CM_ SG_ 1098 BssLtLedFaultSts  "Left Sensor Led fault Status";
CM_ SG_ 1098 BssLtWrnSts  "Left Sensor LED Warning Status";
CM_ SG_ 1462 DynamicGridFailSts  "Rear View Camera Dynamic Gridlines fail condition";
CM_ SG_ 1462 DynamicGridSts  "Rear View Camera Dynamic Gridlines request";
CM_ SG_ 1268 FrontSensorSts  "This signal indicates the activation state of the front sensors.";
CM_ SG_ 1268 HMICode  "This signal indicates the request to display HMI content on the screen";
CM_ SG_ 1268 LateralSensorSts  "This signal indicates the activation state of the lateral sensors";
CM_ SG_ 1268 PAMAboveSpeed  "This signal is used to manage a indication, related to the deactivation of PAM system, when the vehicle speed is too high.";
CM_ SG_ 1268 PAMSystemFault  "This signal indicates if the PAM is in a faulted condition";
CM_ SG_ 1268 PAMSystemSts  "This signal indicates the activation state of the PAM";
CM_ SG_ 1268 RearSensorSts  "This signal indicates the activation state of the rear sensors";
CM_ SG_ 1268 SDWFailSts  "The signal is used to indicate a failure in the function";
CM_ SG_ 1268 SPMControlSts  "This signal indicates the activation state of the SPM module.";
CM_ SG_ 1268 SPMFailSts  "This signal indicates if the SPM is in a faulted condition.";
CM_ SG_ 1100 BSS_RF_Chime_RQSts  "BSM right front chime on request";
CM_ SG_ 1100 BSS_RR_Chime_RQSts  "BSM right rear chime on request";
CM_ SG_ 1100 BSS_RT_Blind_RQSts  "Sensor blinded request from BSS Right";
CM_ SG_ 1100 BSS_RT_CFG_STATSts  "Blind Spot Right Side configuration status";
CM_ SG_ 1100 BSS_RT_Chime_TypeSts  "BSS right side chime type";
CM_ SG_ 1100 BSS_RT_OPR_StatSts  "BSS Right Side operation status";
CM_ SG_ 1100 BSS_RT_SRV_RQSts  "BSS Right Side service warning request";
CM_ SG_ 1100 BssRtLedFaultSts  "Right Sensor Led fault Status";
CM_ SG_ 1100 BssRtWrnSts  "Right Sensor LED Warning Status";
CM_ SG_ 1470 AntitheftSts  "ETM Antitheft logic status";
CM_ SG_ 1470 AUDIOSts_Telematic  "Used to give information about Telematic Module audio availability";
CM_ SG_ 1470 CurrentSource  "ETM current active source";
CM_ SG_ 1470 HFPSts  "ETM hands free phone status";
CM_ SG_ 1470 MuteSts  "ETM Entertainment source Mute status";
CM_ SG_ 1470 PowerSts_Telematic  "ETM power status";
CM_ SG_ 1470 VRSts  "ETM Voice Recognition Status";
CM_ SG_ 1464 TrailerConnectionSts  "Connection status of TTM";
CM_ SG_ 1464 TrailerGenericFailSts  "Status of Fail of TTM";
CM_ SG_ 1464 TrailerLHParkingLightFailSts  "Status of Fail of Trailer Left Parking Light";
CM_ SG_ 1464 TrailerLHParkingLightSts  "Status of Trailer Left Parking Light Output";
CM_ SG_ 1464 TrailerLHTurnSignalFailSts  "Status of Fail of Trailer Left Turn Light";
CM_ SG_ 1464 TrailerLHTurnSignalSts  "Status of Trailer Left Turn Light Output";
CM_ SG_ 1464 TrailerRearFogLightFailSts  "Status of Fail of Trailer Rear Fog Light";
CM_ SG_ 1464 TrailerRearFogLightSts  "Status of Trailer Rear Fog Light Output";
CM_ SG_ 1464 TrailerReverseGearFailSts  "Status of Fail of Trailer Reverse Gear Light";
CM_ SG_ 1464 TrailerReverseGearSts  "Status of Trailer Reverse Gear Light Output";
CM_ SG_ 1464 TrailerRHParkingLightFailSts  "Status of Fail of Trailer Right Parking Light";
CM_ SG_ 1464 TrailerRHParkingLightSts  "Status of Trailer Right Parking Light Output";
CM_ SG_ 1464 TrailerRHTurnSignalFailSts  "Status of Fail of Trailer Right Turn Light";
CM_ SG_ 1464 TrailerRHTurnSignalSts  "Status of Trailer Right Turn Light Output";
CM_ SG_ 1464 TrailerStopLightFailSts  "Status of Fail of Trailer Stop Lights";
CM_ SG_ 1464 TrailerStopLightSts  "Status of Trailer Stop Light Outputs";
CM_ SG_ 750 Command_01Sts  "Infotainment Switch 1";
CM_ SG_ 750 Command_02Sts  "Infotainment Switch 2";
CM_ SG_ 750 Command_03Sts  "Infotainment Switch 3";
CM_ SG_ 750 Command_04Sts  "Infotainment Switch 4";
CM_ SG_ 750 Command_05Sts  "Infotainment Switch 5";
CM_ SG_ 750 Command_06Sts  "Infotainment Switch 6";
CM_ SG_ 750 Command_07Sts  "Infotainment Switch 7";
CM_ SG_ 750 Command_08Sts  "Infotainment Switch 8";
CM_ SG_ 750 Command_09Sts  "Infotainment Switch 9";
CM_ SG_ 750 Command_10Sts  "Infotainment Switch 10";
CM_ SG_ 750 Command_11Sts  "Infotainment Switch 11";
CM_ SG_ 750 Command_12Sts  "Infotainment Switch 12";
CM_ SG_ 750 Command_13Sts  "Infotainment Switch 13";
CM_ SG_ 750 Command_14Sts  "Infotainment Switch 14";
CM_ SG_ 750 Command_15Sts  "Infotainment Switch 15";
CM_ SG_ 158 AmbientLightingLevel_Req  "This signal is managed when the driver request a setting of the Ambient Light Level";
CM_ SG_ 158 AutoHighBeamEnable_Req  "This signal is managed when the driver requests a setting of the Auto High Beam feature";
CM_ SG_ 158 AutoParkBrake_Req  "This signal is managed when the driver requests a setting of the Auto Park Brake";
CM_ SG_ 158 BSDEnable_Req  "This signal is managed when the driver requests a setting of Blind Spot Alert";
CM_ SG_ 158 ConsumptionUnit_Req  "This signal is managed when the driver requests a setting of Consumption Unit";
CM_ SG_ 158 CorneringEnable_Req  "This signal is managed when the driver requests a setting of Cornering Lights";
CM_ SG_ 158 DistanceUnit_Req  "This signal is managed when the driver requests a setting of Distance Unit";
CM_ SG_ 158 DRLEnable_Req  "This signal is managed when the driver requests a setting of the DRL feature";
CM_ SG_ 158 DynamicGrid_Req  "Rear View Camera Dynamic Gridlines request";
CM_ SG_ 158 ExternalLightSensorLevel_Req  "This signal is managed when the driver requests a setting of External Light Sensor Level";
CM_ SG_ 158 GreetingLightsEnable_Req  "This signal is managed when the button of block or unblocking of the door is pressed.";
CM_ SG_ 158 HourMode_Req  "This signal is managed when the driver requests a setting of Hour Mode";
CM_ SG_ 158 LanguageSelection_Req  "This signal is managed when the driver requests a setting of Language";
CM_ SG_ 158 PamAlertMode_Req  "This signal is managed when the driver requests a setting of the PAM Alert Mode";
CM_ SG_ 158 PamChimeVolumeFront_Req  "This signal is managed when the driver request a setting of the of Chime Volume of the PAM";
CM_ SG_ 158 PamChimeVolumeRear_Req  "This signal is managed when the driver request a setting of the of Chime Volume of the PAM 8 Channels";
CM_ SG_ 158 PassiveEntry_Req  "This signal is managed when the driver requests a setting of the Passive Entry";
CM_ SG_ 158 RainSensorLevel_Req  "This signal is managed when the driver requests a setting of Rain Sensor Level";
CM_ SG_ 158 RemoteDoorUnlock_Req  "This signal is managed when the driver requests a setting of the Remote Door Unlock";
CM_ SG_ 158 ResetTripA_Req  "This signal is managed when the driver requests a setting of the Reset of Trip A";
CM_ SG_ 158 ResetTripB_Req  "This signal is managed when the driver requests a setting of the Reset of Trip B";
CM_ SG_ 158 Sdw_Req  "This signal is managed when the driver request a setting of the Sdw";
CM_ SG_ 158 SdwChimeVolume_Req  "This signal is managed when the driver request a setting of the of Chime Volume of the Sdw";
CM_ SG_ 158 SoundHornLock_Req  "This signal is managed when the driver requests a setting of the Sound Horn with Unlock";
CM_ SG_ 158 SoundHornRemoteStart_Req  "This signal is managed when the driver requests a setting of the Sound Horn with Remote Start";
CM_ SG_ 158 SpeedLockDoorEnable_Req  "This signal is managed when the driver requests a setting of Auto Door Locks";
CM_ SG_ 158 TemperatureUnit_Req  "This signal is managed when the driver requests a setting of Temperature Unit";
CM_ SG_ 162 AutoUnlockDoorExit_Req  "This signal is managed when the driver request a setting of Auto Unlock Door On Exit";
CM_ SG_ 162 EPB_MaintenanceMode_Req  "This signal is managed when the driver request a setting of Maintenance Mode";
CM_ SG_ 162 FlashLightWLock_Req  "This signal is managed when the driver request a setting of Flash Light With Lock";
CM_ SG_ 162 FSFCWPlusActivationMode_Req  "This signal is managed when the driver request a setting of FSFCW";
CM_ SG_ 162 FSFCWPlusSetting_Req  "This signal is managed when the driver request a setting of FSFCW";
CM_ SG_ 162 HeadlightsOffDelay_Req  "This signal is managed when the driver requests a setting of the Headligts Off Delay";
CM_ SG_ 162 LDW_Intensity_Req  "This signal is managed when the driver requests a setting of the LDW Intensity";
CM_ SG_ 162 LDW_Sensibility_Req  "This signal is managed when the driver requests a setting of the LDW Sensibility";
CM_ SG_ 162 TyrePressureUnit_Req  "This signal is managed when the driver requests a setting of the Tyre Pressure Unit";
CM_ SG_ 1892 Day1  "It is the first digit of the day for the date visualization";
CM_ SG_ 1892 Day2  "It is the second digit of the day for the date visualization";
CM_ SG_ 1892 Hour1  "It is the first digit of the hours for the clock visualization";
CM_ SG_ 1892 Hour2  "It is the second digit of the hours for the clock visualization";
CM_ SG_ 1892 Minute1  "It is the first digit of the minutes for the clock visualization";
CM_ SG_ 1892 Minute2  "It is the second digit of the minutes for the clock visualization";
CM_ SG_ 1892 Month1  "It is the first digit of the month for the date visualization";
CM_ SG_ 1892 Month2  "It is the second digit of the month for the date visualization";
CM_ SG_ 1892 Year1  "It is the first digit of the year for the date visualization";
CM_ SG_ 1892 Year2  "It is the second digit of the year for the date visualization";
CM_ SG_ 1892 Year3  "It is the third digit of the year for the date visualization";
CM_ SG_ 1892 Year4  "It is the fourth digit of the year for the date visualization";
CM_ SG_ 1472 AverageFuelConsumptionAPlus  "Used to give information about the average fuel consumption for Trip A.";
CM_ SG_ 1472 AverageSpeedAPlus  "Used to give information about the average speed for Trip A.";
CM_ SG_ 1472 PartialOdometerAPlus  "Used to give information about the partial odometer for Trip A";
CM_ SG_ 1472 ResetTripAPlusACK  "Used to give information about the acknowledge of the reset for Trip A.";
CM_ SG_ 1472 TravelingTimeAPlus_Hour  "Used to give information about hours of travel time for Trip A.";
CM_ SG_ 1472 TravelingTimeAPlus_Minute  "Used to give information about minutes of travel time for Trip A.";
CM_ SG_ 1472 TravelingTimeAPlus_Second  "Used to give information about seconds of travel time for Trip A";
CM_ SG_ 1888 AutonomyDistance  "Used to give information about the distance to empty.";
CM_ SG_ 1888 InstantaneousFuelConsumption1  "Used to give information about the tens of the instantaneous fuel consumption value.";
CM_ SG_ 1888 InstantaneousFuelConsumption2  "Used to give information about the units of the instantaneous fuel consumption value.";
CM_ SG_ 1888 InstantaneousFuelConsumption3  "Used to give information about the tenths of the instantaneous fuel consumption value.";
CM_ SG_ 1888 TotalOdometer  "Used to give information about the total odometer value in km.";
CM_ SG_ 1476 AverageFuelConsumptionBPlus  "Used to give information about the average fuel consumption for Trip B.";
CM_ SG_ 1476 AverageSpeedBPlus  "Used to give information about the average speed for Trip B.";
CM_ SG_ 1476 PartialOdometerBPlus  "Used to give information about the partial odometer for Trip B.";
CM_ SG_ 1476 ResetTripBPlusACK  "Used to give information about the acknowledge of the reset for Trip B.";
CM_ SG_ 1476 TravelingTimeBPlus_Hour  "Used to give information about hours of travel time for Trip B.";
CM_ SG_ 1476 TravelingTimeBPlus_Minute  "Used to give information about minutes of travel time for Trip B.";
CM_ SG_ 1476 TravelingTimeBPlus_Second  "Used to give information about seconds of travel time for Trip B";
CM_ SG_ 748 UConnReq  "Requests specific vehicle function";
CM_ SG_ 748 UConnReqAuthCode  "Authenticates function requests";
CM_ SG_ 748 UConnReqFOBNum  "Indicates Corresponding FOB number 1-8";
CM_ SG_ 1976 UConnSeed1  "random # for security, Character 1";
CM_ SG_ 1976 UConnSeed2  "random # for security, Character 2";
CM_ SG_ 1976 UConnSeed3  "random # for security, Character 3";
CM_ SG_ 1976 UConnSeed4  "random # for security, Character 4";
CM_ SG_ 992 VIN_DATA  "VIN Digits (8 bit ascii encoded)";
CM_ SG_ 992 VIN_MSG  "VIN Message Information";
CM_ SG_ 152 ControlEncoding  "Coding according to Spec. See Spec.";
CM_ SG_ 152 F11  "Coding according to Spec. See Spec.";
CM_ SG_ 152 F12  "Coding according to Spec. See Spec.";
CM_ SG_ 152 Rnd1  "Coding according to Spec. See Spec.";
CM_ SG_ 152 Rnd2  "Coding according to Spec. See Spec.";
CM_ SG_ 152 Rnd3  "Coding according to Spec. See Spec.";
CM_ SG_ 152 Rnd4  "Coding according to Spec. See Spec.";
CM_ SG_ 154 ControlEncoding  "Coding according to Spec. See Spec.";
CM_ SG_ 154 G21  "Coding according to Spec. See Spec.";
CM_ SG_ 154 G22  "Coding according to Spec. See Spec.";
BA_DEF_ SG_ "Accuracy" STRING ;
BA_DEF_ SG_ "Event trans." ENUM "Yes","No";
BA_DEF_ SG_ "GenSigStartValue" INT 0 2147483647;
BA_DEF_ SG_ "GenSigInactiveValue" INT 0 2147483647;
BA_DEF_ SG_ "GenSigSendType" ENUM "NotUsed","OnWrite","OnWriteWithRepetition","OnChange","OnChangeWithRepetition","IfActive","IfActiveWithRepetition","NoSigSendType";
BA_DEF_ BO_ "DiagRequest" ENUM "No","Yes";
BA_DEF_ BO_ "Period [ms]" INT 0 65535;
BA_DEF_ BO_ "Type" ENUM "P","C","PE","COC","PE_Cntrl","E","E_Cntrl","OC","S","BAF","DC","EM","MM","-";
BA_DEF_ BO_ "DiagResponse" ENUM "No","Yes";
BA_DEF_ BO_ "NmMessage" ENUM "No","Yes";
BA_DEF_ BO_ "GenMsgSendType" ENUM "Cyclic","NotUsed","NotUsed","NotUsed","NotUsed","NotUsed","NotUsed","NotUsed","NoMsgSendType";
BA_DEF_ BO_ "GenMsgTimeoutTime" INT 0 10000;
BA_DEF_ BO_ "GenMsgNrOfRepetition" INT 0 255;
BA_DEF_ BO_ "GenMsgILSupport" ENUM "No","Yes";
BA_DEF_ BO_ "GenMsgStartDelayTime" INT 0 65535;
BA_DEF_ BO_ "GenMsgCycleTimeFast" INT 0 65535;
BA_DEF_ BO_ "GenMsgCycleTime" INT 0 65535;
BA_DEF_ BO_ "GenMsgDelayTime" INT 0 65535;
BA_DEF_ BO_ "DiagState" ENUM "No","Yes";
BA_DEF_ BU_ "NodeLayerModules" STRING ;
BA_DEF_ BU_ "Description" STRING ;
BA_DEF_ BU_ "NmStationAddress" HEX 0 255;
BA_DEF_ BU_ "NmNode" ENUM "No","Yes";
BA_DEF_ BU_ "ILUsed" ENUM "No","Yes";
BA_DEF_ BU_ "NmNodeType" ENUM "kMaster","kSlave15","kSlave30","none";
BA_DEF_ BU_ "NwmNodeType" ENUM "kMaster","kSlave15","kSlave30","none";
BA_DEF_ BU_ "TpOwnSystemEcuNumber" HEX 0 255;
BA_DEF_ "Manufacturer" STRING ;
BA_DEF_ "NmType" STRING ;
BA_DEF_ "BusType" STRING ;
BA_DEF_ "Baudrate" INT 0 1000000;
BA_DEF_ "DBName" STRING ;
BA_DEF_ "Version" HEX 0 255;
BA_DEF_ "VersionWeek" INT 0 53;
BA_DEF_ "VersionYear" INT 0 99;
BA_DEF_DEF_ "Accuracy" "";
BA_DEF_DEF_ "Event trans." "No";
BA_DEF_DEF_ "GenSigStartValue" 0;
BA_DEF_DEF_ "GenSigInactiveValue" 0;
BA_DEF_DEF_ "GenSigSendType" "NoSigSendType";
BA_DEF_DEF_ "DiagRequest" "No";
BA_DEF_DEF_ "Period [ms]" 0;
BA_DEF_DEF_ "Type" "-";
BA_DEF_DEF_ "DiagResponse" "No";
BA_DEF_DEF_ "NmMessage" "No";
BA_DEF_DEF_ "GenMsgSendType" "NoMsgSendType";
BA_DEF_DEF_ "GenMsgTimeoutTime" 0;
BA_DEF_DEF_ "GenMsgNrOfRepetition" 0;
BA_DEF_DEF_ "GenMsgILSupport" "No";
BA_DEF_DEF_ "GenMsgStartDelayTime" 0;
BA_DEF_DEF_ "GenMsgCycleTimeFast" 0;
BA_DEF_DEF_ "GenMsgCycleTime" 0;
BA_DEF_DEF_ "GenMsgDelayTime" 0;
BA_DEF_DEF_ "DiagState" "No";
BA_DEF_DEF_ "NodeLayerModules" "Osek_TP.dll";
BA_DEF_DEF_ "Description" "";
BA_DEF_DEF_ "NmStationAddress" 0;
BA_DEF_DEF_ "NmNode" "Yes";
BA_DEF_DEF_ "ILUsed" "Yes";
BA_DEF_DEF_ "NmNodeType" "none";
BA_DEF_DEF_ "NwmNodeType" "none";
BA_DEF_DEF_ "TpOwnSystemEcuNumber" 0;
BA_DEF_DEF_ "Manufacturer" "Fiat";
BA_DEF_DEF_ "BusType" "CAN";
BA_DEF_DEF_ "Baudrate" 500000;
BA_DEF_DEF_ "DBName" "CAN";
BA_DEF_DEF_ "Version" 160;
BA_DEF_DEF_ "VersionWeek" 19;
BA_DEF_DEF_ "VersionYear" 15;
BA_ "Baudrate" 125000;
BA_ "NmType" "FIAT";
BA_ "DBName" "BHCAN1";
BA_ "TpOwnSystemEcuNumber" BU_ ACM 152;
BA_ "NwmNodeType" BU_ ACM 1;
BA_ "NmNodeType" BU_ ACM 1;
BA_ "NmStationAddress" BU_ ACM 10;
BA_ "Description" BU_ ACM "Automatic Control Module";
BA_ "TpOwnSystemEcuNumber" BU_ AMP 131;
BA_ "NwmNodeType" BU_ AMP 2;
BA_ "NmNodeType" BU_ AMP 2;
BA_ "NmStationAddress" BU_ AMP 46;
BA_ "Description" BU_ AMP "Amplifier";
BA_ "TpOwnSystemEcuNumber" BU_ BCM 64;
BA_ "NwmNodeType" BU_ BCM 0;
BA_ "NmNodeType" BU_ BCM 0;
BA_ "Description" BU_ BCM "Body Control Module";
BA_ "NmNode" BU_ DIAG_TEST 0;
BA_ "Description" BU_ DIAG_TEST "Diagnostic Tester";
BA_ "TpOwnSystemEcuNumber" BU_ IPC 96;
BA_ "NwmNodeType" BU_ IPC 2;
BA_ "NmNodeType" BU_ IPC 2;
BA_ "NmStationAddress" BU_ IPC 3;
BA_ "Description" BU_ IPC "Instrument Panel Cluster";
BA_ "TpOwnSystemEcuNumber" BU_ LBSS 98;
BA_ "NwmNodeType" BU_ LBSS 1;
BA_ "NmNodeType" BU_ LBSS 1;
BA_ "NmStationAddress" BU_ LBSS 51;
BA_ "Description" BU_ LBSS "Left ma Spot Sensor";
BA_ "TpOwnSystemEcuNumber" BU_ SGW 203;
BA_ "NwmNodeType" BU_ SGW 2;
BA_ "NmNodeType" BU_ SGW 2;
BA_ "NmStationAddress" BU_ SGW 203.0;
BA_ "Description" BU_ SGW "Secure GateWay module";
BA_ "TpOwnSystemEcuNumber" BU_ MCM 152;
BA_ "NwmNodeType" BU_ MCM 1;
BA_ "NmNodeType" BU_ MCM 1;
BA_ "NmStationAddress" BU_ MCM 10;
BA_ "Description" BU_ MCM "Manual Climate Module";
BA_ "TpOwnSystemEcuNumber" BU_ MHM 152;
BA_ "NmStationAddress" BU_ MHM 10;
BA_ "Description" BU_ MHM "Manual Heater Module";
BA_ "TpOwnSystemEcuNumber" BU_ RBSS 101;
BA_ "NwmNodeType" BU_ RBSS 1;
BA_ "NmNodeType" BU_ RBSS 1;
BA_ "NmStationAddress" BU_ RBSS 52;
BA_ "Description" BU_ RBSS "Right Blind Spot Sensor";
BA_ "TpOwnSystemEcuNumber" BU_ TTM 74;
BA_ "NwmNodeType" BU_ TTM 2;
BA_ "NmNodeType" BU_ TTM 2;
BA_ "NmStationAddress" BU_ TTM 63;
BA_ "Description" BU_ TTM "Trailer Tow Module";
BA_ "TpOwnSystemEcuNumber" BU_ VTM 193;
BA_ "NmStationAddress" BU_ VTM 49;
BA_ "Description" BU_ VTM "Vehicle Tracking Module";
BA_ "Period [ms]" BO_ 1884 1000;
BA_ "Type" BO_ 1884 1;
BA_ "GenMsgSendType" BO_ 1884 0;
BA_ "GenMsgTimeoutTime" BO_ 1884 2500;
BA_ "GenMsgILSupport" BO_ 1884 1;
BA_ "GenMsgCycleTime" BO_ 1884 1000;
BA_ "Period [ms]" BO_ 1474 1000;
BA_ "Type" BO_ 1474 3;
BA_ "GenMsgSendType" BO_ 1474 0;
BA_ "GenMsgILSupport" BO_ 1474 1;
BA_ "GenMsgStartDelayTime" BO_ 1474 750;
BA_ "GenMsgCycleTime" BO_ 1474 1000;
BA_ "GenMsgDelayTime" BO_ 1474 20;
BA_ "Type" BO_ 160 8;
BA_ "GenMsgTimeoutTime" BO_ 160 2500;
BA_ "GenMsgNrOfRepetition" BO_ 160 3;
BA_ "GenMsgILSupport" BO_ 160 1;
BA_ "GenMsgCycleTimeFast" BO_ 160 250;
BA_ "GenMsgDelayTime" BO_ 160 20;
BA_ "Type" BO_ 2651930624 8;
BA_ "GenMsgTimeoutTime" BO_ 2651930624 2500;
BA_ "GenMsgILSupport" BO_ 2651930624 1;
BA_ "Type" BO_ 2651930670 11;
BA_ "GenMsgTimeoutTime" BO_ 2651930670 2500;
BA_ "GenMsgILSupport" BO_ 2651930670 1;
BA_ "Type" BO_ 2651930634 11;
BA_ "GenMsgTimeoutTime" BO_ 2651930634 2500;
BA_ "GenMsgILSupport" BO_ 2651930634 1;
BA_ "Type" BO_ 2651930675 11;
BA_ "GenMsgTimeoutTime" BO_ 2651930675 2500;
BA_ "GenMsgILSupport" BO_ 2651930675 1;
BA_ "Type" BO_ 2651930676 11;
BA_ "GenMsgTimeoutTime" BO_ 2651930676 2500;
BA_ "GenMsgILSupport" BO_ 2651930676 1;
BA_ "Type" BO_ 2651930660 11;
BA_ "GenMsgTimeoutTime" BO_ 2651930660 2500;
BA_ "GenMsgILSupport" BO_ 2651930660 1;
BA_ "Type" BO_ 2651930687 11;
BA_ "GenMsgTimeoutTime" BO_ 2651930687 2500;
BA_ "GenMsgILSupport" BO_ 2651930687 1;
BA_ "Type" BO_ 134 8;
BA_ "GenMsgTimeoutTime" BO_ 134 2500;
BA_ "GenMsgNrOfRepetition" BO_ 134 3;
BA_ "GenMsgILSupport" BO_ 134 1;
BA_ "GenMsgCycleTimeFast" BO_ 134 250;
BA_ "GenMsgDelayTime" BO_ 134 20;
BA_ "Period [ms]" BO_ 1478 1000;
BA_ "Type" BO_ 1478 3;
BA_ "GenMsgSendType" BO_ 1478 0;
BA_ "GenMsgTimeoutTime" BO_ 1478 2500;
BA_ "GenMsgILSupport" BO_ 1478 1;
BA_ "GenMsgStartDelayTime" BO_ 1478 500;
BA_ "GenMsgCycleTime" BO_ 1478 1000;
BA_ "GenMsgDelayTime" BO_ 1478 20;
BA_ "Type" BO_ 2564554481 8;
BA_ "GenMsgTimeoutTime" BO_ 2564554481 2500;
BA_ "DiagState" BO_ 2564554481 1;
BA_ "DiagRequest" BO_ 2564457457 1;
BA_ "Type" BO_ 2564457457 8;
BA_ "DiagRequest" BO_ 2564462833 1;
BA_ "Type" BO_ 2564462833 8;
BA_ "DiagRequest" BO_ 2564449009 1;
BA_ "Type" BO_ 2564449009 8;
BA_ "DiagRequest" BO_ 2564449777 1;
BA_ "Type" BO_ 2564449777 8;
BA_ "DiagRequest" BO_ 2564442865 1;
BA_ "Type" BO_ 2564442865 8;
BA_ "DiagRequest" BO_ 2564473329 1;
BA_ "Type" BO_ 2564473329 8;
BA_ "Type" BO_ 2564485507 8;
BA_ "DiagResponse" BO_ 2564485507 1;
BA_ "Type" BO_ 2564485528 8;
BA_ "DiagResponse" BO_ 2564485528 1;
BA_ "Type" BO_ 2564485474 8;
BA_ "DiagResponse" BO_ 2564485474 1;
BA_ "Type" BO_ 2564485477 8;
BA_ "DiagResponse" BO_ 2564485477 1;
BA_ "Type" BO_ 2564485450 8;
BA_ "DiagResponse" BO_ 2564485450 1;
BA_ "Type" BO_ 2564485569 8;
BA_ "DiagResponse" BO_ 2564485569 1;
BA_ "Period [ms]" BO_ 852 250;
BA_ "Type" BO_ 852 3;
BA_ "GenMsgSendType" BO_ 852 0;
BA_ "GenMsgILSupport" BO_ 852 1;
BA_ "GenMsgStartDelayTime" BO_ 852 60;
BA_ "GenMsgCycleTime" BO_ 852 250;
BA_ "GenMsgDelayTime" BO_ 852 20;
BA_ "Type" BO_ 1270 11;
BA_ "GenMsgILSupport" BO_ 1270 1;
BA_ "Type" BO_ 986 11;
BA_ "GenMsgILSupport" BO_ 986 1;
BA_ "GenMsgDelayTime" BO_ 986 20;
BA_ "Type" BO_ 146 7;
BA_ "GenMsgILSupport" BO_ 146 1;
BA_ "GenMsgDelayTime" BO_ 146 20;
BA_ "Period [ms]" BO_ 1468 1000;
BA_ "Type" BO_ 1468 3;
BA_ "GenMsgSendType" BO_ 1468 0;
BA_ "GenMsgILSupport" BO_ 1468 1;
BA_ "GenMsgStartDelayTime" BO_ 1468 70;
BA_ "GenMsgCycleTime" BO_ 1468 1000;
BA_ "GenMsgDelayTime" BO_ 1468 50;
BA_ "Period [ms]" BO_ 1486 1000;
BA_ "Type" BO_ 1486 3;
BA_ "GenMsgSendType" BO_ 1486 0;
BA_ "GenMsgILSupport" BO_ 1486 1;
BA_ "GenMsgStartDelayTime" BO_ 1486 450;
BA_ "GenMsgCycleTime" BO_ 1486 1000;
BA_ "GenMsgDelayTime" BO_ 1486 50;
BA_ "Period [ms]" BO_ 773 200;
BA_ "Type" BO_ 773 3;
BA_ "GenMsgSendType" BO_ 773 0;
BA_ "GenMsgTimeoutTime" BO_ 773 2500;
BA_ "GenMsgILSupport" BO_ 773 1;
BA_ "GenMsgStartDelayTime" BO_ 773 100;
BA_ "GenMsgCycleTime" BO_ 773 200;
BA_ "GenMsgDelayTime" BO_ 773 20;
BA_ "Type" BO_ 2654208046 11;
BA_ "NmMessage" BO_ 2654208046 1;
BA_ "GenMsgTimeoutTime" BO_ 2654208046 2500;
BA_ "GenMsgDelayTime" BO_ 2654208046 500;
BA_ "Period [ms]" BO_ 2654208000 1000;
BA_ "Type" BO_ 2654208000 3;
BA_ "NmMessage" BO_ 2654208000 1;
BA_ "GenMsgSendType" BO_ 2654208000 0;
BA_ "GenMsgTimeoutTime" BO_ 2654208000 2500;
BA_ "GenMsgCycleTime" BO_ 2654208000 1000;
BA_ "Type" BO_ 2654208010 11;
BA_ "NmMessage" BO_ 2654208010 1;
BA_ "GenMsgTimeoutTime" BO_ 2654208010 2500;
BA_ "GenMsgDelayTime" BO_ 2654208010 500;
BA_ "Type" BO_ 2654208003 11;
BA_ "NmMessage" BO_ 2654208003 1;
BA_ "GenMsgTimeoutTime" BO_ 2654208003 2500;
BA_ "GenMsgDelayTime" BO_ 2654208003 500;
BA_ "Type" BO_ 2654208051 11;
BA_ "NmMessage" BO_ 2654208051 1;
BA_ "GenMsgTimeoutTime" BO_ 2654208051 2500;
BA_ "GenMsgDelayTime" BO_ 2654208051 500;
BA_ "Type" BO_ 2654208052 11;
BA_ "NmMessage" BO_ 2654208052 1;
BA_ "GenMsgTimeoutTime" BO_ 2654208052 2500;
BA_ "GenMsgDelayTime" BO_ 2654208052 500;
BA_ "Type" BO_ 2654208036 11;
BA_ "NmMessage" BO_ 2654208036 1;
BA_ "GenMsgTimeoutTime" BO_ 2654208036 2500;
BA_ "GenMsgDelayTime" BO_ 2654208036 500;
BA_ "Type" BO_ 2654208063 11;
BA_ "NmMessage" BO_ 2654208063 1;
BA_ "GenMsgTimeoutTime" BO_ 2654208063 2500;
BA_ "GenMsgDelayTime" BO_ 2654208063 500;
BA_ "Type" BO_ 2654208049 11;
BA_ "NmMessage" BO_ 2654208049 1;
BA_ "GenMsgTimeoutTime" BO_ 2654208049 2500;
BA_ "GenMsgDelayTime" BO_ 2654208049 500;
BA_ "Type" BO_ 950 11;
BA_ "GenMsgILSupport" BO_ 950 1;
BA_ "Period [ms]" BO_ 775 200;
BA_ "Type" BO_ 775 3;
BA_ "GenMsgSendType" BO_ 775 0;
BA_ "GenMsgTimeoutTime" BO_ 775 2500;
BA_ "GenMsgILSupport" BO_ 775 1;
BA_ "GenMsgStartDelayTime" BO_ 775 100;
BA_ "GenMsgCycleTime" BO_ 775 200;
BA_ "GenMsgDelayTime" BO_ 775 20;
BA_ "Type" BO_ 948 11;
BA_ "GenMsgILSupport" BO_ 948 1;
BA_ "GenMsgDelayTime" BO_ 948 50;
BA_ "Period [ms]" BO_ 1890 1000;
BA_ "Type" BO_ 1890 1;
BA_ "GenMsgSendType" BO_ 1890 0;
BA_ "GenMsgILSupport" BO_ 1890 1;
BA_ "GenMsgStartDelayTime" BO_ 1890 650;
BA_ "GenMsgCycleTime" BO_ 1890 1000;
BA_ "Period [ms]" BO_ 2000 1500;
BA_ "Type" BO_ 2000 3;
BA_ "GenMsgSendType" BO_ 2000 0;
BA_ "GenMsgTimeoutTime" BO_ 2000 2500;
BA_ "GenMsgILSupport" BO_ 2000 1;
BA_ "GenMsgStartDelayTime" BO_ 2000 50;
BA_ "GenMsgCycleTime" BO_ 2000 1500;
BA_ "GenMsgDelayTime" BO_ 2000 20;
BA_ "Period [ms]" BO_ 854 250;
BA_ "Type" BO_ 854 3;
BA_ "GenMsgSendType" BO_ 854 0;
BA_ "GenMsgILSupport" BO_ 854 1;
BA_ "GenMsgStartDelayTime" BO_ 854 190;
BA_ "GenMsgCycleTime" BO_ 854 250;
BA_ "GenMsgDelayTime" BO_ 854 20;
BA_ "Period [ms]" BO_ 1132 500;
BA_ "Type" BO_ 1132 3;
BA_ "GenMsgSendType" BO_ 1132 0;
BA_ "GenMsgILSupport" BO_ 1132 1;
BA_ "GenMsgStartDelayTime" BO_ 1132 250;
BA_ "GenMsgCycleTime" BO_ 1132 500;
BA_ "GenMsgDelayTime" BO_ 1132 20;
BA_ "Period [ms]" BO_ 1128 500;
BA_ "Type" BO_ 1128 3;
BA_ "GenMsgSendType" BO_ 1128 0;
BA_ "GenMsgILSupport" BO_ 1128 1;
BA_ "GenMsgStartDelayTime" BO_ 1128 250;
BA_ "GenMsgCycleTime" BO_ 1128 500;
BA_ "GenMsgDelayTime" BO_ 1128 20;
BA_ "Period [ms]" BO_ 988 100;
BA_ "Type" BO_ 988 1;
BA_ "GenMsgSendType" BO_ 988 0;
BA_ "GenMsgTimeoutTime" BO_ 988 2500;
BA_ "GenMsgILSupport" BO_ 988 1;
BA_ "GenMsgStartDelayTime" BO_ 988 10;
BA_ "GenMsgCycleTime" BO_ 988 100;
BA_ "Period [ms]" BO_ 990 100;
BA_ "Type" BO_ 990 1;
BA_ "GenMsgSendType" BO_ 990 0;
BA_ "GenMsgILSupport" BO_ 990 1;
BA_ "GenMsgStartDelayTime" BO_ 990 25;
BA_ "GenMsgCycleTime" BO_ 990 100;
BA_ "Period [ms]" BO_ 994 100;
BA_ "Type" BO_ 994 1;
BA_ "GenMsgSendType" BO_ 994 0;
BA_ "GenMsgTimeoutTime" BO_ 994 2500;
BA_ "GenMsgILSupport" BO_ 994 1;
BA_ "GenMsgStartDelayTime" BO_ 994 60;
BA_ "GenMsgCycleTime" BO_ 994 100;
BA_ "Period [ms]" BO_ 996 100;
BA_ "Type" BO_ 996 1;
BA_ "GenMsgSendType" BO_ 996 0;
BA_ "GenMsgILSupport" BO_ 996 1;
BA_ "GenMsgStartDelayTime" BO_ 996 75;
BA_ "GenMsgCycleTime" BO_ 996 100;
BA_ "Period [ms]" BO_ 998 100;
BA_ "Type" BO_ 998 1;
BA_ "GenMsgSendType" BO_ 998 0;
BA_ "GenMsgILSupport" BO_ 998 1;
BA_ "GenMsgStartDelayTime" BO_ 998 90;
BA_ "GenMsgCycleTime" BO_ 998 100;
BA_ "Period [ms]" BO_ 1984 2000;
BA_ "Type" BO_ 1984 1;
BA_ "GenMsgSendType" BO_ 1984 0;
BA_ "GenMsgILSupport" BO_ 1984 1;
BA_ "GenMsgStartDelayTime" BO_ 1984 1000;
BA_ "GenMsgCycleTime" BO_ 1984 2000;
BA_ "Period [ms]" BO_ 1130 500;
BA_ "Type" BO_ 1130 3;
BA_ "GenMsgSendType" BO_ 1130 0;
BA_ "GenMsgILSupport" BO_ 1130 1;
BA_ "GenMsgStartDelayTime" BO_ 1130 250;
BA_ "GenMsgCycleTime" BO_ 1130 500;
BA_ "GenMsgDelayTime" BO_ 1130 20;
BA_ "Period [ms]" BO_ 1098 500;
BA_ "Type" BO_ 1098 3;
BA_ "GenMsgSendType" BO_ 1098 0;
BA_ "GenMsgTimeoutTime" BO_ 1098 2500;
BA_ "GenMsgILSupport" BO_ 1098 1;
BA_ "GenMsgStartDelayTime" BO_ 1098 250;
BA_ "GenMsgCycleTime" BO_ 1098 500;
BA_ "GenMsgDelayTime" BO_ 1098 20;
BA_ "Period [ms]" BO_ 1462 1000;
BA_ "Type" BO_ 1462 3;
BA_ "GenMsgSendType" BO_ 1462 0;
BA_ "GenMsgILSupport" BO_ 1462 1;
BA_ "GenMsgStartDelayTime" BO_ 1462 250;
BA_ "GenMsgCycleTime" BO_ 1462 1000;
BA_ "GenMsgDelayTime" BO_ 1462 20;
BA_ "Type" BO_ 1268 11;
BA_ "GenMsgILSupport" BO_ 1268 1;
BA_ "GenMsgDelayTime" BO_ 1268 50;
BA_ "Period [ms]" BO_ 1100 500;
BA_ "Type" BO_ 1100 3;
BA_ "GenMsgSendType" BO_ 1100 0;
BA_ "GenMsgTimeoutTime" BO_ 1100 2500;
BA_ "GenMsgILSupport" BO_ 1100 1;
BA_ "GenMsgStartDelayTime" BO_ 1100 250;
BA_ "GenMsgCycleTime" BO_ 1100 500;
BA_ "GenMsgDelayTime" BO_ 1100 20;
BA_ "Period [ms]" BO_ 1470 1000;
BA_ "Type" BO_ 1470 3;
BA_ "GenMsgSendType" BO_ 1470 0;
BA_ "GenMsgILSupport" BO_ 1470 1;
BA_ "GenMsgStartDelayTime" BO_ 1470 170;
BA_ "GenMsgCycleTime" BO_ 1470 1000;
BA_ "GenMsgDelayTime" BO_ 1470 50;
BA_ "Period [ms]" BO_ 1464 250;
BA_ "Type" BO_ 1464 1;
BA_ "GenMsgSendType" BO_ 1464 0;
BA_ "GenMsgTimeoutTime" BO_ 1464 2500;
BA_ "GenMsgILSupport" BO_ 1464 1;
BA_ "GenMsgCycleTime" BO_ 1464 250;
BA_ "Period [ms]" BO_ 846 250;
BA_ "Type" BO_ 846 3;
BA_ "GenMsgSendType" BO_ 846 0;
BA_ "GenMsgTimeoutTime" BO_ 846 2500;
BA_ "GenMsgILSupport" BO_ 846 1;
BA_ "GenMsgStartDelayTime" BO_ 846 120;
BA_ "GenMsgCycleTime" BO_ 846 250;
BA_ "GenMsgDelayTime" BO_ 846 10;
BA_ "Type" BO_ 750 7;
BA_ "GenMsgTimeoutTime" BO_ 750 2500;
BA_ "GenMsgILSupport" BO_ 750 1;
BA_ "GenMsgDelayTime" BO_ 750 20;
BA_ "Type" BO_ 144 12;
BA_ "GenMsgILSupport" BO_ 144 1;
BA_ "GenMsgDelayTime" BO_ 144 20;
BA_ "Type" BO_ 136 7;
BA_ "GenMsgILSupport" BO_ 136 1;
BA_ "GenMsgDelayTime" BO_ 136 20;
BA_ "Type" BO_ 156 8;
BA_ "GenMsgILSupport" BO_ 156 1;
BA_ "GenMsgDelayTime" BO_ 156 20;
BA_ "Type" BO_ 158 8;
BA_ "GenMsgILSupport" BO_ 158 1;
BA_ "GenMsgDelayTime" BO_ 158 100;
BA_ "Type" BO_ 162 8;
BA_ "GenMsgILSupport" BO_ 162 1;
BA_ "GenMsgDelayTime" BO_ 162 100;
BA_ "Period [ms]" BO_ 1892 1000;
BA_ "Type" BO_ 1892 1;
BA_ "GenMsgSendType" BO_ 1892 0;
BA_ "GenMsgILSupport" BO_ 1892 1;
BA_ "GenMsgStartDelayTime" BO_ 1892 750;
BA_ "GenMsgCycleTime" BO_ 1892 1000;
BA_ "Period [ms]" BO_ 1472 1000;
BA_ "Type" BO_ 1472 3;
BA_ "GenMsgSendType" BO_ 1472 0;
BA_ "GenMsgILSupport" BO_ 1472 1;
BA_ "GenMsgStartDelayTime" BO_ 1472 220;
BA_ "GenMsgCycleTime" BO_ 1472 1000;
BA_ "GenMsgDelayTime" BO_ 1472 20;
BA_ "Period [ms]" BO_ 1888 1000;
BA_ "Type" BO_ 1888 1;
BA_ "GenMsgSendType" BO_ 1888 0;
BA_ "GenMsgILSupport" BO_ 1888 1;
BA_ "GenMsgStartDelayTime" BO_ 1888 500;
BA_ "GenMsgCycleTime" BO_ 1888 1000;
BA_ "Period [ms]" BO_ 1476 1000;
BA_ "Type" BO_ 1476 3;
BA_ "GenMsgSendType" BO_ 1476 0;
BA_ "GenMsgILSupport" BO_ 1476 1;
BA_ "GenMsgStartDelayTime" BO_ 1476 360;
BA_ "GenMsgCycleTime" BO_ 1476 1000;
BA_ "GenMsgDelayTime" BO_ 1476 20;
BA_ "Type" BO_ 748 9;
BA_ "GenMsgTimeoutTime" BO_ 748 2500;
BA_ "GenMsgNrOfRepetition" BO_ 748 2;
BA_ "GenMsgILSupport" BO_ 748 1;
BA_ "GenMsgCycleTimeFast" BO_ 748 100;
BA_ "GenMsgDelayTime" BO_ 748 20;
BA_ "Type" BO_ 1976 8;
BA_ "GenMsgTimeoutTime" BO_ 1976 2500;
BA_ "GenMsgILSupport" BO_ 1976 1;
BA_ "GenMsgDelayTime" BO_ 1976 20;
BA_ "Period [ms]" BO_ 992 100;
BA_ "Type" BO_ 992 1;
BA_ "GenMsgSendType" BO_ 992 0;
BA_ "GenMsgILSupport" BO_ 992 1;
BA_ "GenMsgStartDelayTime" BO_ 992 40;
BA_ "GenMsgCycleTime" BO_ 992 100;
BA_ "Type" BO_ 152 8;
BA_ "GenMsgTimeoutTime" BO_ 152 2500;
BA_ "GenMsgILSupport" BO_ 152 1;
BA_ "GenMsgDelayTime" BO_ 152 10;
BA_ "Type" BO_ 154 11;
BA_ "GenMsgTimeoutTime" BO_ 154 2500;
BA_ "GenMsgILSupport" BO_ 154 1;
BA_ "Accuracy" SG_ 1884 IgnitionOnCounter "- ";
BA_ "Accuracy" SG_ 1474 AIAAlarmCauseSts "- ";
BA_ "Event trans." SG_ 1474 AIAAlarmCauseSts 0;
BA_ "GenSigSendType" SG_ 1474 AIAAlarmCauseSts 3;
BA_ "Accuracy" SG_ 1474 AlarmFailSts "- ";
BA_ "Event trans." SG_ 1474 AlarmFailSts 0;
BA_ "GenSigSendType" SG_ 1474 AlarmFailSts 3;
BA_ "Accuracy" SG_ 1474 BonnetAlarmCauseSts "- ";
BA_ "Event trans." SG_ 1474 BonnetAlarmCauseSts 0;
BA_ "GenSigSendType" SG_ 1474 BonnetAlarmCauseSts 3;
BA_ "Accuracy" SG_ 1474 DoorsAlarmCauseSts "- ";
BA_ "Event trans." SG_ 1474 DoorsAlarmCauseSts 0;
BA_ "GenSigSendType" SG_ 1474 DoorsAlarmCauseSts 3;
BA_ "Accuracy" SG_ 1474 ElectricalAlarmCauseSts "- ";
BA_ "Event trans." SG_ 1474 ElectricalAlarmCauseSts 0;
BA_ "GenSigSendType" SG_ 1474 ElectricalAlarmCauseSts 3;
BA_ "Accuracy" SG_ 1474 PanicModeActive "- ";
BA_ "Event trans." SG_ 1474 PanicModeActive 0;
BA_ "GenSigSendType" SG_ 1474 PanicModeActive 3;
BA_ "Accuracy" SG_ 1474 TrunkAlarmCauseSts "- ";
BA_ "Event trans." SG_ 1474 TrunkAlarmCauseSts 0;
BA_ "GenSigSendType" SG_ 1474 TrunkAlarmCauseSts 3;
BA_ "Accuracy" SG_ 1474 USAlarmCauseSts "- ";
BA_ "Event trans." SG_ 1474 USAlarmCauseSts 0;
BA_ "GenSigSendType" SG_ 1474 USAlarmCauseSts 3;
BA_ "Accuracy" SG_ 160 BCMFpsCommand "- ";
BA_ "Event trans." SG_ 160 BCMFpsCommand 0;
BA_ "GenSigSendType" SG_ 160 BCMFpsCommand 2;
BA_ "Accuracy" SG_ 160 BCMFpsConfirm "- ";
BA_ "Event trans." SG_ 160 BCMFpsConfirm 0;
BA_ "GenSigStartValue" SG_ 160 BCMFpsConfirm 1;
BA_ "GenSigSendType" SG_ 160 BCMFpsConfirm 2;
BA_ "Accuracy" SG_ 160 BCMFpsFailSts "- ";
BA_ "Event trans." SG_ 160 BCMFpsFailSts 0;
BA_ "GenSigSendType" SG_ 160 BCMFpsFailSts 2;
BA_ "Event trans." SG_ 2651930624 Digit_01 0;
BA_ "GenSigSendType" SG_ 2651930624 Digit_01 1;
BA_ "Accuracy" SG_ 2651930670 Digit_01_AMP "- ";
BA_ "Event trans." SG_ 2651930670 Digit_01_AMP 0;
BA_ "GenSigSendType" SG_ 2651930670 Digit_01_AMP 1;
BA_ "Accuracy" SG_ 2651930670 Digit_02_AMP "- ";
BA_ "Accuracy" SG_ 2651930670 Digit_03_AMP "- ";
BA_ "Accuracy" SG_ 2651930670 Digit_04_AMP "- ";
BA_ "Accuracy" SG_ 2651930670 Digit_05_AMP "- ";
BA_ "Accuracy" SG_ 2651930670 Digit_06_AMP "- ";
BA_ "Accuracy" SG_ 2651930670 Digit_07_AMP "- ";
BA_ "Accuracy" SG_ 2651930670 Digit_08_AMP "- ";
BA_ "Accuracy" SG_ 2651930670 Digit_09_AMP "- ";
BA_ "Accuracy" SG_ 2651930670 Digit_10_AMP "- ";
BA_ "Accuracy" SG_ 2651930670 Digit_11_AMP "- ";
BA_ "Accuracy" SG_ 2651930634 Digit_01_CLM "- ";
BA_ "Event trans." SG_ 2651930634 Digit_01_CLM 0;
BA_ "GenSigSendType" SG_ 2651930634 Digit_01_CLM 1;
BA_ "Accuracy" SG_ 2651930634 Digit_02_CLM "- ";
BA_ "Accuracy" SG_ 2651930634 Digit_03_CLM "- ";
BA_ "Accuracy" SG_ 2651930634 Digit_04_CLM "- ";
BA_ "Accuracy" SG_ 2651930634 Digit_05_CLM "- ";
BA_ "Accuracy" SG_ 2651930634 Digit_06_CLM "- ";
BA_ "Accuracy" SG_ 2651930634 Digit_07_CLM "- ";
BA_ "Accuracy" SG_ 2651930634 Digit_08_CLM "- ";
BA_ "Accuracy" SG_ 2651930634 Digit_09_CLM "- ";
BA_ "Accuracy" SG_ 2651930634 Digit_10_CLM "- ";
BA_ "Accuracy" SG_ 2651930634 Digit_11_CLM "- ";
BA_ "Accuracy" SG_ 2651930675 Digit_01_LBSS "- ";
BA_ "Event trans." SG_ 2651930675 Digit_01_LBSS 0;
BA_ "GenSigSendType" SG_ 2651930675 Digit_01_LBSS 1;
BA_ "Accuracy" SG_ 2651930675 Digit_02_LBSS "- ";
BA_ "Accuracy" SG_ 2651930675 Digit_03_LBSS "- ";
BA_ "Accuracy" SG_ 2651930675 Digit_04_LBSS "- ";
BA_ "Accuracy" SG_ 2651930675 Digit_05_LBSS "- ";
BA_ "Accuracy" SG_ 2651930675 Digit_06_LBSS "- ";
BA_ "Accuracy" SG_ 2651930675 Digit_07_LBSS "- ";
BA_ "Accuracy" SG_ 2651930675 Digit_08_LBSS "- ";
BA_ "Accuracy" SG_ 2651930675 Digit_09_LBSS "- ";
BA_ "Accuracy" SG_ 2651930675 Digit_10_LBSS "- ";
BA_ "Accuracy" SG_ 2651930675 Digit_11_LBSS "- ";
BA_ "Accuracy" SG_ 2651930676 Digit_01_RBSS "- ";
BA_ "Event trans." SG_ 2651930676 Digit_01_RBSS 0;
BA_ "GenSigSendType" SG_ 2651930676 Digit_01_RBSS 1;
BA_ "Accuracy" SG_ 2651930676 Digit_02_RBSS "- ";
BA_ "Accuracy" SG_ 2651930676 Digit_03_RBSS "- ";
BA_ "Accuracy" SG_ 2651930676 Digit_04_RBSS "- ";
BA_ "Accuracy" SG_ 2651930676 Digit_05_RBSS "- ";
BA_ "Accuracy" SG_ 2651930676 Digit_06_RBSS "- ";
BA_ "Accuracy" SG_ 2651930676 Digit_07_RBSS "- ";
BA_ "Accuracy" SG_ 2651930676 Digit_08_RBSS "- ";
BA_ "Accuracy" SG_ 2651930676 Digit_09_RBSS "- ";
BA_ "Accuracy" SG_ 2651930676 Digit_10_RBSS "- ";
BA_ "Accuracy" SG_ 2651930676 Digit_11_RBSS "- ";
BA_ "Accuracy" SG_ 2651930660 Digit_01_TLM "- ";
BA_ "Event trans." SG_ 2651930660 Digit_01_TLM 0;
BA_ "GenSigSendType" SG_ 2651930660 Digit_01_TLM 1;
BA_ "Accuracy" SG_ 2651930660 Digit_02_TLM "- ";
BA_ "Accuracy" SG_ 2651930660 Digit_03_TLM "- ";
BA_ "Accuracy" SG_ 2651930660 Digit_04_TLM "- ";
BA_ "Accuracy" SG_ 2651930660 Digit_05_TLM "- ";
BA_ "Accuracy" SG_ 2651930660 Digit_06_TLM "- ";
BA_ "Accuracy" SG_ 2651930660 Digit_07_TLM "- ";
BA_ "Accuracy" SG_ 2651930660 Digit_08_TLM "- ";
BA_ "Accuracy" SG_ 2651930660 Digit_09_TLM "- ";
BA_ "Accuracy" SG_ 2651930660 Digit_10_TLM "- ";
BA_ "Accuracy" SG_ 2651930660 Digit_11_TLM "- ";
BA_ "Accuracy" SG_ 2651930687 Digit_01_TTM "- ";
BA_ "Event trans." SG_ 2651930687 Digit_01_TTM 0;
BA_ "GenSigSendType" SG_ 2651930687 Digit_01_TTM 1;
BA_ "Accuracy" SG_ 2651930687 Digit_02_TTM "- ";
BA_ "Accuracy" SG_ 2651930687 Digit_03_TTM "- ";
BA_ "Accuracy" SG_ 2651930687 Digit_04_TTM "- ";
BA_ "Accuracy" SG_ 2651930687 Digit_05_TTM "- ";
BA_ "Accuracy" SG_ 2651930687 Digit_06_TTM "- ";
BA_ "Accuracy" SG_ 2651930687 Digit_07_TTM "- ";
BA_ "Accuracy" SG_ 2651930687 Digit_08_TTM "- ";
BA_ "Accuracy" SG_ 2651930687 Digit_09_TTM "- ";
BA_ "Accuracy" SG_ 2651930687 Digit_10_TTM "- ";
BA_ "Accuracy" SG_ 2651930687 Digit_11_TTM "- ";
BA_ "Accuracy" SG_ 134 FPS_Status_Request "- ";
BA_ "Event trans." SG_ 134 FPS_Status_Request 0;
BA_ "GenSigSendType" SG_ 134 FPS_Status_Request 2;
BA_ "Event trans." SG_ 1478 AUD_LVLSts 0;
BA_ "GenSigSendType" SG_ 1478 AUD_LVLSts 3;
BA_ "Event trans." SG_ 1478 BAL_LVLSts 0;
BA_ "GenSigStartValue" SG_ 1478 BAL_LVLSts 10;
BA_ "GenSigSendType" SG_ 1478 BAL_LVLSts 3;
BA_ "Event trans." SG_ 1478 BASS_LVLSts 0;
BA_ "GenSigStartValue" SG_ 1478 BASS_LVLSts 10;
BA_ "GenSigSendType" SG_ 1478 BASS_LVLSts 3;
BA_ "Event trans." SG_ 1478 DSS_ONSts 0;
BA_ "GenSigSendType" SG_ 1478 DSS_ONSts 3;
BA_ "Event trans." SG_ 1478 FD_LVLSts 0;
BA_ "GenSigStartValue" SG_ 1478 FD_LVLSts 10;
BA_ "GenSigSendType" SG_ 1478 FD_LVLSts 3;
BA_ "Event trans." SG_ 1478 INFO1_AUD_ACT 0;
BA_ "GenSigSendType" SG_ 1478 INFO1_AUD_ACT 3;
BA_ "Event trans." SG_ 1478 INFO1_AUD_LEVEL 0;
BA_ "GenSigSendType" SG_ 1478 INFO1_AUD_LEVEL 3;
BA_ "Event trans." SG_ 1478 INFO1_AUD_TYPE 0;
BA_ "GenSigSendType" SG_ 1478 INFO1_AUD_TYPE 3;
BA_ "Event trans." SG_ 1478 INFO2_AUD_ACT 0;
BA_ "GenSigSendType" SG_ 1478 INFO2_AUD_ACT 3;
BA_ "Event trans." SG_ 1478 INFO2_AUD_LEVEL 0;
BA_ "GenSigSendType" SG_ 1478 INFO2_AUD_LEVEL 3;
BA_ "Event trans." SG_ 1478 INFO2_AUD_TYPE 0;
BA_ "GenSigSendType" SG_ 1478 INFO2_AUD_TYPE 3;
BA_ "Event trans." SG_ 1478 MID_LVLSts 0;
BA_ "GenSigStartValue" SG_ 1478 MID_LVLSts 10;
BA_ "GenSigSendType" SG_ 1478 MID_LVLSts 3;
BA_ "Event trans." SG_ 1478 SCV_LVLSts 0;
BA_ "GenSigSendType" SG_ 1478 SCV_LVLSts 3;
BA_ "Event trans." SG_ 1478 TREB_LVLSts 0;
BA_ "GenSigStartValue" SG_ 1478 TREB_LVLSts 10;
BA_ "GenSigSendType" SG_ 1478 TREB_LVLSts 3;
BA_ "Accuracy" SG_ 2564473329 N_PDU "- ";
BA_ "Accuracy" SG_ 2564485507 N_PDU "- ";
BA_ "Accuracy" SG_ 2564485474 N_PDU "- ";
BA_ "Accuracy" SG_ 2564485477 N_PDU "- ";
BA_ "Accuracy" SG_ 2564485450 N_PDU "- ";
BA_ "Accuracy" SG_ 2564485569 N_PDU "- ";
BA_ "Accuracy" SG_ 852 AHBFeature "- ";
BA_ "Event trans." SG_ 852 AHBFeature 0;
BA_ "GenSigSendType" SG_ 852 AHBFeature 3;
BA_ "Accuracy" SG_ 852 AlertLightsON "- ";
BA_ "Event trans." SG_ 852 AlertLightsON 0;
BA_ "GenSigSendType" SG_ 852 AlertLightsON 3;
BA_ "Accuracy" SG_ 852 DRLFault "- ";
BA_ "Accuracy" SG_ 852 FHeatedWindowSts "- ";
BA_ "Event trans." SG_ 852 FHeatedWindowSts 0;
BA_ "GenSigSendType" SG_ 852 FHeatedWindowSts 3;
BA_ "Accuracy" SG_ 852 FrontFogLightSts "- ";
BA_ "Event trans." SG_ 852 FrontFogLightSts 0;
BA_ "GenSigSendType" SG_ 852 FrontFogLightSts 3;
BA_ "Accuracy" SG_ 852 HeatedMirrorSts "- ";
BA_ "Event trans." SG_ 852 HeatedMirrorSts 0;
BA_ "GenSigSendType" SG_ 852 HeatedMirrorSts 3;
BA_ "Accuracy" SG_ 852 HighBeamSts "- ";
BA_ "Event trans." SG_ 852 HighBeamSts 0;
BA_ "GenSigSendType" SG_ 852 HighBeamSts 3;
BA_ "Accuracy" SG_ 852 L_TurnLightActivationSts "- ";
BA_ "Event trans." SG_ 852 L_TurnLightActivationSts 0;
BA_ "GenSigSendType" SG_ 852 L_TurnLightActivationSts 3;
BA_ "Accuracy" SG_ 852 LHParkingLightSts "- ";
BA_ "Event trans." SG_ 852 LHParkingLightSts 0;
BA_ "GenSigSendType" SG_ 852 LHParkingLightSts 3;
BA_ "Accuracy" SG_ 852 LHTurnLightFault "- ";
BA_ "Accuracy" SG_ 852 LHTurnSignalSts "- ";
BA_ "Event trans." SG_ 852 LHTurnSignalSts 0;
BA_ "GenSigSendType" SG_ 852 LHTurnSignalSts 3;
BA_ "Accuracy" SG_ 852 LowBeamSts "- ";
BA_ "Event trans." SG_ 852 LowBeamSts 0;
BA_ "GenSigSendType" SG_ 852 LowBeamSts 3;
BA_ "Accuracy" SG_ 852 ParkingLightFault "- ";
BA_ "Accuracy" SG_ 852 PlateLightFault "- ";
BA_ "Accuracy" SG_ 852 R_TurnLightActivationSts "- ";
BA_ "Event trans." SG_ 852 R_TurnLightActivationSts 0;
BA_ "GenSigSendType" SG_ 852 R_TurnLightActivationSts 3;
BA_ "Accuracy" SG_ 852 RearFogLightFault "- ";
BA_ "Accuracy" SG_ 852 RearFogLightSts "- ";
BA_ "Event trans." SG_ 852 RearFogLightSts 0;
BA_ "GenSigSendType" SG_ 852 RearFogLightSts 3;
BA_ "Accuracy" SG_ 852 ReverseGearLightFault "- ";
BA_ "Accuracy" SG_ 852 RHeatedWindowSts "- ";
BA_ "Event trans." SG_ 852 RHeatedWindowSts 0;
BA_ "GenSigSendType" SG_ 852 RHeatedWindowSts 3;
BA_ "Accuracy" SG_ 852 RHParkingLightSts "- ";
BA_ "Event trans." SG_ 852 RHParkingLightSts 0;
BA_ "GenSigSendType" SG_ 852 RHParkingLightSts 3;
BA_ "Accuracy" SG_ 852 RHTurnLightFault "- ";
BA_ "Accuracy" SG_ 852 RHTurnSignalSts "- ";
BA_ "Event trans." SG_ 852 RHTurnSignalSts 0;
BA_ "GenSigSendType" SG_ 852 RHTurnSignalSts 3;
BA_ "Accuracy" SG_ 852 StopLightFault "- ";
BA_ "Accuracy" SG_ 852 StopLightSts "- ";
BA_ "Event trans." SG_ 852 StopLightSts 0;
BA_ "GenSigSendType" SG_ 852 StopLightSts 3;
BA_ "Accuracy" SG_ 986 DisplayInfoReceptionSts "- ";
BA_ "Event trans." SG_ 986 DisplayInfoReceptionSts 0;
BA_ "GenSigSendType" SG_ 986 DisplayInfoReceptionSts 1;
BA_ "Accuracy" SG_ 146 Focus "- ";
BA_ "Event trans." SG_ 146 Focus 0;
BA_ "GenSigSendType" SG_ 146 Focus 3;
BA_ "Accuracy" SG_ 146 List "- ";
BA_ "Event trans." SG_ 146 List 0;
BA_ "GenSigSendType" SG_ 146 List 3;
BA_ "Accuracy" SG_ 146 SMS_PopUp "- ";
BA_ "Event trans." SG_ 146 SMS_PopUp 0;
BA_ "GenSigSendType" SG_ 146 SMS_PopUp 3;
BA_ "Accuracy" SG_ 146 Status_DOWN "- ";
BA_ "Event trans." SG_ 146 Status_DOWN 0;
BA_ "GenSigSendType" SG_ 146 Status_DOWN 3;
BA_ "Accuracy" SG_ 146 Status_LEFT "- ";
BA_ "Event trans." SG_ 146 Status_LEFT 0;
BA_ "GenSigSendType" SG_ 146 Status_LEFT 3;
BA_ "Accuracy" SG_ 146 Status_OK "- ";
BA_ "Event trans." SG_ 146 Status_OK 0;
BA_ "GenSigSendType" SG_ 146 Status_OK 3;
BA_ "Accuracy" SG_ 146 Status_RIGHT "- ";
BA_ "Event trans." SG_ 146 Status_RIGHT 0;
BA_ "GenSigSendType" SG_ 146 Status_RIGHT 3;
BA_ "Accuracy" SG_ 146 Status_UP "- ";
BA_ "Event trans." SG_ 146 Status_UP 0;
BA_ "GenSigSendType" SG_ 146 Status_UP 3;
BA_ "Event trans." SG_ 1468 AmbientLightingLevel 0;
BA_ "GenSigStartValue" SG_ 1468 AmbientLightingLevel 4;
BA_ "GenSigSendType" SG_ 1468 AmbientLightingLevel 3;
BA_ "Event trans." SG_ 1468 AudioRepetition 0;
BA_ "GenSigSendType" SG_ 1468 AudioRepetition 3;
BA_ "Accuracy" SG_ 1468 AutoHighBeamEnable "- ";
BA_ "Event trans." SG_ 1468 AutoHighBeamEnable 0;
BA_ "GenSigStartValue" SG_ 1468 AutoHighBeamEnable 1;
BA_ "GenSigSendType" SG_ 1468 AutoHighBeamEnable 3;
BA_ "Event trans." SG_ 1468 AutomaticResetTripB 0;
BA_ "GenSigSendType" SG_ 1468 AutomaticResetTripB 3;
BA_ "Event trans." SG_ 1468 AutoParkBrake 0;
BA_ "GenSigSendType" SG_ 1468 AutoParkBrake 3;
BA_ "Event trans." SG_ 1468 AutoRelock 0;
BA_ "GenSigSendType" SG_ 1468 AutoRelock 3;
BA_ "Event trans." SG_ 1468 BSDEnable 0;
BA_ "GenSigStartValue" SG_ 1468 BSDEnable 2;
BA_ "GenSigSendType" SG_ 1468 BSDEnable 3;
BA_ "Accuracy" SG_ 1468 ConsumptionUnit "- ";
BA_ "Event trans." SG_ 1468 ConsumptionUnit 0;
BA_ "GenSigSendType" SG_ 1468 ConsumptionUnit 3;
BA_ "Accuracy" SG_ 1468 CorneringEnable "- ";
BA_ "Event trans." SG_ 1468 CorneringEnable 0;
BA_ "GenSigSendType" SG_ 1468 CorneringEnable 3;
BA_ "Accuracy" SG_ 1468 DistanceUnit "- ";
BA_ "Event trans." SG_ 1468 DistanceUnit 0;
BA_ "GenSigSendType" SG_ 1468 DistanceUnit 3;
BA_ "Accuracy" SG_ 1468 DRLEnable "- ";
BA_ "Event trans." SG_ 1468 DRLEnable 0;
BA_ "GenSigSendType" SG_ 1468 DRLEnable 3;
BA_ "Accuracy" SG_ 1468 ExternalLightSensorLevel "- ";
BA_ "Event trans." SG_ 1468 ExternalLightSensorLevel 0;
BA_ "GenSigStartValue" SG_ 1468 ExternalLightSensorLevel 1;
BA_ "GenSigSendType" SG_ 1468 ExternalLightSensorLevel 3;
BA_ "Accuracy" SG_ 1468 GreetingLightsEnable "- ";
BA_ "Event trans." SG_ 1468 GreetingLightsEnable 0;
BA_ "GenSigSendType" SG_ 1468 GreetingLightsEnable 3;
BA_ "Accuracy" SG_ 1468 HourMode "- ";
BA_ "Event trans." SG_ 1468 HourMode 0;
BA_ "GenSigSendType" SG_ 1468 HourMode 3;
BA_ "Accuracy" SG_ 1468 LanguageSelection "- ";
BA_ "Event trans." SG_ 1468 LanguageSelection 0;
BA_ "GenSigSendType" SG_ 1468 LanguageSelection 3;
BA_ "Event trans." SG_ 1468 NavRepetition 0;
BA_ "GenSigSendType" SG_ 1468 NavRepetition 3;
BA_ "Event trans." SG_ 1468 PamAlertMode 0;
BA_ "GenSigStartValue" SG_ 1468 PamAlertMode 2;
BA_ "GenSigSendType" SG_ 1468 PamAlertMode 3;
BA_ "Event trans." SG_ 1468 PamChimeVolumeFront 0;
BA_ "GenSigStartValue" SG_ 1468 PamChimeVolumeFront 1;
BA_ "GenSigSendType" SG_ 1468 PamChimeVolumeFront 3;
BA_ "Event trans." SG_ 1468 PamChimeVolumeRear 0;
BA_ "GenSigStartValue" SG_ 1468 PamChimeVolumeRear 1;
BA_ "GenSigSendType" SG_ 1468 PamChimeVolumeRear 3;
BA_ "Event trans." SG_ 1468 PassiveEntry 0;
BA_ "GenSigSendType" SG_ 1468 PassiveEntry 3;
BA_ "Event trans." SG_ 1468 PhoneRepetition 0;
BA_ "GenSigSendType" SG_ 1468 PhoneRepetition 3;
BA_ "Accuracy" SG_ 1468 RainSensorLevel "- ";
BA_ "Event trans." SG_ 1468 RainSensorLevel 0;
BA_ "GenSigStartValue" SG_ 1468 RainSensorLevel 1;
BA_ "GenSigSendType" SG_ 1468 RainSensorLevel 3;
BA_ "Event trans." SG_ 1468 RemoteDoorUnlock 0;
BA_ "GenSigStartValue" SG_ 1468 RemoteDoorUnlock 1;
BA_ "GenSigSendType" SG_ 1468 RemoteDoorUnlock 3;
BA_ "Event trans." SG_ 1468 Sdw 0;
BA_ "GenSigStartValue" SG_ 1468 Sdw 2;
BA_ "GenSigSendType" SG_ 1468 Sdw 3;
BA_ "Event trans." SG_ 1468 SdwChimeVolume 0;
BA_ "GenSigStartValue" SG_ 1468 SdwChimeVolume 1;
BA_ "GenSigSendType" SG_ 1468 SdwChimeVolume 3;
BA_ "Event trans." SG_ 1468 SoundHornLock 0;
BA_ "GenSigStartValue" SG_ 1468 SoundHornLock 1;
BA_ "GenSigSendType" SG_ 1468 SoundHornLock 3;
BA_ "Event trans." SG_ 1468 SoundHornRemoteStart 0;
BA_ "GenSigSendType" SG_ 1468 SoundHornRemoteStart 3;
BA_ "Accuracy" SG_ 1468 SpeedLockDoorEnable "- ";
BA_ "Event trans." SG_ 1468 SpeedLockDoorEnable 0;
BA_ "GenSigSendType" SG_ 1468 SpeedLockDoorEnable 3;
BA_ "Accuracy" SG_ 1468 TelematicSetupACK "- ";
BA_ "Event trans." SG_ 1468 TelematicSetupACK 0;
BA_ "GenSigSendType" SG_ 1468 TelematicSetupACK 3;
BA_ "Accuracy" SG_ 1468 TemperatureUnit "- ";
BA_ "Event trans." SG_ 1468 TemperatureUnit 0;
BA_ "GenSigSendType" SG_ 1468 TemperatureUnit 3;
BA_ "Accuracy" SG_ 1486 AutoUnlockDoorExit "- ";
BA_ "Event trans." SG_ 1486 AutoUnlockDoorExit 0;
BA_ "GenSigStartValue" SG_ 1486 AutoUnlockDoorExit 1;
BA_ "GenSigSendType" SG_ 1486 AutoUnlockDoorExit 3;
BA_ "Accuracy" SG_ 1486 EPB_Maintenance_Fdbk "- ";
BA_ "Event trans." SG_ 1486 EPB_Maintenance_Fdbk 0;
BA_ "GenSigSendType" SG_ 1486 EPB_Maintenance_Fdbk 3;
BA_ "Accuracy" SG_ 1486 EPB_MaintenanceMode "- ";
BA_ "Event trans." SG_ 1486 EPB_MaintenanceMode 0;
BA_ "GenSigSendType" SG_ 1486 EPB_MaintenanceMode 3;
BA_ "Accuracy" SG_ 1486 FlashLightWLock "- ";
BA_ "Event trans." SG_ 1486 FlashLightWLock 0;
BA_ "GenSigStartValue" SG_ 1486 FlashLightWLock 1;
BA_ "GenSigSendType" SG_ 1486 FlashLightWLock 3;
BA_ "Accuracy" SG_ 1486 FSFCWPlusActivationMode "- ";
BA_ "Event trans." SG_ 1486 FSFCWPlusActivationMode 0;
BA_ "GenSigStartValue" SG_ 1486 FSFCWPlusActivationMode 1;
BA_ "GenSigSendType" SG_ 1486 FSFCWPlusActivationMode 3;
BA_ "Accuracy" SG_ 1486 FSFCWPlusSetting "- ";
BA_ "Event trans." SG_ 1486 FSFCWPlusSetting 0;
BA_ "GenSigStartValue" SG_ 1486 FSFCWPlusSetting 3;
BA_ "GenSigSendType" SG_ 1486 FSFCWPlusSetting 3;
BA_ "Accuracy" SG_ 1486 HeadlightsOffDelay "- ";
BA_ "Event trans." SG_ 1486 HeadlightsOffDelay 0;
BA_ "GenSigSendType" SG_ 1486 HeadlightsOffDelay 3;
BA_ "Accuracy" SG_ 1486 LDW_Intensity "- ";
BA_ "Event trans." SG_ 1486 LDW_Intensity 0;
BA_ "GenSigStartValue" SG_ 1486 LDW_Intensity 2;
BA_ "GenSigSendType" SG_ 1486 LDW_Intensity 3;
BA_ "Accuracy" SG_ 1486 LDW_Sensibility "- ";
BA_ "Event trans." SG_ 1486 LDW_Sensibility 0;
BA_ "GenSigStartValue" SG_ 1486 LDW_Sensibility 2;
BA_ "GenSigSendType" SG_ 1486 LDW_Sensibility 3;
BA_ "Accuracy" SG_ 1486 TyrePressureUnit "- ";
BA_ "Event trans." SG_ 1486 TyrePressureUnit 0;
BA_ "GenSigStartValue" SG_ 1486 TyrePressureUnit 2;
BA_ "GenSigSendType" SG_ 1486 TyrePressureUnit 3;
BA_ "Event trans." SG_ 773 LbssSysBlockIndSts 0;
BA_ "GenSigSendType" SG_ 773 LbssSysBlockIndSts 3;
BA_ "Event trans." SG_ 773 LbssSysInterfIndSts 0;
BA_ "GenSigSendType" SG_ 773 LbssSysInterfIndSts 3;
BA_ "Event trans." SG_ 773 LbssSysSrvIndSts 0;
BA_ "GenSigSendType" SG_ 773 LbssSysSrvIndSts 3;
BA_ "Event trans." SG_ 773 LbssTmpUnavIndSts 0;
BA_ "GenSigSendType" SG_ 773 LbssTmpUnavIndSts 3;
BA_ "Accuracy" SG_ 2654208046 ActiveLoadSlave_AMP "- ";
BA_ "Accuracy" SG_ 2654208046 CurrentFailSts_AMP "- ";
BA_ "Accuracy" SG_ 2654208046 D_ES_AMP "- ";
BA_ "Accuracy" SG_ 2654208046 EOL_AMP "- ";
BA_ "Accuracy" SG_ 2654208046 GenericFailSts_AMP "- ";
BA_ "Accuracy" SG_ 2654208046 SystemStatus_AMP "- ";
BA_ "Accuracy" SG_ 2654208046 Zero_byte_AMP "- ";
BA_ "Accuracy" SG_ 2654208000 ActiveLoadMaster "- ";
BA_ "Accuracy" SG_ 2654208000 D_ES_BCM "- ";
BA_ "Accuracy" SG_ 2654208000 EOL_BCM "- ";
BA_ "Accuracy" SG_ 2654208000 GenericFailSts_BCM "- ";
BA_ "Accuracy" SG_ 2654208000 Node0 "- ";
BA_ "Accuracy" SG_ 2654208000 Node1 "- ";
BA_ "Accuracy" SG_ 2654208000 Node10 "- ";
BA_ "Accuracy" SG_ 2654208000 Node11 "- ";
BA_ "Accuracy" SG_ 2654208000 Node12 "- ";
BA_ "Accuracy" SG_ 2654208000 Node13 "- ";
BA_ "Accuracy" SG_ 2654208000 Node14 "- ";
BA_ "Accuracy" SG_ 2654208000 Node15 "- ";
BA_ "Accuracy" SG_ 2654208000 Node16 "- ";
BA_ "Accuracy" SG_ 2654208000 Node17 "- ";
BA_ "Accuracy" SG_ 2654208000 Node18 "- ";
BA_ "Accuracy" SG_ 2654208000 Node19 "- ";
BA_ "Accuracy" SG_ 2654208000 Node2 "- ";
BA_ "Accuracy" SG_ 2654208000 Node20 "- ";
BA_ "Accuracy" SG_ 2654208000 Node21 "- ";
BA_ "Accuracy" SG_ 2654208000 Node22 "- ";
BA_ "Accuracy" SG_ 2654208000 Node23 "- ";
BA_ "Accuracy" SG_ 2654208000 Node24 "- ";
BA_ "Accuracy" SG_ 2654208000 Node25 "- ";
BA_ "Accuracy" SG_ 2654208000 Node26 "- ";
BA_ "Accuracy" SG_ 2654208000 Node27 "- ";
BA_ "Accuracy" SG_ 2654208000 Node28 "- ";
BA_ "Accuracy" SG_ 2654208000 Node29 "- ";
BA_ "Accuracy" SG_ 2654208000 Node3 "- ";
BA_ "Accuracy" SG_ 2654208000 Node30 "- ";
BA_ "Accuracy" SG_ 2654208000 Node31 "- ";
BA_ "Accuracy" SG_ 2654208000 Node4 "- ";
BA_ "Accuracy" SG_ 2654208000 Node5 "- ";
BA_ "Accuracy" SG_ 2654208000 Node6 "- ";
BA_ "Accuracy" SG_ 2654208000 Node7 "- ";
BA_ "Accuracy" SG_ 2654208000 Node8 "- ";
BA_ "Accuracy" SG_ 2654208000 Node9 "- ";
BA_ "Accuracy" SG_ 2654208000 P_ES "- ";
BA_ "Accuracy" SG_ 2654208000 SystemCommand "- ";
BA_ "Accuracy" SG_ 2654208000 Zero_byte_BCM "- ";
BA_ "Accuracy" SG_ 2654208010 ActiveLoadSlave_Climate "- ";
BA_ "Accuracy" SG_ 2654208010 CurrentFailSts_Climate "- ";
BA_ "Accuracy" SG_ 2654208010 D_ES_Climate "- ";
BA_ "Accuracy" SG_ 2654208010 EOL_Climate "- ";
BA_ "Accuracy" SG_ 2654208010 GenericFailSts_Climate "- ";
BA_ "Accuracy" SG_ 2654208010 SystemStatus_Climate "- ";
BA_ "Accuracy" SG_ 2654208010 Zero_byte_Climate "- ";
BA_ "Accuracy" SG_ 2654208003 ActiveLoadSlave_IPC "- ";
BA_ "Accuracy" SG_ 2654208003 CurrentFailSts_IPC "- ";
BA_ "Accuracy" SG_ 2654208003 D_ES_IPC "- ";
BA_ "Accuracy" SG_ 2654208003 EOL_IPC "- ";
BA_ "Accuracy" SG_ 2654208003 GenericFailSts_IPC "- ";
BA_ "Accuracy" SG_ 2654208003 SystemStatus_IPC "- ";
BA_ "Accuracy" SG_ 2654208003 Zero_byte_IPC "- ";
BA_ "Accuracy" SG_ 2654208051 ActiveLoadSlave_LBSS "- ";
BA_ "Accuracy" SG_ 2654208051 CurrentFailSts_LBSS "- ";
BA_ "Accuracy" SG_ 2654208051 D_ES_LBSS "- ";
BA_ "Accuracy" SG_ 2654208051 EOL_LBSS "- ";
BA_ "Accuracy" SG_ 2654208051 GenericFailSts_LBSS "- ";
BA_ "Accuracy" SG_ 2654208051 SystemStatus_LBSS "- ";
BA_ "Accuracy" SG_ 2654208051 Zero_byte_LBSS "- ";
BA_ "Accuracy" SG_ 2654208052 ActiveLoadSlave_RBSS "- ";
BA_ "Accuracy" SG_ 2654208052 CurrentFailSts_RBSS "- ";
BA_ "Accuracy" SG_ 2654208052 D_ES_RBSS "- ";
BA_ "Accuracy" SG_ 2654208052 EOL_RBSS "- ";
BA_ "Accuracy" SG_ 2654208052 GenericFailSts_RBSS "- ";
BA_ "Accuracy" SG_ 2654208052 SystemStatus_RBSS "- ";
BA_ "Accuracy" SG_ 2654208052 Zero_byte_RBSS "- ";
BA_ "Accuracy" SG_ 2654208036 ActiveLoadSlave_Telematic "- ";
BA_ "Accuracy" SG_ 2654208036 CurrentFailSts_Telematic "- ";
BA_ "Accuracy" SG_ 2654208036 D_ES_Telematic "- ";
BA_ "Accuracy" SG_ 2654208036 EOL_Telematic "- ";
BA_ "Accuracy" SG_ 2654208036 GenericFailSts_Telematic "- ";
BA_ "Accuracy" SG_ 2654208036 SystemStatus_Telematic "- ";
BA_ "Accuracy" SG_ 2654208036 Zero_byte_Telematic "- ";
BA_ "Accuracy" SG_ 2654208063 ActiveLoadSlave_TTM "- ";
BA_ "Accuracy" SG_ 2654208063 CurrentFailSts_TTM "- ";
BA_ "Accuracy" SG_ 2654208063 D_ES_TTM "- ";
BA_ "Accuracy" SG_ 2654208063 EOL_TTM "- ";
BA_ "Accuracy" SG_ 2654208063 GenericFailSts_TTM "- ";
BA_ "Accuracy" SG_ 2654208063 SystemStatus_TTM "- ";
BA_ "Accuracy" SG_ 2654208063 Zero_byte_TTM "- ";
BA_ "Accuracy" SG_ 2654208049 ActiveLoadSlave_VTM "- ";
BA_ "Accuracy" SG_ 2654208049 CurrentFailSts_VTM "- ";
BA_ "Accuracy" SG_ 2654208049 D_ES_VTM "- ";
BA_ "Accuracy" SG_ 2654208049 EOL_VTM "- ";
BA_ "Accuracy" SG_ 2654208049 GenericFailSts_VTM "- ";
BA_ "Accuracy" SG_ 2654208049 SystemStatus_VTM "- ";
BA_ "Accuracy" SG_ 2654208049 Zero_byte_VTM "- ";
BA_ "Event trans." SG_ 775 RbssSysBlockIndSts 0;
BA_ "GenSigSendType" SG_ 775 RbssSysBlockIndSts 3;
BA_ "Event trans." SG_ 775 RbssSysInterfIndSts 0;
BA_ "GenSigSendType" SG_ 775 RbssSysInterfIndSts 3;
BA_ "Event trans." SG_ 775 RbssSysSrvIndSts 0;
BA_ "GenSigSendType" SG_ 775 RbssSysSrvIndSts 3;
BA_ "Event trans." SG_ 775 RbssTmpUnavIndSts 0;
BA_ "GenSigSendType" SG_ 775 RbssTmpUnavIndSts 3;
BA_ "Accuracy" SG_ 1890 DaysToService "- ";
BA_ "Accuracy" SG_ 1890 DistanceToService "- ";
BA_ "Event trans." SG_ 2000 AMP_DSS_STATSts 0;
BA_ "GenSigSendType" SG_ 2000 AMP_DSS_STATSts 3;
BA_ "Event trans." SG_ 2000 AMP_MUTEDSts 0;
BA_ "GenSigSendType" SG_ 2000 AMP_MUTEDSts 3;
BA_ "Event trans." SG_ 2000 AUDIOSts_AMP 0;
BA_ "GenSigSendType" SG_ 2000 AUDIOSts_AMP 3;
BA_ "Event trans." SG_ 2000 PowerModeSts_AMP 0;
BA_ "GenSigSendType" SG_ 2000 PowerModeSts_AMP 3;
BA_ "Event trans." SG_ 2000 SURR_AVAILSts 0;
BA_ "GenSigSendType" SG_ 2000 SURR_AVAILSts 3;
BA_ "Accuracy" SG_ 854 AlarmSysTurnOn "- ";
BA_ "Accuracy" SG_ 854 BonnetSts "- ";
BA_ "Event trans." SG_ 854 BonnetSts 0;
BA_ "GenSigSendType" SG_ 854 BonnetSts 3;
BA_ "Accuracy" SG_ 854 BrakeFluidLevelSts "- ";
BA_ "Accuracy" SG_ 854 DriverDoorSts "- ";
BA_ "Event trans." SG_ 854 DriverDoorSts 0;
BA_ "GenSigSendType" SG_ 854 DriverDoorSts 3;
BA_ "Accuracy" SG_ 854 FuelLevel "+/- 2.5 at 17.5% ";
BA_ "Accuracy" SG_ 854 FuelLevelFailSts "- ";
BA_ "Accuracy" SG_ 854 IMMOCodeWarningLightSts "- ";
BA_ "Event trans." SG_ 854 IMMOCodeWarningLightSts 0;
BA_ "GenSigSendType" SG_ 854 IMMOCodeWarningLightSts 3;
BA_ "Accuracy" SG_ 854 LHRDoorSts "- ";
BA_ "Event trans." SG_ 854 LHRDoorSts 0;
BA_ "GenSigSendType" SG_ 854 LHRDoorSts 3;
BA_ "Accuracy" SG_ 854 LowFuelWarningSts "- ";
BA_ "Event trans." SG_ 854 LowFuelWarningSts 0;
BA_ "GenSigSendType" SG_ 854 LowFuelWarningSts 3;
BA_ "Event trans." SG_ 854 NightAndDaySensorFailSts 0;
BA_ "GenSigSendType" SG_ 854 NightAndDaySensorFailSts 3;
BA_ "Event trans." SG_ 854 OperationalModeSts 0;
BA_ "GenSigSendType" SG_ 854 OperationalModeSts 3;
BA_ "Accuracy" SG_ 854 ParkBrakeSts "- ";
BA_ "Event trans." SG_ 854 ParkBrakeSts 0;
BA_ "GenSigSendType" SG_ 854 ParkBrakeSts 3;
BA_ "Accuracy" SG_ 854 PsngrDoorSts "- ";
BA_ "Event trans." SG_ 854 PsngrDoorSts 0;
BA_ "GenSigSendType" SG_ 854 PsngrDoorSts 3;
BA_ "Accuracy" SG_ 854 RainSensorFailSts "- ";
BA_ "Accuracy" SG_ 854 RHatchSts "- ";
BA_ "Event trans." SG_ 854 RHatchSts 0;
BA_ "GenSigSendType" SG_ 854 RHatchSts 3;
BA_ "Accuracy" SG_ 854 RHRDoorSts "- ";
BA_ "Event trans." SG_ 854 RHRDoorSts 0;
BA_ "GenSigSendType" SG_ 854 RHRDoorSts 3;
BA_ "Event trans." SG_ 854 StopStartActivationSts 0;
BA_ "GenSigSendType" SG_ 854 StopStartActivationSts 3;
BA_ "Event trans." SG_ 854 StopStartVisualizationCode 0;
BA_ "GenSigSendType" SG_ 854 StopStartVisualizationCode 3;
BA_ "Accuracy" SG_ 854 SysEOLSts "- ";
BA_ "Accuracy" SG_ 854 WarningKeyInSts "- ";
BA_ "Accuracy" SG_ 1132 BatteryChargeSts "5 ";
BA_ "Accuracy" SG_ 1132 BatteryVoltageLevel "0,05 ";
BA_ "Event trans." SG_ 1132 CmdIgn_FailSts 0;
BA_ "GenSigSendType" SG_ 1132 CmdIgn_FailSts 3;
BA_ "Event trans." SG_ 1132 CmdIgnSts 0;
BA_ "GenSigSendType" SG_ 1132 CmdIgnSts 3;
BA_ "Accuracy" SG_ 1132 CurrentFailStsIBS "- ";
BA_ "Event trans." SG_ 1132 DriveStyleSts 0;
BA_ "GenSigSendType" SG_ 1132 DriveStyleSts 3;
BA_ "GenSigStartValue" SG_ 1132 ExternalTemperatureC 511;
BA_ "GenSigStartValue" SG_ 1132 ExternalTemperatureF 511;
BA_ "Accuracy" SG_ 1132 ExternalTemperatureFailSts "- ";
BA_ "Event trans." SG_ 1132 Int_Relay_FailSts 0;
BA_ "GenSigSendType" SG_ 1132 Int_Relay_FailSts 3;
BA_ "Event trans." SG_ 1132 InternalLightLevel 0;
BA_ "GenSigStartValue" SG_ 1132 InternalLightLevel 5;
BA_ "GenSigSendType" SG_ 1132 InternalLightLevel 3;
BA_ "Event trans." SG_ 1132 InternalLightSts 0;
BA_ "GenSigSendType" SG_ 1132 InternalLightSts 3;
BA_ "Event trans." SG_ 1132 RemStActvSts 0;
BA_ "GenSigSendType" SG_ 1132 RemStActvSts 3;
BA_ "Event trans." SG_ 1132 TurnIndicationSts 0;
BA_ "GenSigSendType" SG_ 1132 TurnIndicationSts 3;
BA_ "Event trans." SG_ 1128 ClusterLightSts 0;
BA_ "GenSigSendType" SG_ 1128 ClusterLightSts 3;
BA_ "Accuracy" SG_ 1128 SPM_Mode_Selection "- ";
BA_ "Event trans." SG_ 1128 SPM_Mode_Selection 0;
BA_ "GenSigSendType" SG_ 1128 SPM_Mode_Selection 3;
BA_ "GenSigStartValue" SG_ 988 AFSts 8;
BA_ "Accuracy" SG_ 988 LatAcceleration_BSM "- ";
BA_ "Accuracy" SG_ 988 LatAccelerationFailSts_BSM "- ";
BA_ "Accuracy" SG_ 988 LongAcceleration_BSM "- ";
BA_ "Accuracy" SG_ 988 LongAccelerationFailSts_BSM "- ";
BA_ "Accuracy" SG_ 988 YawRate_BSM "- ";
BA_ "Accuracy" SG_ 988 YawRateFailSts_BSM "- ";
BA_ "Accuracy" SG_ 990 LHF_FastPulseCounter "- ";
BA_ "Accuracy" SG_ 990 LHF_FastPulseCounter_Overflow "- ";
BA_ "Accuracy" SG_ 990 LHF_WheelSensorFailSts "- ";
BA_ "Accuracy" SG_ 990 LHR_FastPulseCounter "- ";
BA_ "Accuracy" SG_ 990 LHR_FastPulseCounter_Overflow "- ";
BA_ "Accuracy" SG_ 990 LHR_WheelSensorFailSts "- ";
BA_ "Accuracy" SG_ 990 RHF_FastPulseCounter "- ";
BA_ "Accuracy" SG_ 990 RHF_FastPulseCounter_Overflow "- ";
BA_ "Accuracy" SG_ 990 RHF_WheelSensorFailSts "- ";
BA_ "Accuracy" SG_ 990 RHR_FastPulseCounter "- ";
BA_ "Accuracy" SG_ 990 RHR_FastPulseCounter_Overflow "- ";
BA_ "Accuracy" SG_ 990 RHR_WheelSensorFailSts "- ";
BA_ "GenSigStartValue" SG_ 994 ACPressure 511;
BA_ "GenSigStartValue" SG_ 994 AlternatorFail 1;
BA_ "GenSigStartValue" SG_ 994 CompressorSts 2;
BA_ "GenSigStartValue" SG_ 994 EngineSts 3;
BA_ "Accuracy" SG_ 994 EngineWaterTemp "- ";
BA_ "Accuracy" SG_ 994 EngineWaterTempFailSts "- ";
BA_ "Accuracy" SG_ 996 DPFSts "- ";
BA_ "Accuracy" SG_ 996 FuelConsumption_GAG "- ";
BA_ "Accuracy" SG_ 996 GearShiftIndication "- ";
BA_ "GenSigStartValue" SG_ 998 ShiftLeverPosition 9;
BA_ "Accuracy" SG_ 1984 InflationState_LHF_Tyre "- ";
BA_ "Accuracy" SG_ 1984 InflationState_LHR_Tyre "- ";
BA_ "Accuracy" SG_ 1984 InflationState_RHF_Tyre "- ";
BA_ "Accuracy" SG_ 1984 InflationState_RHR_Tyre "- ";
BA_ "Accuracy" SG_ 1984 TyrePressureSystemFailSts "- ";
BA_ "GenSigStartValue" SG_ 1130 A2D_DRV_TEMP_DR_POS 819;
BA_ "GenSigStartValue" SG_ 1130 A2D_FT_HVAC_BLOWER_VOLTAGE 479;
BA_ "Accuracy" SG_ 1130 AcOutputCurrentSts "- ";
BA_ "Accuracy" SG_ 1130 CompressorACReqSts "- ";
BA_ "Event trans." SG_ 1130 CompressorACReqSts 0;
BA_ "GenSigSendType" SG_ 1130 CompressorACReqSts 3;
BA_ "Accuracy" SG_ 1130 FHeatedWindowCmd "- ";
BA_ "Event trans." SG_ 1130 FHeatedWindowCmd 0;
BA_ "GenSigSendType" SG_ 1130 FHeatedWindowCmd 3;
BA_ "Event trans." SG_ 1130 HVAC_SAM_enable 0;
BA_ "GenSigSendType" SG_ 1130 HVAC_SAM_enable 3;
BA_ "Accuracy" SG_ 1130 MaxDefrostSts "- ";
BA_ "Event trans." SG_ 1130 MaxDefrostSts 0;
BA_ "GenSigSendType" SG_ 1130 MaxDefrostSts 3;
BA_ "Accuracy" SG_ 1130 PowerModeSts_Climate "- ";
BA_ "Event trans." SG_ 1130 PowerModeSts_Climate 0;
BA_ "GenSigSendType" SG_ 1130 PowerModeSts_Climate 3;
BA_ "Accuracy" SG_ 1130 PTCFailSts "- ";
BA_ "Event trans." SG_ 1130 PTCFailSts 0;
BA_ "GenSigSendType" SG_ 1130 PTCFailSts 3;
BA_ "Accuracy" SG_ 1130 PTCSts "- ";
BA_ "Event trans." SG_ 1130 PTCSts 0;
BA_ "GenSigSendType" SG_ 1130 PTCSts 3;
BA_ "Accuracy" SG_ 1130 RHeatedWindowCmd "- ";
BA_ "Event trans." SG_ 1130 RHeatedWindowCmd 0;
BA_ "GenSigSendType" SG_ 1130 RHeatedWindowCmd 3;
BA_ "Accuracy" SG_ 1130 StopStartEnable "- ";
BA_ "Event trans." SG_ 1130 StopStartEnable 0;
BA_ "GenSigStartValue" SG_ 1130 StopStartEnable 1;
BA_ "GenSigSendType" SG_ 1130 StopStartEnable 3;
BA_ "Event trans." SG_ 1098 BSS_LF_Chime_RQSts 0;
BA_ "GenSigSendType" SG_ 1098 BSS_LF_Chime_RQSts 3;
BA_ "Event trans." SG_ 1098 BSS_LR_Chime_RQSts 0;
BA_ "GenSigSendType" SG_ 1098 BSS_LR_Chime_RQSts 3;
BA_ "Event trans." SG_ 1098 BSS_LT_Blind_RQSts 0;
BA_ "GenSigSendType" SG_ 1098 BSS_LT_Blind_RQSts 3;
BA_ "Event trans." SG_ 1098 BSS_LT_CFG_STATSts 0;
BA_ "GenSigSendType" SG_ 1098 BSS_LT_CFG_STATSts 3;
BA_ "Event trans." SG_ 1098 BSS_LT_Chime_TypeSts 0;
BA_ "GenSigSendType" SG_ 1098 BSS_LT_Chime_TypeSts 3;
BA_ "Event trans." SG_ 1098 BSS_LT_OPR_StatSts 0;
BA_ "GenSigSendType" SG_ 1098 BSS_LT_OPR_StatSts 3;
BA_ "Event trans." SG_ 1098 BSS_LT_SRV_RQSts 0;
BA_ "GenSigSendType" SG_ 1098 BSS_LT_SRV_RQSts 3;
BA_ "Event trans." SG_ 1098 BssLtLedFaultSts 0;
BA_ "GenSigSendType" SG_ 1098 BssLtLedFaultSts 3;
BA_ "Event trans." SG_ 1098 BssLtWrnSts 0;
BA_ "GenSigSendType" SG_ 1098 BssLtWrnSts 3;
BA_ "Event trans." SG_ 1462 DynamicGridFailSts 0;
BA_ "GenSigSendType" SG_ 1462 DynamicGridFailSts 3;
BA_ "Event trans." SG_ 1462 DynamicGridSts 0;
BA_ "GenSigStartValue" SG_ 1462 DynamicGridSts 1;
BA_ "GenSigSendType" SG_ 1462 DynamicGridSts 3;
BA_ "Event trans." SG_ 1462 SWSError 0;
BA_ "GenSigSendType" SG_ 1462 SWSError 3;
BA_ "Accuracy" SG_ 1268 HMICode "- ";
BA_ "Accuracy" SG_ 1268 PAMSystemFault "- ";
BA_ "Accuracy" SG_ 1268 SPMControlSts "- ";
BA_ "Accuracy" SG_ 1268 SPMFailSts "- ";
BA_ "Event trans." SG_ 1100 BSS_RF_Chime_RQSts 0;
BA_ "GenSigSendType" SG_ 1100 BSS_RF_Chime_RQSts 3;
BA_ "Event trans." SG_ 1100 BSS_RR_Chime_RQSts 0;
BA_ "GenSigSendType" SG_ 1100 BSS_RR_Chime_RQSts 3;
BA_ "Event trans." SG_ 1100 BSS_RT_Blind_RQSts 0;
BA_ "GenSigSendType" SG_ 1100 BSS_RT_Blind_RQSts 3;
BA_ "Event trans." SG_ 1100 BSS_RT_CFG_STATSts 0;
BA_ "GenSigSendType" SG_ 1100 BSS_RT_CFG_STATSts 3;
BA_ "Event trans." SG_ 1100 BSS_RT_Chime_TypeSts 0;
BA_ "GenSigSendType" SG_ 1100 BSS_RT_Chime_TypeSts 3;
BA_ "Event trans." SG_ 1100 BSS_RT_OPR_StatSts 0;
BA_ "GenSigSendType" SG_ 1100 BSS_RT_OPR_StatSts 3;
BA_ "Event trans." SG_ 1100 BSS_RT_SRV_RQSts 0;
BA_ "GenSigSendType" SG_ 1100 BSS_RT_SRV_RQSts 3;
BA_ "Event trans." SG_ 1100 BssRtLedFaultSts 0;
BA_ "GenSigSendType" SG_ 1100 BssRtLedFaultSts 3;
BA_ "Event trans." SG_ 1100 BssRtWrnSts 0;
BA_ "GenSigSendType" SG_ 1100 BssRtWrnSts 3;
BA_ "Accuracy" SG_ 1470 AntitheftSts "- ";
BA_ "Event trans." SG_ 1470 AntitheftSts 0;
BA_ "GenSigSendType" SG_ 1470 AntitheftSts 3;
BA_ "Accuracy" SG_ 1470 AUDIOSts_Telematic "- ";
BA_ "Event trans." SG_ 1470 AUDIOSts_Telematic 0;
BA_ "GenSigSendType" SG_ 1470 AUDIOSts_Telematic 3;
BA_ "Accuracy" SG_ 1470 CurrentSource "- ";
BA_ "Event trans." SG_ 1470 CurrentSource 0;
BA_ "GenSigSendType" SG_ 1470 CurrentSource 3;
BA_ "Accuracy" SG_ 1470 HFPSts "- ";
BA_ "Event trans." SG_ 1470 HFPSts 0;
BA_ "GenSigSendType" SG_ 1470 HFPSts 3;
BA_ "Accuracy" SG_ 1470 MuteSts "- ";
BA_ "Event trans." SG_ 1470 MuteSts 0;
BA_ "GenSigSendType" SG_ 1470 MuteSts 3;
BA_ "Accuracy" SG_ 1470 PowerModeSts_Telematic "- ";
BA_ "Event trans." SG_ 1470 PowerModeSts_Telematic 0;
BA_ "GenSigSendType" SG_ 1470 PowerModeSts_Telematic 3;
BA_ "Accuracy" SG_ 1470 PowerSts_Telematic "- ";
BA_ "Event trans." SG_ 1470 PowerSts_Telematic 0;
BA_ "GenSigSendType" SG_ 1470 PowerSts_Telematic 3;
BA_ "Accuracy" SG_ 1470 VRSts "- ";
BA_ "Event trans." SG_ 1470 VRSts 0;
BA_ "GenSigSendType" SG_ 1470 VRSts 3;
BA_ "Accuracy" SG_ 846 VTMFailSts "- ";
BA_ "Accuracy" SG_ 846 VTMLightFailSts "- ";
BA_ "Accuracy" SG_ 846 VTMSts "- ";
BA_ "Event trans." SG_ 846 VTMSts 0;
BA_ "GenSigSendType" SG_ 846 VTMSts 3;
BA_ "Event trans." SG_ 750 Command_01Sts 0;
BA_ "GenSigSendType" SG_ 750 Command_01Sts 3;
BA_ "Event trans." SG_ 750 Command_02Sts 0;
BA_ "GenSigSendType" SG_ 750 Command_02Sts 3;
BA_ "Event trans." SG_ 750 Command_03Sts 0;
BA_ "GenSigSendType" SG_ 750 Command_03Sts 3;
BA_ "Event trans." SG_ 750 Command_04Sts 0;
BA_ "GenSigSendType" SG_ 750 Command_04Sts 3;
BA_ "Event trans." SG_ 750 Command_05Sts 0;
BA_ "GenSigSendType" SG_ 750 Command_05Sts 3;
BA_ "Event trans." SG_ 750 Command_06Sts 0;
BA_ "GenSigSendType" SG_ 750 Command_06Sts 3;
BA_ "Event trans." SG_ 750 Command_07Sts 0;
BA_ "GenSigSendType" SG_ 750 Command_07Sts 3;
BA_ "Event trans." SG_ 750 Command_08Sts 0;
BA_ "GenSigSendType" SG_ 750 Command_08Sts 3;
BA_ "Event trans." SG_ 750 Command_09Sts 0;
BA_ "GenSigSendType" SG_ 750 Command_09Sts 3;
BA_ "Event trans." SG_ 750 Command_10Sts 0;
BA_ "GenSigSendType" SG_ 750 Command_10Sts 3;
BA_ "Event trans." SG_ 750 Command_11Sts 0;
BA_ "GenSigSendType" SG_ 750 Command_11Sts 3;
BA_ "Event trans." SG_ 750 Command_12Sts 0;
BA_ "GenSigSendType" SG_ 750 Command_12Sts 3;
BA_ "Event trans." SG_ 750 Command_13Sts 0;
BA_ "GenSigSendType" SG_ 750 Command_13Sts 3;
BA_ "Event trans." SG_ 750 Command_14Sts 0;
BA_ "GenSigSendType" SG_ 750 Command_14Sts 3;
BA_ "Event trans." SG_ 750 Command_15Sts 0;
BA_ "GenSigSendType" SG_ 750 Command_15Sts 3;
BA_ "Accuracy" SG_ 144 FrameNumber "- ";
BA_ "Event trans." SG_ 144 FrameNumber 0;
BA_ "GenSigSendType" SG_ 144 FrameNumber 1;
BA_ "Accuracy" SG_ 144 InfoCode "- ";
BA_ "Accuracy" SG_ 144 TotalFrameNumber "- ";
BA_ "Accuracy" SG_ 144 UTF_Text_1 "- ";
BA_ "Accuracy" SG_ 144 UTF_Text_2 "- ";
BA_ "Accuracy" SG_ 144 UTF_Text_3 "- ";
BA_ "Accuracy" SG_ 136 Direction "- ";
BA_ "Event trans." SG_ 136 Direction 0;
BA_ "GenSigSendType" SG_ 136 Direction 3;
BA_ "Accuracy" SG_ 136 DistToTurn "- ";
BA_ "Event trans." SG_ 136 DistToTurn 0;
BA_ "GenSigSendType" SG_ 136 DistToTurn 3;
BA_ "Accuracy" SG_ 136 LastAnnouncement "- ";
BA_ "Event trans." SG_ 136 LastAnnouncement 0;
BA_ "GenSigSendType" SG_ 136 LastAnnouncement 3;
BA_ "Accuracy" SG_ 136 ResolutionDistToTurn "- ";
BA_ "Accuracy" SG_ 136 Unit "- ";
BA_ "Event trans." SG_ 136 Unit 0;
BA_ "GenSigStartValue" SG_ 136 Unit 6;
BA_ "GenSigSendType" SG_ 136 Unit 3;
BA_ "Accuracy" SG_ 156 Day1_TLM "- ";
BA_ "Event trans." SG_ 156 Day1_TLM 0;
BA_ "GenSigSendType" SG_ 156 Day1_TLM 1;
BA_ "Accuracy" SG_ 156 Day2_TLM "- ";
BA_ "Accuracy" SG_ 156 Hour1_TLM "- ";
BA_ "Accuracy" SG_ 156 Hour2_TLM "- ";
BA_ "Accuracy" SG_ 156 Minute1_TLM "- ";
BA_ "Accuracy" SG_ 156 Minute2_TLM "- ";
BA_ "Accuracy" SG_ 156 Month1_TLM "- ";
BA_ "Accuracy" SG_ 156 Month2_TLM "- ";
BA_ "Accuracy" SG_ 156 Year1_TLM "- ";
BA_ "Accuracy" SG_ 156 Year2_TLM "- ";
BA_ "Accuracy" SG_ 156 Year3_TLM "- ";
BA_ "Accuracy" SG_ 156 Year4_TLM "- ";
BA_ "Event trans." SG_ 158 AmbientLightingLevel_Req 0;
BA_ "GenSigStartValue" SG_ 158 AmbientLightingLevel_Req 4;
BA_ "GenSigSendType" SG_ 158 AmbientLightingLevel_Req 1;
BA_ "Accuracy" SG_ 158 AutoHighBeamEnable_Req "- ";
BA_ "Event trans." SG_ 158 AutoHighBeamEnable_Req 0;
BA_ "GenSigStartValue" SG_ 158 AutoHighBeamEnable_Req 1;
BA_ "GenSigSendType" SG_ 158 AutoHighBeamEnable_Req 1;
BA_ "Event trans." SG_ 158 AutoParkBrake_Req 0;
BA_ "GenSigSendType" SG_ 158 AutoParkBrake_Req 1;
BA_ "Accuracy" SG_ 158 BSDEnable_Req "- ";
BA_ "Event trans." SG_ 158 BSDEnable_Req 0;
BA_ "GenSigStartValue" SG_ 158 BSDEnable_Req 2;
BA_ "GenSigSendType" SG_ 158 BSDEnable_Req 1;
BA_ "Accuracy" SG_ 158 ConsumptionUnit_Req "- ";
BA_ "Event trans." SG_ 158 ConsumptionUnit_Req 0;
BA_ "GenSigSendType" SG_ 158 ConsumptionUnit_Req 1;
BA_ "Accuracy" SG_ 158 CorneringEnable_Req "- ";
BA_ "Event trans." SG_ 158 CorneringEnable_Req 0;
BA_ "GenSigSendType" SG_ 158 CorneringEnable_Req 1;
BA_ "Accuracy" SG_ 158 DistanceUnit_Req "- ";
BA_ "Event trans." SG_ 158 DistanceUnit_Req 0;
BA_ "GenSigSendType" SG_ 158 DistanceUnit_Req 1;
BA_ "Accuracy" SG_ 158 DRLEnable_Req "- ";
BA_ "Event trans." SG_ 158 DRLEnable_Req 0;
BA_ "GenSigSendType" SG_ 158 DRLEnable_Req 1;
BA_ "Event trans." SG_ 158 DynamicGrid_Req 0;
BA_ "GenSigStartValue" SG_ 158 DynamicGrid_Req 1;
BA_ "GenSigSendType" SG_ 158 DynamicGrid_Req 1;
BA_ "Accuracy" SG_ 158 ExternalLightSensorLevel_Req "- ";
BA_ "Event trans." SG_ 158 ExternalLightSensorLevel_Req 0;
BA_ "GenSigStartValue" SG_ 158 ExternalLightSensorLevel_Req 1;
BA_ "GenSigSendType" SG_ 158 ExternalLightSensorLevel_Req 1;
BA_ "Accuracy" SG_ 158 GreetingLightsEnable_Req "- ";
BA_ "Event trans." SG_ 158 GreetingLightsEnable_Req 0;
BA_ "GenSigSendType" SG_ 158 GreetingLightsEnable_Req 1;
BA_ "Accuracy" SG_ 158 HourMode_Req "- ";
BA_ "Event trans." SG_ 158 HourMode_Req 0;
BA_ "GenSigSendType" SG_ 158 HourMode_Req 1;
BA_ "Accuracy" SG_ 158 LanguageSelection_Req "- ";
BA_ "Event trans." SG_ 158 LanguageSelection_Req 0;
BA_ "GenSigSendType" SG_ 158 LanguageSelection_Req 1;
BA_ "Event trans." SG_ 158 PamAlertMode_Req 0;
BA_ "GenSigStartValue" SG_ 158 PamAlertMode_Req 2;
BA_ "GenSigSendType" SG_ 158 PamAlertMode_Req 1;
BA_ "Event trans." SG_ 158 PamChimeVolumeFront_Req 0;
BA_ "GenSigStartValue" SG_ 158 PamChimeVolumeFront_Req 1;
BA_ "GenSigSendType" SG_ 158 PamChimeVolumeFront_Req 1;
BA_ "Event trans." SG_ 158 PamChimeVolumeRear_Req 0;
BA_ "GenSigStartValue" SG_ 158 PamChimeVolumeRear_Req 1;
BA_ "GenSigSendType" SG_ 158 PamChimeVolumeRear_Req 1;
BA_ "Event trans." SG_ 158 PassiveEntry_Req 0;
BA_ "GenSigSendType" SG_ 158 PassiveEntry_Req 1;
BA_ "Event trans." SG_ 158 PhoneRepetition_Req 0;
BA_ "GenSigSendType" SG_ 158 PhoneRepetition_Req 1;
BA_ "Accuracy" SG_ 158 RainSensorLevel_Req "- ";
BA_ "Event trans." SG_ 158 RainSensorLevel_Req 0;
BA_ "GenSigStartValue" SG_ 158 RainSensorLevel_Req 1;
BA_ "GenSigSendType" SG_ 158 RainSensorLevel_Req 1;
BA_ "Event trans." SG_ 158 RemoteDoorUnlock_Req 0;
BA_ "GenSigStartValue" SG_ 158 RemoteDoorUnlock_Req 1;
BA_ "GenSigSendType" SG_ 158 RemoteDoorUnlock_Req 1;
BA_ "Accuracy" SG_ 158 ResetTripA_Req "- ";
BA_ "Event trans." SG_ 158 ResetTripA_Req 0;
BA_ "GenSigSendType" SG_ 158 ResetTripA_Req 1;
BA_ "Accuracy" SG_ 158 ResetTripB_Req "- ";
BA_ "Event trans." SG_ 158 ResetTripB_Req 0;
BA_ "GenSigSendType" SG_ 158 ResetTripB_Req 1;
BA_ "Event trans." SG_ 158 Sdw_Req 0;
BA_ "GenSigStartValue" SG_ 158 Sdw_Req 2;
BA_ "GenSigSendType" SG_ 158 Sdw_Req 1;
BA_ "Event trans." SG_ 158 SdwChimeVolume_Req 0;
BA_ "GenSigStartValue" SG_ 158 SdwChimeVolume_Req 1;
BA_ "GenSigSendType" SG_ 158 SdwChimeVolume_Req 1;
BA_ "Event trans." SG_ 158 SoundHornLock_Req 0;
BA_ "GenSigStartValue" SG_ 158 SoundHornLock_Req 1;
BA_ "GenSigSendType" SG_ 158 SoundHornLock_Req 1;
BA_ "Event trans." SG_ 158 SoundHornRemoteStart_Req 0;
BA_ "GenSigSendType" SG_ 158 SoundHornRemoteStart_Req 1;
BA_ "Accuracy" SG_ 158 SpeedLockDoorEnable_Req "- ";
BA_ "Event trans." SG_ 158 SpeedLockDoorEnable_Req 0;
BA_ "GenSigSendType" SG_ 158 SpeedLockDoorEnable_Req 1;
BA_ "Accuracy" SG_ 158 TemperatureUnit_Req "- ";
BA_ "Event trans." SG_ 158 TemperatureUnit_Req 0;
BA_ "GenSigSendType" SG_ 158 TemperatureUnit_Req 1;
BA_ "Accuracy" SG_ 162 AutoUnlockDoorExit_Req "- ";
BA_ "Event trans." SG_ 162 AutoUnlockDoorExit_Req 0;
BA_ "GenSigStartValue" SG_ 162 AutoUnlockDoorExit_Req 1;
BA_ "GenSigSendType" SG_ 162 AutoUnlockDoorExit_Req 1;
BA_ "Accuracy" SG_ 162 EPB_MaintenanceMode_Req "- ";
BA_ "Event trans." SG_ 162 EPB_MaintenanceMode_Req 0;
BA_ "GenSigSendType" SG_ 162 EPB_MaintenanceMode_Req 1;
BA_ "Accuracy" SG_ 162 FlashLightWLock_Req "- ";
BA_ "Event trans." SG_ 162 FlashLightWLock_Req 0;
BA_ "GenSigStartValue" SG_ 162 FlashLightWLock_Req 1;
BA_ "GenSigSendType" SG_ 162 FlashLightWLock_Req 1;
BA_ "Accuracy" SG_ 162 FSFCWPlusActivationMode_Req "- ";
BA_ "Event trans." SG_ 162 FSFCWPlusActivationMode_Req 0;
BA_ "GenSigStartValue" SG_ 162 FSFCWPlusActivationMode_Req 1;
BA_ "GenSigSendType" SG_ 162 FSFCWPlusActivationMode_Req 1;
BA_ "Accuracy" SG_ 162 FSFCWPlusSetting_Req "- ";
BA_ "Event trans." SG_ 162 FSFCWPlusSetting_Req 0;
BA_ "GenSigStartValue" SG_ 162 FSFCWPlusSetting_Req 3;
BA_ "GenSigSendType" SG_ 162 FSFCWPlusSetting_Req 1;
BA_ "Accuracy" SG_ 162 HeadlightsOffDelay_Req "- ";
BA_ "Event trans." SG_ 162 HeadlightsOffDelay_Req 0;
BA_ "GenSigSendType" SG_ 162 HeadlightsOffDelay_Req 1;
BA_ "Accuracy" SG_ 162 LDW_Intensity_Req "- ";
BA_ "Event trans." SG_ 162 LDW_Intensity_Req 0;
BA_ "GenSigSendType" SG_ 162 LDW_Intensity_Req 1;
BA_ "Accuracy" SG_ 162 LDW_Sensibility_Req "- ";
BA_ "Event trans." SG_ 162 LDW_Sensibility_Req 0;
BA_ "GenSigStartValue" SG_ 162 LDW_Sensibility_Req 3;
BA_ "GenSigSendType" SG_ 162 LDW_Sensibility_Req 1;
BA_ "Accuracy" SG_ 162 TyrePressureUnit_Req "- ";
BA_ "Event trans." SG_ 162 TyrePressureUnit_Req 0;
BA_ "GenSigStartValue" SG_ 162 TyrePressureUnit_Req 2;
BA_ "GenSigSendType" SG_ 162 TyrePressureUnit_Req 1;
BA_ "Accuracy" SG_ 1892 Day1 "- ";
BA_ "Accuracy" SG_ 1892 Day2 "- ";
BA_ "Accuracy" SG_ 1892 Hour1 "- ";
BA_ "Accuracy" SG_ 1892 Hour2 "- ";
BA_ "Accuracy" SG_ 1892 Minute1 "- ";
BA_ "Accuracy" SG_ 1892 Minute2 "- ";
BA_ "Accuracy" SG_ 1892 Month1 "- ";
BA_ "Accuracy" SG_ 1892 Month2 "- ";
BA_ "Accuracy" SG_ 1892 Year1 "- ";
BA_ "Accuracy" SG_ 1892 Year2 "- ";
BA_ "Accuracy" SG_ 1892 Year3 "- ";
BA_ "Accuracy" SG_ 1892 Year4 "- ";
BA_ "Accuracy" SG_ 1472 AverageFuelConsumptionAPlus "- ";
BA_ "Event trans." SG_ 1472 AverageFuelConsumptionAPlus 0;
BA_ "GenSigSendType" SG_ 1472 AverageFuelConsumptionAPlus 3;
BA_ "Accuracy" SG_ 1472 AverageSpeedAPlus "- ";
BA_ "Event trans." SG_ 1472 AverageSpeedAPlus 0;
BA_ "GenSigSendType" SG_ 1472 AverageSpeedAPlus 3;
BA_ "Accuracy" SG_ 1472 PartialOdometerAPlus "- ";
BA_ "Event trans." SG_ 1472 PartialOdometerAPlus 0;
BA_ "GenSigSendType" SG_ 1472 PartialOdometerAPlus 3;
BA_ "Accuracy" SG_ 1472 ResetTripAPlusACK "- ";
BA_ "Event trans." SG_ 1472 ResetTripAPlusACK 0;
BA_ "GenSigSendType" SG_ 1472 ResetTripAPlusACK 3;
BA_ "Accuracy" SG_ 1472 TravelingTimeAPlus_Hour "- ";
BA_ "Event trans." SG_ 1472 TravelingTimeAPlus_Hour 0;
BA_ "GenSigSendType" SG_ 1472 TravelingTimeAPlus_Hour 3;
BA_ "Accuracy" SG_ 1472 TravelingTimeAPlus_Minute "- ";
BA_ "Event trans." SG_ 1472 TravelingTimeAPlus_Minute 0;
BA_ "GenSigSendType" SG_ 1472 TravelingTimeAPlus_Minute 3;
BA_ "Accuracy" SG_ 1472 TravelingTimeAPlus_Second "- ";
BA_ "Accuracy" SG_ 1888 AutonomyDistance "- ";
BA_ "Accuracy" SG_ 1888 InstantaneousFuelConsumption1 "- ";
BA_ "Accuracy" SG_ 1888 InstantaneousFuelConsumption2 "- ";
BA_ "Accuracy" SG_ 1888 InstantaneousFuelConsumption3 "- ";
BA_ "Accuracy" SG_ 1888 TotalOdometer "- ";
BA_ "Accuracy" SG_ 1476 AverageFuelConsumptionBPlus "- ";
BA_ "Event trans." SG_ 1476 AverageFuelConsumptionBPlus 0;
BA_ "GenSigSendType" SG_ 1476 AverageFuelConsumptionBPlus 3;
BA_ "Accuracy" SG_ 1476 AverageSpeedBPlus "+/- 0,1 ";
BA_ "Event trans." SG_ 1476 AverageSpeedBPlus 0;
BA_ "GenSigSendType" SG_ 1476 AverageSpeedBPlus 3;
BA_ "Accuracy" SG_ 1476 PartialOdometerBPlus "+/- 0,1 ";
BA_ "Event trans." SG_ 1476 PartialOdometerBPlus 0;
BA_ "GenSigSendType" SG_ 1476 PartialOdometerBPlus 3;
BA_ "Accuracy" SG_ 1476 ResetTripBPlusACK "- ";
BA_ "Event trans." SG_ 1476 ResetTripBPlusACK 0;
BA_ "GenSigSendType" SG_ 1476 ResetTripBPlusACK 3;
BA_ "Accuracy" SG_ 1476 TravelingTimeBPlus_Hour "- ";
BA_ "Event trans." SG_ 1476 TravelingTimeBPlus_Hour 0;
BA_ "GenSigSendType" SG_ 1476 TravelingTimeBPlus_Hour 3;
BA_ "Accuracy" SG_ 1476 TravelingTimeBPlus_Minute "- ";
BA_ "Event trans." SG_ 1476 TravelingTimeBPlus_Minute 0;
BA_ "GenSigSendType" SG_ 1476 TravelingTimeBPlus_Minute 3;
BA_ "Accuracy" SG_ 1476 TravelingTimeBPlus_Second "- ";
BA_ "Accuracy" SG_ 748 UConnReq "- ";
BA_ "Event trans." SG_ 748 UConnReq 0;
BA_ "GenSigSendType" SG_ 748 UConnReq 6;
BA_ "Accuracy" SG_ 748 UConnReqAuthCode "- ";
BA_ "Accuracy" SG_ 748 UConnReqFOBNum "- ";
BA_ "Event trans." SG_ 1976 UConnSeed1 0;
BA_ "GenSigSendType" SG_ 1976 UConnSeed1 1;
BA_ "Event trans." SG_ 1976 UConnSeed2 0;
BA_ "GenSigSendType" SG_ 1976 UConnSeed2 1;
BA_ "Event trans." SG_ 1976 UConnSeed3 0;
BA_ "GenSigSendType" SG_ 1976 UConnSeed3 1;
BA_ "Event trans." SG_ 1976 UConnSeed4 0;
BA_ "GenSigSendType" SG_ 1976 UConnSeed4 1;
BA_ "GenSigStartValue" SG_ 992 VIN_MSG 3;
BA_ "Accuracy" SG_ 152 ControlEncoding "- ";
BA_ "Event trans." SG_ 152 ControlEncoding 0;
BA_ "GenSigSendType" SG_ 152 ControlEncoding 1;
BA_ "Accuracy" SG_ 152 F11 "- ";
BA_ "Accuracy" SG_ 152 F12 "- ";
BA_ "Accuracy" SG_ 152 Rnd1 "- ";
BA_ "Accuracy" SG_ 152 Rnd2 "- ";
BA_ "Accuracy" SG_ 152 Rnd3 "- ";
BA_ "Accuracy" SG_ 152 Rnd4 "- ";
BA_ "Accuracy" SG_ 154 BlockSts "- ";
BA_ "Accuracy" SG_ 154 ControlEncoding "- ";
BA_ "Event trans." SG_ 154 ControlEncoding 0;
BA_ "GenSigSendType" SG_ 154 ControlEncoding 1;
BA_ "Accuracy" SG_ 154 G21 "- ";
BA_ "Accuracy" SG_ 154 G22 "- ";
VAL_ 1474 AIAAlarmCauseSts 0 "Not_Active" 1 "Active" ;
VAL_ 1474 AlarmFailSts 0 "Fail_Not_Present" 1 "Fail_Present" ;
VAL_ 1474 BonnetAlarmCauseSts 0 "Not_Active" 1 "Active" ;
VAL_ 1474 DoorsAlarmCauseSts 0 "Not_Active" 1 "Active" ;
VAL_ 1474 ElectricalAlarmCauseSts 0 "Not_Active" 1 "Active" ;
VAL_ 1474 PanicModeActive 0 "Not_Active" 1 "Active" ;
VAL_ 1474 TrunkAlarmCauseSts 0 "Not_Active" 1 "Active" ;
VAL_ 1474 USAlarmCauseSts 0 "Not_Active" 1 "Active" ;
VAL_ 160 BCMFpsCommand 0 "Do_Not_Actuate" 1 "Actuate" ;
VAL_ 160 BCMFpsConfirm 0 "Actuate" 1 "Do_Not_Actuate" ;
VAL_ 160 BCMFpsFailSts 0 "Fail_not_Present" 1 "Fail_Present" ;
VAL_ 134 FPS_Status_Request 0 "No_FPS_Request" 1 "FPS_Actual_Status_Request" ;
VAL_ 1478 DSS_ONSts 0 "Surround_Sound_Off" 1 "Surround_Sound_On" ;
VAL_ 1478 INFO1_AUD_ACT 0 "Not_Active" 1 "Active" ;
VAL_ 1478 INFO1_AUD_TYPE 0 "None" 1 "TA" 2 "NAV" 3 "VR_Prompt" 4 "Phone_Audio" 5 "Signal_Chime" 6 "E-Call/U-call/ACR" 15 "SNA" ;
VAL_ 1478 INFO2_AUD_ACT 0 "Not_Active" 1 "Active" ;
VAL_ 1478 INFO2_AUD_TYPE 0 "None" 1 "TA" 2 "NAV" 3 "VR_Prompt" 4 "Phone_Audio" 5 "Signal_Chime" 6 "E-Call/U-call/ACR" 15 "SNA" ;
VAL_ 1478 SCV_LVLSts 0 "Off" 1 "Level_1" 2 "Level_2" 3 "Level_3" 4 "Level_4" 5 "Level_5" 6 "Level_6" 7 "SNA" ;
VAL_ 852 AHBFeature 0 "OFF" 1 "ON" ;
VAL_ 852 AlertLightsON 0 "OFF" 1 "ON" ;
VAL_ 852 DRLFault 0 "False" 1 "True" ;
VAL_ 852 FHeatedWindowSts 0 "OFF" 1 "ON" ;
VAL_ 852 FrontFogLightSts 0 "OFF" 1 "ON" ;
VAL_ 852 HeatedMirrorSts 0 "OFF" 1 "ON" ;
VAL_ 852 HighBeamSts 0 "OFF" 1 "ON" ;
VAL_ 852 L_TurnLightActivationSts 0 "Not_Active" 1 "Active" ;
VAL_ 852 LHParkingLightSts 0 "OFF" 1 "ON" ;
VAL_ 852 LHTurnLightFault 0 "False" 1 "True" ;
VAL_ 852 LHTurnSignalSts 0 "OFF" 1 "ON" ;
VAL_ 852 LowBeamSts 0 "OFF" 1 "ON" ;
VAL_ 852 ParkingLightFault 0 "False" 1 "True" ;
VAL_ 852 PlateLightFault 0 "False" 1 "True" ;
VAL_ 852 R_TurnLightActivationSts 0 "Not_Active" 1 "Active" ;
VAL_ 852 RearFogLightFault 0 "False" 1 "True" ;
VAL_ 852 RearFogLightSts 0 "OFF" 1 "ON" ;
VAL_ 852 ReverseGearLightFault 0 "False" 1 "True" ;
VAL_ 852 RHeatedWindowSts 0 "OFF" 1 "ON" ;
VAL_ 852 RHParkingLightSts 0 "OFF" 1 "ON" ;
VAL_ 852 RHTurnLightFault 0 "False" 1 "True" ;
VAL_ 852 RHTurnSignalSts 0 "OFF" 1 "ON" ;
VAL_ 852 StopLightFault 0 "False" 1 "True" ;
VAL_ 852 StopLightSts 0 "OFF" 1 "ON" ;
VAL_ 1270 AHBFault 0 "OFF" 1 "ON" ;
VAL_ 1270 DisplaySts 0 "LaneSense_OFF" 1 "LaneSense_ON_HF_ NotA" 2 "SingleLine_Left " 3 "SingleLine_Right" 4 "ON_HF_NotA_NHTSA_on_Left" 5 "ON_HF_NotA_NHTSA _on_Right" 6 "ON_HF_Armed" 7 "ON_HF_Left_SingleLine_Left" 8 "ON_HF_Left_side" 9 "ON_HF_Right_SingleLine_Right " 10 "ON_HF_Right_side" 11 "ON_HF_Left_ NHTSA_on_Left" 12 "ON_HF_Right_NHTSA_on_Right" 13 "ON" 97 "ON_HF_NotA_NoHands" 98 "SingleLine_Left_marker_NoHands" 99 "SingleLine_Right_marker_NoHands" 100 "ON_HF_NotA_NHTSA_on_Left_NoHand" 101 "ON_HF_NotA_NHTSA_on_Right_NoHand" 102 "ON_HF_Armed_NoHands" 103 "ON_HF_Left_SingleLine_Left_NoHand" 104 "ON_HF_Left_NoHands" 105 "ON_HF_Right_ SingleLine_R_NoHand" 106 "ON_HF_Right_NoHands" 107 "ON_HF_Left_NHTSA_on_Left_NoHand" 108 "ON_HF_Right_NHTSA_on_R_NoHand" 160 "Sensor_Blinded" 161 "LaneSense_Temp _Unavailable " 162 "Blinded_LaneSense_AHBC_ON" 240 "LaneSense_Fault" 255 "SNA" ;
VAL_ 1270 HALF_CHIME_TYPESts 0 "None" 6 "Half_Chime" 15 "SNA" ;
VAL_ 1270 HALF_LF_CHIME_RQSts 0 "False" 1 "True" ;
VAL_ 1270 HALF_RF_CHIME_RQSts 0 "False" 1 "True" ;
VAL_ 1270 SensorBlinded 0 "OFF" 1 "ON" ;
VAL_ 986 DisplayInfoReceptionSts 0 "Received" 1 "Not_Received" ;
VAL_ 146 Focus 0 "Row1" 1 "Row2" 2 "Row3" 3 "Row4" 4 "Row5" 5 "Row6" 6 "Row7" 7 "Row8" 8 "Row9" 9 "Row10" ;
VAL_ 146 SMS_PopUp 0 "Off" 1 "On" ;
VAL_ 146 Status_DOWN 0 "NotActive" 1 "Active" ;
VAL_ 146 Status_LEFT 0 "NotActive" 1 "Active" ;
VAL_ 146 Status_OK 0 "NotActive" 1 "Active" ;
VAL_ 146 Status_RIGHT 0 "NotActive" 1 "Active" ;
VAL_ 146 Status_UP 0 "NotActive" 1 "Active" ;
VAL_ 1468 AmbientLightingLevel 0 "Level_1" 1 "Level_2" 2 "Level_3" 3 "Level_4" 4 "Level_5" 5 "Level_6" 6 "Level_7" 7 "Level_8" 8 "Level_9" 9 "Level_10" 10 "Level_11" 11 "Level_12" 12 "Level_13" 13 "Level_14" 14 "Level_15" 15 "Level_16" ;
VAL_ 1468 AudioRepetition 0 "On" 1 "Off" ;
VAL_ 1468 AutoHighBeamEnable 0 "Not_Enable" 1 "Enable" ;
VAL_ 1468 AutomaticResetTripB 0 "Never" 1 "Always" 2 "2 hours" 3 "8 hours" ;
VAL_ 1468 AutoParkBrake 0 "On" 1 "Off" ;
VAL_ 1468 AutoRelock 0 "Disable" 1 "Enable" ;
VAL_ 1468 BSDEnable 0 "Not_Enable" 1 "Enable_LED" 2 "Enable_ LED_Chime" ;
VAL_ 1468 ConsumptionUnit 0 "Km_Per_Litre" 1 "Litres_Per_100Km" 2 "Miles_Per_Gallon_UK" 3 "Miles_Per_Gallon_US" 4 "not_used" 5 "not_used" 6 "not_used" 7 "not_used" ;
VAL_ 1468 CorneringEnable 0 "True" 1 "False" ;
VAL_ 1468 DistanceUnit 0 "km" 1 "miles" ;
VAL_ 1468 DRLEnable 0 "True" 1 "False" ;
VAL_ 1468 ExternalLightSensorLevel 0 "Level_3" 1 "Level_2" 2 "Level_1" 3 "Level_0" ;
VAL_ 1468 GreetingLightsEnable 0 "True" 1 "False" ;
VAL_ 1468 HourMode 0 "0_24_h" 1 "0_12_h" ;
VAL_ 1468 LanguageSelection 0 "Italian" 1 "Deutsch" 2 "English" 3 "Espanol" 4 "Francais" 5 "Portugues" 6 "Polish" 7 "Dutch" 8 "Brazilian" 9 "Turkish" 10 "Mexican" 11 "English_US" 12 "Canadian" 13 "Russian" 14 "Chinese" 15 "Japanese" 16 "Korean" 17 "Arabic" ;
VAL_ 1468 NavRepetition 0 "Absent" 1 "Present" ;
VAL_ 1468 PamAlertMode 0 "Off" 1 "Sound" 2 "Sound_Display" ;
VAL_ 1468 PamChimeVolumeFront 0 "Low" 1 "Medium" 2 "High" ;
VAL_ 1468 PamChimeVolumeRear 0 "Low" 1 "Medium" 2 "High" ;
VAL_ 1468 PassiveEntry 0 "On" 1 "Off" ;
VAL_ 1468 PhoneRepetition 0 "Absent" 1 "Present" ;
VAL_ 1468 RainSensorLevel 0 "Not_Enable" 1 "Enable" ;
VAL_ 1468 RemoteDoorUnlock 0 "Driver" 1 "All" ;
VAL_ 1468 Sdw 0 "Off" 1 "Sound" 2 "Sound_Display" ;
VAL_ 1468 SdwChimeVolume 0 "Low" 1 "Medium" 2 "High" ;
VAL_ 1468 SoundHornLock 0 "Off" 1 "1st Press" 2 "2nd Press" ;
VAL_ 1468 SoundHornRemoteStart 0 "On" 1 "Off" ;
VAL_ 1468 SpeedLockDoorEnable 0 "Not_Enable" 1 "Enable" ;
VAL_ 1468 TelematicSetupACK 0 "No_ACK_Required" 1 "ACK_KO" 3 "ACK_OK" ;
VAL_ 1468 TemperatureUnit 0 "°C" 1 "°F" ;
VAL_ 1486 AutoUnlockDoorExit 0 "Not_Enable" 1 "Enable" ;
VAL_ 1486 EPB_Maintenance_Fdbk 0 "Initialization" 31 "SNA" ;
VAL_ 1486 EPB_MaintenanceMode 0 "Off" 1 "On" ;
VAL_ 1486 FlashLightWLock 0 "Off" 1 "On" ;
VAL_ 1486 FSFCWPlusActivationMode 0 "Near" 1 "Med" 2 "Far" ;
VAL_ 1486 FSFCWPlusSetting 0 "Off" 1 "Audio" 2 "Brake" 3 "Audio_Brake" 4 "Not_Request" ;
VAL_ 1486 HeadlightsOffDelay 0 "0sec" 1 "30sec" 2 "60sec" 3 "90ec" ;
VAL_ 1486 LDW_Intensity 0 "Low" 1 "Med" 2 "High" ;
VAL_ 1486 LDW_Sensibility 0 "Early" 1 "Med" 2 "Late" ;
VAL_ 1486 TyrePressureUnit 0 "KPa" 1 "psi" 2 "bar" ;
VAL_ 773 LbssSysBlockIndSts 0 "False" 1 "True" ;
VAL_ 773 LbssSysInterfIndSts 0 "False" 1 "True" ;
VAL_ 773 LbssSysSrvIndSts 0 "False" 1 "True" ;
VAL_ 773 LbssTmpUnavIndSts 0 "False" 1 "True" ;
VAL_ 2654208046 ActiveLoadSlave_AMP 0 "No_Active_Loads_in_Slave" 1 "Active_Loads_in_Slave" ;
VAL_ 2654208046 CurrentFailSts_AMP 0 "No_Fail_Present" 1 "Fail_Present" ;
VAL_ 2654208046 D_ES_AMP 0 "Error_Active_State" 1 "Error_Passive_Warning_State" 2 "Bus_Off_State" 3 "Not_Used" ;
VAL_ 2654208046 EOL_AMP 0 "No_EOL_Programming" 1 "EOL_Programming" ;
VAL_ 2654208046 GenericFailSts_AMP 0 "No_Fail_Present" 1 "Fail_Present" ;
VAL_ 2654208046 SystemStatus_AMP 0 "Wake_up" 1 "Not_Used" 2 "StayActive" 3 "Not_Used" ;
VAL_ 2654208046 Zero_byte_AMP 0 "Fixed" ;
VAL_ 2654208000 ActiveLoadMaster 0 "No_Active_loads_in_master" 1 "Active_loads_in_master" ;
VAL_ 2654208000 D_ES_BCM 0 "Error_Active_State" 1 "Error_Passive_Warning_State" 2 "Bus_Off_State" 3 "Not_Used" ;
VAL_ 2654208000 EOL_BCM 0 "No_EOL_Programming" 1 "EOL_Programming" ;
VAL_ 2654208000 GenericFailSts_BCM 0 "No_FunctionalFailPresent" 1 "FunctionalFailPresent" ;
VAL_ 2654208000 Node0 0 "Not_active" 1 "Active" ;
VAL_ 2654208000 Node1 0 "Not_active" 1 "Active" ;
VAL_ 2654208000 Node10 0 "Not_active" 1 "Active" ;
VAL_ 2654208000 Node11 0 "Not_active" 1 "Active" ;
VAL_ 2654208000 Node12 0 "Not_active" 1 "Active" ;
VAL_ 2654208000 Node13 0 "Not_active" 1 "Active" ;
VAL_ 2654208000 Node14 0 "Not_active" 1 "Active" ;
VAL_ 2654208000 Node15 0 "Not_active" 1 "Active" ;
VAL_ 2654208000 Node16 0 "Not_active" 1 "Active" ;
VAL_ 2654208000 Node17 0 "Not_active" 1 "Active" ;
VAL_ 2654208000 Node18 0 "Not_active" 1 "Active" ;
VAL_ 2654208000 Node19 0 "Not_active" 1 "Active" ;
VAL_ 2654208000 Node2 0 "Not_active" 1 "Active" ;
VAL_ 2654208000 Node20 0 "Not_active" 1 "Active" ;
VAL_ 2654208000 Node21 0 "Not_active" 1 "Active" ;
VAL_ 2654208000 Node22 0 "Not_active" 1 "Active" ;
VAL_ 2654208000 Node23 0 "Not_active" 1 "Active" ;
VAL_ 2654208000 Node24 0 "Not_active" 1 "Active" ;
VAL_ 2654208000 Node25 0 "Not_active" 1 "Active" ;
VAL_ 2654208000 Node26 0 "Not_active" 1 "Active" ;
VAL_ 2654208000 Node27 0 "Not_active" 1 "Active" ;
VAL_ 2654208000 Node28 0 "Not_active" 1 "Active" ;
VAL_ 2654208000 Node29 0 "Not_active" 1 "Active" ;
VAL_ 2654208000 Node3 0 "Not_active" 1 "Active" ;
VAL_ 2654208000 Node30 0 "Not_active" 1 "Active" ;
VAL_ 2654208000 Node31 0 "Not_active" 1 "Active" ;
VAL_ 2654208000 Node4 0 "Not_active" 1 "Active" ;
VAL_ 2654208000 Node5 0 "Not_active" 1 "Active" ;
VAL_ 2654208000 Node6 0 "Not_active" 1 "Active" ;
VAL_ 2654208000 Node7 0 "Not_active" 1 "Active" ;
VAL_ 2654208000 Node8 0 "Not_active" 1 "Active" ;
VAL_ 2654208000 Node9 0 "Not_active" 1 "Active" ;
VAL_ 2654208000 P_ES 0 "Fail_Not_Present" 1 "Fail_Present" ;
VAL_ 2654208000 SystemCommand 0 "Wake_up" 1 "Not_Used" 2 "StayActive" 3 "Sleep" ;
VAL_ 2654208000 Zero_byte_BCM 0 "Fixed" ;
VAL_ 2654208010 ActiveLoadSlave_Climate 0 "No_Active_Loads_in_Slave" 1 "Active_Loads_in_Slave" ;
VAL_ 2654208010 CurrentFailSts_Climate 0 "No_Fail_Present" 1 "Fail_Present" ;
VAL_ 2654208010 D_ES_Climate 0 "Error_Active_State" 1 "Error_Passive_Warning_State" 2 "Bus_Off_State" 3 "Not_Used" ;
VAL_ 2654208010 EOL_Climate 0 "No_EOL_Programming" 1 "EOL_Programming" ;
VAL_ 2654208010 GenericFailSts_Climate 0 "No_Fail_Present" 1 "Fail_Present" ;
VAL_ 2654208010 SystemStatus_Climate 0 "Wake_up" 1 "Not_Used" 2 "StayActive" 3 "Not_Used" ;
VAL_ 2654208010 Zero_byte_Climate 0 "Fixed" ;
VAL_ 2654208003 ActiveLoadSlave_IPC 0 "No_Active_Loads_in_Slave" 1 "Active_Loads_in_Slave" ;
VAL_ 2654208003 CurrentFailSts_IPC 0 "No_Fail_Present" 1 "Fail_Present" ;
VAL_ 2654208003 D_ES_IPC 0 "Error_Active_State" 1 "Error_Passive_Warning_State" 2 "Bus_Off_State" 3 "Not_Used" ;
VAL_ 2654208003 EOL_IPC 0 "No_EOL_Programming" 1 "EOL_Programming" ;
VAL_ 2654208003 GenericFailSts_IPC 0 "No_Fail_Present" 1 "Fail_Present" ;
VAL_ 2654208003 SystemStatus_IPC 0 "Wake_up" 1 "Not_Used" 2 "StayActive" 3 "Not_Used" ;
VAL_ 2654208003 Zero_byte_IPC 0 "Fixed" ;
VAL_ 2654208051 ActiveLoadSlave_LBSS 0 "No_Active_Loads_in_Slave" 1 "Active_Loads_in_Slave" ;
VAL_ 2654208051 CurrentFailSts_LBSS 0 "No_Fail_Present" 1 "Fail_Present" ;
VAL_ 2654208051 D_ES_LBSS 0 "Error_Active_State" 1 "Error_Passive_Warning_State" 2 "Bus_Off_State" 3 "Not_Used" ;
VAL_ 2654208051 EOL_LBSS 0 "No_EOL_Programming" 1 "EOL_Programming" ;
VAL_ 2654208051 GenericFailSts_LBSS 0 "No_Fail_Present" 1 "Fail_Present" ;
VAL_ 2654208051 SystemStatus_LBSS 0 "Wake_up" 1 "Not_Used" 2 "StayActive" 3 "Not_Used" ;
VAL_ 2654208051 Zero_byte_LBSS 0 "Fixed" ;
VAL_ 2654208052 ActiveLoadSlave_RBSS 0 "No_Active_Loads_in_Slave" 1 "Active_Loads_in_Slave" ;
VAL_ 2654208052 CurrentFailSts_RBSS 0 "No_Fail_Present" 1 "Fail_Present" ;
VAL_ 2654208052 D_ES_RBSS 0 "Error_Active_State" 1 "Error_Passive_Warning_State" 2 "Bus_Off_State" 3 "Not_Used" ;
VAL_ 2654208052 EOL_RBSS 0 "No_EOL_Programming" 1 "EOL_Programming" ;
VAL_ 2654208052 GenericFailSts_RBSS 0 "No_Fail_Present" 1 "Fail_Present" ;
VAL_ 2654208052 SystemStatus_RBSS 0 "Wake_up" 1 "Not_Used" 2 "StayActive" 3 "Not_Used" ;
VAL_ 2654208052 Zero_byte_RBSS 0 "Fixed" ;
VAL_ 2654208036 ActiveLoadSlave_Telematic 0 "No_Active_Loads_in_Slave" 1 "Active_Loads_in_Slave" ;
VAL_ 2654208036 CurrentFailSts_Telematic 0 "No_Fail_Present" 1 "Fail_Present" ;
VAL_ 2654208036 D_ES_Telematic 0 "Error_Active_State" 1 "Error_Passive_Warning_State" 2 "Bus_Off_State" 3 "Not_Used" ;
VAL_ 2654208036 EOL_Telematic 0 "No_EOL_Programming" 1 "EOL_Programming" ;
VAL_ 2654208036 GenericFailSts_Telematic 0 "No_Fail_Present" 1 "Fail_Present" ;
VAL_ 2654208036 SystemStatus_Telematic 0 "Wake_up" 1 "Not_Used" 2 "StayActive" 3 "Not_Used" ;
VAL_ 2654208036 Zero_byte_Telematic 0 "Fixed" ;
VAL_ 2654208063 ActiveLoadSlave_TTM 0 "No_Active_Loads_in_Slave" 1 "Active_Loads_in_Slave" ;
VAL_ 2654208063 CurrentFailSts_TTM 0 "No_Fail_Present" 1 "Fail_Present" ;
VAL_ 2654208063 D_ES_TTM 0 "Error_Active_State" 1 "Error_Passive_Warning_State" 2 "Bus_Off_State" 3 "Not_Used" ;
VAL_ 2654208063 EOL_TTM 0 "No_EOL_Programming" 1 "EOL_Programming" ;
VAL_ 2654208063 GenericFailSts_TTM 0 "No_Fail_Present" 1 "Fail_Present" ;
VAL_ 2654208063 SystemStatus_TTM 0 "Wake_up" 1 "Not_Used" 2 "StayActive" 3 "Not_Used" ;
VAL_ 2654208063 Zero_byte_TTM 0 "Fixed" ;
VAL_ 2654208049 ActiveLoadSlave_VTM 0 "No_Active_Loads_in_Slave" 1 "Active_Loads_in_Slave" ;
VAL_ 2654208049 CurrentFailSts_VTM 0 "No_Fail_Present" 1 "Fail_Present" ;
VAL_ 2654208049 D_ES_VTM 0 "Error_Active_State" 1 "Error_Passive_Warning_State" 2 "Bus_Off_State" 3 "Not_Used" ;
VAL_ 2654208049 EOL_VTM 0 "No_EOL_Programming" 1 "EOL_Programming" ;
VAL_ 2654208049 GenericFailSts_VTM 0 "No_Fail_Present" 1 "Fail_Present" ;
VAL_ 2654208049 SystemStatus_VTM 0 "Wake_up" 1 "Not_Used" 2 "StayActive" 3 "Not_Used" ;
VAL_ 2654208049 Zero_byte_VTM 0 "Fixed" ;
VAL_ 950 Alert_CHF 0 "No_object_detected" 1 "1_Arc" 2 "2_Arc" 3 "3_Arc" 4 "4_Arc" 5 "5_Arc" 6 "6_Arc" 7 "SNA" ;
VAL_ 950 Alert_CHR 0 "No_object_detected" 1 "1_Arc" 2 "2_Arc" 3 "3_Arc" 4 "4_Arc" 5 "5_Arc" 6 "6_Arc" 7 "SNA" ;
VAL_ 950 Alert_LHF 0 "No_object_detected" 1 "1_Arc" 2 "2_Arc" 7 "SNA" ;
VAL_ 950 Alert_LHR 0 "No_object_detected" 1 "1_Arc" 2 "2_Arc" 7 "SNA" ;
VAL_ 950 Alert_RHF 0 "No_object_detected" 1 "1_Arc" 2 "2_Arc" 7 "SNA" ;
VAL_ 950 Alert_RHR 0 "No_object_detected" 1 "1_Arc" 2 "2_Arc" 7 "SNA" ;
VAL_ 950 ChimeActivation_LHF 0 "NotActive" 1 "Active" ;
VAL_ 950 ChimeActivation_LHR 0 "NotActive" 1 "Active" ;
VAL_ 950 ChimeActivation_RHF 0 "NotActive" 1 "Active" ;
VAL_ 950 ChimeActivation_RHR 0 "NotActive" 1 "Active" ;
VAL_ 950 ChimeType_Front 0 "Type4" 1 "Type5" ;
VAL_ 950 ChimeType_Rear 0 "Type4" 1 "Type5" ;
VAL_ 950 DisplayActivation 0 "NotActive" 1 "Active" ;
VAL_ 950 Graphic_CHF 0 "Slow_flash" 1 "Solid" 2 "None" 3 "SNA" ;
VAL_ 950 Graphic_CHR 0 "Slow_flash" 1 "Solid" 2 "None" 3 "SNA" ;
VAL_ 950 Graphic_LHF 0 "Slow_flash" 1 "Solid" 2 "None" 3 "SNA" ;
VAL_ 950 Graphic_LHR 0 "Slow_flash" 1 "Solid" 2 "None" 3 "SNA" ;
VAL_ 950 Graphic_RHF 0 "Slow_flash" 1 "Solid" 2 "None" 3 "SNA" ;
VAL_ 950 Graphic_RHR 0 "Slow_flash" 1 "Solid" 2 "None" 3 "SNA" ;
VAL_ 775 RbssSysBlockIndSts 0 "False" 1 "True" ;
VAL_ 775 RbssSysInterfIndSts 0 "False" 1 "True" ;
VAL_ 775 RbssSysSrvIndSts 0 "False" 1 "True" ;
VAL_ 775 RbssTmpUnavIndSts 0 "False" 1 "True" ;
VAL_ 948 SDW_ChimeActivation_LHF 0 "NotActive" 1 "Active" ;
VAL_ 948 SDW_ChimeActivation_LHR 0 "NotActive" 1 "Active" ;
VAL_ 948 SDW_ChimeActivation_RHF 0 "NotActive" 1 "Active" ;
VAL_ 948 SDW_ChimeActivation_RHR 0 "NotActive" 1 "Active" ;
VAL_ 948 SDW_ChimeType_Left 0 "Type8" 1 "Type6" ;
VAL_ 948 SDW_ChimeType_Right 0 "Type8" 1 "Type6" ;
VAL_ 948 SDW_DisplayActivation 0 "NotActive" 1 "Active" ;
VAL_ 948 SDW_Warning_Left_1 0 "NoWarning" 1 "Area1" 2 "Area2" 3 "NotActive" ;
VAL_ 948 SDW_Warning_Left_2 0 "NoWarning" 1 "Area1" 2 "Area2" 3 "NotActive" ;
VAL_ 948 SDW_Warning_Right_1 0 "NoWarning" 1 "Area1" 2 "Area2" 3 "NotActive" ;
VAL_ 948 SDW_Warning_Right_2 0 "NoWarning" 1 "Area1" 2 "Area2" 3 "NotActive" ;
VAL_ 1890 DaysToService 511 "SNA" ;
VAL_ 1890 DistanceToService 131071 "SNA" ;
VAL_ 2000 AMP_DSS_STATSts 0 "CFG_ST" 1 "CFG_VID_SURR" 2 "CFG_AUD_SURR" 7 "SNA" ;
VAL_ 2000 AMP_MUTEDSts 1 "Muted" 0 "Unmuted" ;
VAL_ 2000 AUDIOSts_AMP 0 "Initialization" 1 "Available" 2 "Not_Available" ;
VAL_ 2000 PowerModeSts_AMP 0 "Standard_Power" 1 "Logistic_Mode_ON" 2 "Logistic_Mode_PR" 3 "Not_Used" ;
VAL_ 2000 SURR_AVAILSts 1 "TRUE" 0 "FALSE" ;
VAL_ 854 AlarmSysTurnOn 0 "AllarmeOff" 1 "Deterrenza" 2 "InserzioneAllarme" 3 "VerificaPlausibilita" 4 "Accesso" 5 "WindowOpen" 9 "Spento" ;
VAL_ 854 AutoCloseSts 0 "Not_active" 1 "Active" ;
VAL_ 854 AutoOpenSts 0 "Not_active" 1 "Active" ;
VAL_ 854 BonnetSts 0 "Closed" 1 "Open" ;
VAL_ 854 BrakeFluidLevelSts 0 "OK" 1 "Low_level" ;
VAL_ 854 BrakePedalSwitchNOSts 0 "Not_Active" 1 "Active" ;
VAL_ 854 DriverDoorSts 0 "Closed" 1 "Open" ;
VAL_ 854 FrontWiperMoveSts 0 "Stop" 1 "Moving" ;
VAL_ 854 FuelLevel 255 "SNA" ;
VAL_ 854 FuelLevelFailSts 0 "Fail_Not_Present" 1 "Fail_Present" ;
VAL_ 854 LHRDoorSts 0 "Closed" 1 "Open" ;
VAL_ 854 LowFuelWarningSts 0 "OFF" 1 "ON" ;
VAL_ 854 NightAndDaySensorFailSts 0 "Fail_Not_Present" 1 "Fail_Present" ;
VAL_ 854 OperationalModeSts 0 "Initialization" 1 "Ignition_Off_WithoutKey" 2 "Ignition_Off" 3 "Ignition_Acc" 4 "Ignition_On" 5 "Ignition_Pre_Start" 6 "Ignition_Start" 7 "Ignition_Cranking" 8 "Ignition_On_EngOn" 9 "Ignition_Pre_Acc" 10 "Ignition_Pre_Off" 11 "Automatic_Cranking" 12 "Automatic_Stop" 13 "Key_Authenticated" 14 "Not_Used" 15 "SNA" ;
VAL_ 854 ParkBrakeSts 0 "OFF" 1 "ON" ;
VAL_ 854 PowerModeSts 0 "Standard_Power" 1 "Logistic_Mode_ON" 2 "Logistic_Mode_PR" 3 "Not_Used" ;
VAL_ 854 PsngrDoorSts 0 "Closed" 1 "Open" ;
VAL_ 854 RainSensorFailSts 0 "Fail_not_present" 1 "Fail_present" ;
VAL_ 854 RHatchSts 0 "Closed" 1 "Open" ;
VAL_ 854 RHRDoorSts 0 "Closed" 1 "Open" ;
VAL_ 854 StopStartActivationSts 0 "Activated" 1 "Deactivated" 2 "Not_Used" 3 "Not_Used" ;
VAL_ 854 StopStartVisualizationCode 0 "No_Visualization" 1 "Code_1" 2 "Code_2" 3 "Code_3" 4 "Code_4" 5 "Code_5" 6 "Code_6" 7 "Code_7" ;
VAL_ 854 SysEOLSts 0 "EOL_Ready" 1 "EOL_Not_Ready" ;
VAL_ 854 WarningKeyInSts 0 "Not_active" 1 "Active" ;
VAL_ 1132 BatteryChargeSts 15 "SNA" ;
VAL_ 1132 CmdIgn_FailSts 0 "Fail_Not_Present" 1 "Fail_Present" 3 "SNA" ;
VAL_ 1132 CmdIgnSts 0 "Initialization" 1 "IGN_LK" 3 "ACC" 4 "RUN" 5 "START" 7 "SNA" ;
VAL_ 1132 CurrentFailStsIBS 0 "No_DTC_Present_In_ECU" 1 "At_Least_One_DTC_Present_IN_ECU" ;
VAL_ 1132 DriveStyleSts 0 "Normal" 1 "City" 2 "Sport_Fun" 3 "Winter_Race" 4 "Eco" 5 "TracPlus" 6 "Trekking" 7 "Auto" 8 "Snow" 9 "Sand" 10 "Mud" 11 "Rock" 12 "Race" 31 "SNA" ;
VAL_ 1132 ExternalTemperatureC 511 "SNA" ;
VAL_ 1132 ExternalTemperatureF 511 "SNA" ;
VAL_ 1132 ExternalTemperatureFailSts 0 "Fail_Not_Present" 1 "Fail_Present" ;
VAL_ 1132 Int_Relay_FailSts 0 "Fail_Not_Present" 1 "Fail_Present" 3 "SNA" ;
VAL_ 1132 InternalLightLevel 0 "Level_1" 1 "Level_2" 2 "Level_3" 3 "Level_4" 4 "Level_5" 5 "Level_6" 6 "Level_7" 7 "Level_8" 8 "Level_9" 9 "Level_10" 10 "Level_11" 11 "Level_12" 12 "Level_13" 13 "Level_14" 14 "Level_15" 15 "Level_16" ;
VAL_ 1132 InternalLightSts 0 "Not_Active" 1 "Active" ;
VAL_ 1132 RemStActvSts 0 "Remote Start Not Active" 1 "Remote Start Active" ;
VAL_ 1132 TurnIndicationSts 0 "Center" 1 "Right" 2 "Left" 3 "SNA" ;
VAL_ 1128 ClusterLightSts 0 "Not_Active_Day" 1 "Active_Night" ;
VAL_ 1128 SPM_Mode_Selection 0 "None" 1 "Parallel Mode" 2 "Perpendicular Mode" 3 "Pull Out Mode" ;
VAL_ 988 AF_FailSts 0 "Fail_Not_Present" 1 "Fail_Present" ;
VAL_ 988 LatAcceleration_BSM 4095 "SNA" ;
VAL_ 988 LatAccelerationFailSts_BSM 0 "Fail_Not_Present" 1 "Fail_Present" ;
VAL_ 988 LongAcceleration_BSM 4095 "SNA" ;
VAL_ 988 LongAccelerationFailSts_BSM 0 "Fail_Not_Present" 1 "Fail_Present" ;
VAL_ 988 YawRate_BSM 4095 "SNA" ;
VAL_ 988 YawRateFailSts_BSM 0 "Fail_Not_Present" 1 "Fail_Present" ;
VAL_ 990 LHF_FastPulseCounter 255 "SNA" ;
VAL_ 990 LHF_FastPulseCounter_Overflow 0 "No_overflow" 1 "Overflow_Present" ;
VAL_ 990 LHF_WheelSensorFailSts 0 "Fail_Not_Present" 1 "Fail_Present" ;
VAL_ 990 LHR_FastPulseCounter 255 "SNA" ;
VAL_ 990 LHR_FastPulseCounter_Overflow 0 "No_overflow" 1 "Overflow_Present" ;
VAL_ 990 LHR_WheelSensorFailSts 0 "Fail_Not_Present" 1 "Fail_Present" ;
VAL_ 990 RHF_FastPulseCounter 255 "SNA" ;
VAL_ 990 RHF_FastPulseCounter_Overflow 0 "No_overflow" 1 "Overflow_Present" ;
VAL_ 990 RHF_WheelSensorFailSts 0 "Fail_Not_Present" 1 "Fail_Present" ;
VAL_ 990 RHR_FastPulseCounter 255 "SNA" ;
VAL_ 990 RHR_FastPulseCounter_Overflow 0 "No_overflow" 1 "Overflow_Present" ;
VAL_ 990 RHR_WheelSensorFailSts 0 "Fail_Not_Present" 1 "Fail_Present" ;
VAL_ 990 TravelDistance 255 "SNA" ;
VAL_ 994 ACPressure 511 "SNA" ;
VAL_ 994 ACPressureFailSts 0 "Fail_Not_Present" 1 "Fail_Present" ;
VAL_ 994 AlternatorFail 0 "Alternator_Fail" 1 "Alternator_Not_In_Fail" ;
VAL_ 994 CompressorSts 0 "Not_Used" 1 "Not_inserted_by_NCM" 2 "Not_insrtd_by_driver_or_security" 3 "Inserted" ;
VAL_ 994 EngineSts 0 "Engine_Off" 1 "Engine_Cranking" 2 "Engine_On" 3 "SNA" ;
VAL_ 994 EngineWaterTemp 255 "SNA" ;
VAL_ 994 EngineWaterTempFailSts 0 "Fail_Not_Present" 1 "Fail_Present" ;
VAL_ 994 ShiftModeSts 0 "Manual" 1 "Automatic" ;
VAL_ 994 VehicleSpeedVSOSig 8191 "SNA" ;
VAL_ 994 VehicleSpeedVSOSig_UB 0 "Not_Updated" 1 "Updated" ;
VAL_ 994 VehicleSpeedVSOSigFailSts 0 "Fail_not_present" 1 "Fail_present" ;
VAL_ 994 VehicleSpeedVSOSigFailSts_UB 0 "Not_Updated" 1 "Updated" ;
VAL_ 996 DPFSts 0 "Clean" 1 "Dirty" ;
VAL_ 996 FuelConsumption_GAG 65535 "SNA" ;
VAL_ 996 GearShiftIndication 0 "No_Gearshift_Suggestion_by_ECM" 1 "Downshift_Suggestion_by_ECM" 2 "Upshift_Suggestion_by_ECM" 3 "Strategy_Not_Available_ECM_Fail" ;
VAL_ 996 OilLifeSts 0 "Normal_Oil_Properties" 1 "Oil_Life_Reset" 2 "Change_Oil_Required" 3 "Not_used" ;
VAL_ 996 ReverseGearSts 0 "Not_Inserted" 1 "Inserted" 2 "Not_Used" 3 "SNA" ;
VAL_ 998 EngineSpeed 16383 "SNA" ;
VAL_ 998 EngineSpeedFailSts 0 "Fail_not_present" 1 "Fail_present" ;
VAL_ 998 EPBSts 0 "Released" 1 "Applied" 2 "DynamicBrkESC" 3 "DynamicBrkEPB" 4 "Emergency_Braking" 5 "Applying" 6 "Maintenance_Mode" 7 "Assembly_Check" 8 "Inspection_Mode" 9 "Re_Clamping" 10 "Adjuste_Mode" 11 "Releasing" 12 "Fault_EPB_Released" 13 "Fault_EPB_Applied" 14 "Fault_Present" 15 "SNA" ;
VAL_ 998 LWSAngle 65535 "SNA" ;
VAL_ 998 LWSFailSts 0 "Fail_not_Present" 1 "Fail_Present_Ignition_Latched" 2 "Fail_Present_Recoverable" 3 "Fail_Present_Battery_Disconnection" ;
VAL_ 998 ShiftLeverPosition 0 "No_Selection_Active_Or_Available" 1 "P" 2 "R" 3 "N" 4 "D" 5 "L" 6 "TIP_Autostick" 7 "Plus" 8 "Minus" 9 "Sport" 10 "Not_Used" 11 "Not_Used" 12 "Not_Used" 13 "Not_Used" 14 "Not_Used" 15 "SNA" ;
VAL_ 1984 InflationState_LHF_Tyre 0 "Normal_Tyre_Pressure" 1 "Under_Inflated_Tyre" 2 "SignificantlyUnderInflatedTyre" 3 "Over_Inflated_Tyre" 4 "Sensor_Missing" ;
VAL_ 1984 InflationState_LHR_Tyre 0 "Normal_Tyre_Pressure" 1 "Under_Inflated_Tyre" 2 "SignificantlyUnderInflatedTyre" 3 "Over_Inflated_Tyre" 4 "Sensor_Missing" ;
VAL_ 1984 InflationState_RHF_Tyre 0 "Normal_Tyre_Pressure" 1 "Under_Inflated_Tyre" 2 "SignificantlyUnderInflatedTyre" 3 "Over_Inflated_Tyre" 4 "Sensor_Missing" ;
VAL_ 1984 InflationState_RHR_Tyre 0 "Normal_Tyre_Pressure" 1 "Under_Inflated_Tyre" 2 "SignificantlyUnderInflatedTyre" 3 "Over_Inflated_Tyre" 4 "Sensor_Missing" ;
VAL_ 1984 TyrePressureSystemFailSts 0 "Fail_Not_Present" 1 "Fail_Present" ;
VAL_ 1130 A2D_DRV_TEMP_DR_POS 1023 "SNA" ;
VAL_ 1130 A2D_FT_HVAC_BLOWER_VOLTAGE 1023 "SNA" ;
VAL_ 1130 AcOutputCurrentSts 255 "SNA" ;
VAL_ 1130 CompressorACReqSts 0 "Not_Active" 1 "Active" ;
VAL_ 1130 FHeatedWindowCmd 0 "Not_Active" 1 "Active" ;
VAL_ 1130 HVAC_Blower_Speed 0 "0% <= PWM < 20%" 1 "20% <= PWM < 30%" 2 "30% <= PWM < 40%" 3 "40% <= PWM < 50%" 4 "50% <= PWM < 55%" 5 "55% <= PWM < 60%" 6 "60% <= PWM < 65%" 7 "65% <= PWM < 70%" 8 "70% <= PWM < 75%" 9 "75% <= PWM < 80%" 10 "80% <= PWM < 85%" 11 "85% <= PWM < 90%" 12 "90% <= PWM < 95%" 13 "95% <= PWM <= 100%" 14 "Blower_shutdown" 15 "SNA" ;
VAL_ 1130 HVAC_SAM_enable 0 "No_Request" 1 "SAM_Disabling_Request" 2 "Not Used" 3 "SNA" ;
VAL_ 1130 MaxDefrostSts 0 "OFF" 1 "ON" ;
VAL_ 1130 PowerModeSts_Climate 0 "Standard_Power" 1 "Logistic_Mode_On" 2 "Logistic_Mode_PR" 3 "Not_Used" ;
VAL_ 1130 PTCFailSts 0 "Fail_Not_Present" 1 "Fail_Present" ;
VAL_ 1130 PTCSts 0 "zero_per_cent" 1 "thirtythree_per_cent" 2 "sixtysix_per_cent" 3 "onehundred_per_cent" ;
VAL_ 1130 RHeatedWindowCmd 0 "Not_Active" 1 "Active" ;
VAL_ 1130 StopStartEnable 0 "False" 1 "True" ;
VAL_ 1098 BSS_LF_Chime_RQSts 0 "No_left_frnt_chime_on_req" 1 "Left_front_chime_on_req" ;
VAL_ 1098 BSS_LR_Chime_RQSts 0 "No_left_rear_chime_on_req" 1 "Left_rear_chime_on_req" ;
VAL_ 1098 BSS_LT_Blind_RQSts 0 "No Sensor Blocked Request" 1 "Sensor Blocked Request" ;
VAL_ 1098 BSS_LT_CFG_STATSts 0 "Not_enabled" 1 "Enabled_for_LED" 2 "Enabled_for_LED_and_Chime" 3 "SNA" ;
VAL_ 1098 BSS_LT_Chime_TypeSts 0 "None" 1 "type1" 2 "type2" 3 "type3" 4 "type4" 5 "type5" 6 "type6" 7 "type7" 8 "type8" 9 "type9" 10 "type10" 11 "type11" 12 "type12" 13 "type13" 14 "type14" 15 "SNA" ;
VAL_ 1098 BSS_LT_OPR_StatSts 0 "No Operational Failure" 1 "Operational Failure - System Unavailable" ;
VAL_ 1098 BSS_LT_SRV_RQSts 0 "No Service Request" 1 "Service Request" ;
VAL_ 1098 BssLtLedFaultSts 0 "No_Fault" 1 "Short_to_Ground" 2 "Short_to_Batt" 3 "Open_Circuit" ;
VAL_ 1098 BssLtWrnSts 0 "Not_Present" 1 "Present" ;
VAL_ 1462 DynamicGridFailSts 0 "Fail_Not_Present" 1 "Fail_Present" ;
VAL_ 1462 DynamicGridSts 0 "Dynamic Gridlines OFF" 1 "Dynamic Gridlines ON" ;
VAL_ 1462 SWSError 0 "No_Errors" 1 "Error_Present" ;
VAL_ 1268 FrontSensorSts 0 "Active" 1 "Not_Active_blocked" 2 "Not_Active_failure" 3 "SNA" ;
VAL_ 1268 LateralSensorSts 0 "Active" 1 "Not_Active_blocked" 2 "Not_Active_failure" 3 "SNA" ;
VAL_ 1268 PAMAboveSpeed 0 "False" 1 "True" ;
VAL_ 1268 PAMSystemFault 0 "False" 1 "Temporary_Failure" 2 "External_Failure" 3 "System_Failure" ;
VAL_ 1268 PAMSystemSts 0 "OFF" 1 "ON_Active" 2 "ON_Inactive" 3 "ON_Disabled" ;
VAL_ 1268 RearSensorSts 0 "Active" 1 "Not_Active_blocked" 2 "Not_Active_failure" 3 "SNA" ;
VAL_ 1268 SDWFailSts 0 "Fail_Not_Present" 1 "Fail_Present" ;
VAL_ 1268 SDWSts 0 "Not_Active" 1 "Active" ;
VAL_ 1268 SPMControlSts 0 "Not_Active" 1 "Active_ParallelParking" 2 "Active_PerpendicularParking" 3 "Active_OutParking" ;
VAL_ 1268 SPMFailSts 0 "False" 1 "True" ;
VAL_ 1100 BSS_RF_Chime_RQSts 0 "No_rght_frnt_chime_on_req" 1 "Right_front_chime_on_req" ;
VAL_ 1100 BSS_RR_Chime_RQSts 0 "No_rght_rear_chime_on_req" 1 "Right_rear_chime_on_req" ;
VAL_ 1100 BSS_RT_Blind_RQSts 0 "No Sensor Bocked Request" 1 "Sensor Blocked Request" ;
VAL_ 1100 BSS_RT_CFG_STATSts 0 "Not_enabled" 1 "Enabled_for_LED" 2 "Enabled_for_LED_and_Chime" 3 "SNA" ;
VAL_ 1100 BSS_RT_Chime_TypeSts 0 "None" 1 "type1" 2 "type2" 3 "type3" 4 "type4" 5 "type5" 6 "type6" 7 "type7" 8 "type8" 9 "type9" 10 "type10" 11 "type11" 12 "type12" 13 "type13" 14 "type14" 15 "SNA" ;
VAL_ 1100 BSS_RT_OPR_StatSts 0 "No Operational Failure" 1 "Operational failure - System Unavailable" ;
VAL_ 1100 BSS_RT_SRV_RQSts 0 "No Service Requested" 1 "Service Requested" ;
VAL_ 1100 BssRtLedFaultSts 0 "No_Fault" 1 "Short_to_Ground" 2 "Short_to_Batt" 3 "Open_Circuit" ;
VAL_ 1100 BssRtWrnSts 0 "Not_Present" 1 "Present" ;
VAL_ 1470 AntitheftSts 0 "Not_Successfully" 1 "In_Progress" 2 "Successfully" ;
VAL_ 1470 AUDIOSts_Telematic 0 "Initialization" 1 "Available" 2 "Not_Available" ;
VAL_ 1470 CurrentSource 0 "AM_Selected" 1 "FM_Selected" 2 "MW_Selected" 3 "LW_Selected" 4 "Internal_DISC_Selected" 5 "Internal_HDD_Selected" 6 "Internal_AUX_Selected" 7 "Internal_Slot_Media_Slctd" 8 "DTV_Selected" 9 "SDAR1_Selected" 10 "SW_Selected" 11 "VES_DVD1_Selected" 12 "MFLO_Selected" 13 "VES_AUX1_Selected" 14 "VES_AUX2_Selected" 15 "SDARV_Selected" 16 "HFM_Personal_HU_Selected" 18 "DAB_Selected" 19 "TGW_USB1_Selected" 23 "HFM_BlueTooth_1_Selected" 28 "IR_Off_Selected" 29 "HU_Off " 30 "HU_Locked" 31 "SNA" ;
VAL_ 1470 HFPSts 0 "Not_Active" 1 "Pending" 2 "Active" ;
VAL_ 1470 MuteSts 0 "Not_Muted" 1 "Muted" ;
VAL_ 1470 PowerModeSts_Telematic 0 "Standard_Power" 1 "Logistic_Mode_ON" 2 "Logistic_Mode_PR" 3 "Not_Used" ;
VAL_ 1470 PowerSts_Telematic 0 "Sleep" 1 "Standby" 2 "Timed" 3 "Idle" 4 "Full_Operation" 5 "Logistic_On" 6 "Bench" 7 "Partial_Operation" ;
VAL_ 1470 VRSts 0 "Not_Active" 1 "Active" ;
VAL_ 1464 TrailerConnectionSts 0 "Not_Connected" 1 "Connected" 2 "Not_Used" 3 "SNA" ;
VAL_ 1464 TrailerGenericFailSts 0 "No_fault_present" 1 "Fault_present" ;
VAL_ 1464 TrailerLHParkingLightFailSts 0 "No_fault_present" 1 "Fault_present" ;
VAL_ 1464 TrailerLHParkingLightSts 0 "OFF" 1 "ON" ;
VAL_ 1464 TrailerLHTurnSignalFailSts 0 "No_fault_present" 1 "Fault_present" ;
VAL_ 1464 TrailerLHTurnSignalSts 0 "OFF" 1 "ON" ;
VAL_ 1464 TrailerRearFogLightFailSts 0 "No_fault_present" 1 "Fault_present" ;
VAL_ 1464 TrailerRearFogLightSts 0 "OFF" 1 "ON" ;
VAL_ 1464 TrailerReverseGearFailSts 0 "No_fault_present" 1 "Fault_present" ;
VAL_ 1464 TrailerReverseGearSts 0 "OFF" 1 "ON" ;
VAL_ 1464 TrailerRHParkingLightFailSts 0 "No_fault_present" 1 "Fault_present" ;
VAL_ 1464 TrailerRHParkingLightSts 0 "OFF" 1 "ON" ;
VAL_ 1464 TrailerRHTurnSignalFailSts 0 "No_fault_present" 1 "Fault_present" ;
VAL_ 1464 TrailerRHTurnSignalSts 0 "OFF" 1 "ON" ;
VAL_ 1464 TrailerStopLightFailSts 0 "No_fault_present" 1 "Fault_present" ;
VAL_ 1464 TrailerStopLightSts 0 "OFF" 1 "ON" ;
VAL_ 846 VTMFailSts 0 "Fail_Not_Present" 1 "Fail_Present" ;
VAL_ 846 VTMLightFailSts 0 "Fail_Not_Present" 1 "Fail_Present" ;
VAL_ 846 VTMSts 0 "VTM_virgin" 1 "Blocked" 2 "Unblocked" 3 "Not_Used" ;
VAL_ 750 Command_01Sts 0 "Not_Pressed" 1 "Pressed" 3 "SNA" ;
VAL_ 750 Command_02Sts 0 "Not_Pressed" 1 "Pressed" 3 "SNA" ;
VAL_ 750 Command_03Sts 0 "Not_Pressed" 1 "Pressed" 3 "SNA" ;
VAL_ 750 Command_04Sts 0 "Not_Pressed" 1 "Pressed" 3 "SNA" ;
VAL_ 750 Command_05Sts 0 "Not_Pressed" 1 "Pressed" 3 "SNA" ;
VAL_ 750 Command_06Sts 0 "Not_Pressed" 1 "Pressed" 3 "SNA" ;
VAL_ 750 Command_07Sts 0 "Not_Pressed" 1 "Pressed" 3 "SNA" ;
VAL_ 750 Command_08Sts 0 "Not_Pressed" 1 "Pressed" 3 "SNA" ;
VAL_ 750 Command_09Sts 0 "Not_Pressed" 1 "Pressed" 3 "SNA" ;
VAL_ 750 Command_10Sts 0 "Not_Pressed" 1 "Pressed" 3 "SNA" ;
VAL_ 750 Command_11Sts 0 "Not_Pressed" 1 "Pressed" 3 "SNA" ;
VAL_ 750 Command_12Sts 0 "Not_Pressed" 1 "Pressed" 3 "SNA" ;
VAL_ 750 Command_13Sts 0 "Not_Pressed" 1 "Pressed" 3 "SNA" ;
VAL_ 750 Command_14Sts 0 "Not_Pressed" 1 "Pressed" 3 "SNA" ;
VAL_ 750 Command_15Sts 0 "Not_Pressed" 1 "Pressed" 3 "SNA" ;
VAL_ 144 FrameNumber 0 "Frame1" 1 "Frame2" 2 "Frame3" 3 "Frame4" 4 "Frame5" 5 "Frame6" 6 "Frame7" 7 "Frame8" 8 "Frame9" 9 "Frame10" 10 "Frame11" 11 "Frame12" 12 "Frame13" 13 "Frame14" 14 "Frame15" 15 "Frame16" 16 "Frame17" 17 "Frame18" 18 "Frame19" 19 "Frame20" 20 "Frame21" 21 "Frame22" 22 "Frame23" 23 "Frame24" 24 "Frame25" 25 "Frame26" 26 "Frame27" 27 "Frame28" 28 "Frame29" 29 "Frame30" 30 "Frame31" 31 "Frame32" ;
VAL_ 144 TotalFrameNumber 0 "Frame1" 1 "Frame2" 2 "Frame3" 3 "Frame4" 4 "Frame5" 5 "Frame6" 6 "Frame7" 7 "Frame8" 8 "Frame9" 9 "Frame10" 10 "Frame11" 11 "Frame12" 12 "Frame13" 13 "Frame14" 14 "Frame15" 15 "Frame16" 16 "Frame17" 17 "Frame18" 18 "Frame19" 19 "Frame20" 20 "Frame21" 21 "Frame22" 22 "Frame23" 23 "Frame24" 24 "Frame25" 25 "Frame26" 26 "Frame27" 27 "Frame28" 28 "Frame29" 29 "Frame30" 30 "Frame31" 31 "Frame32" ;
VAL_ 136 LastAnnouncement 0 "Not_Last" 1 "Last" ;
VAL_ 136 ResolutionDistToTurn 0 "One" 1 "ZeroPointOne" 2 "ZeroPointZeroOne" ;
VAL_ 136 Unit 0 "ClearUnit" 1 "Kilometer" 2 "Meter" 3 "Mile" 4 "Feet" 5 "Yard" 6 "SNA" ;
VAL_ 158 AmbientLightingLevel_Req 0 "Level_1" 1 "Level_2" 2 "Level_3" 3 "Level_4" 4 "Level_5" 5 "Level_6" 6 "Level_7" 7 "Level_8" 8 "Level_9" 9 "Level_10" 10 "Level_11" 11 "Level_12" 12 "Level_13" 13 "Level_14" 14 "Level_15" 15 "Level_16" ;
VAL_ 158 AutoHighBeamEnable_Req 0 "Not_Enable" 1 "Enable" ;
VAL_ 158 AutoParkBrake_Req 0 "On" 1 "Off" ;
VAL_ 158 BSDEnable_Req 0 "Not_Enable" 1 "Enable_LED" 2 "Enable_ LED_Chime" ;
VAL_ 158 ConsumptionUnit_Req 0 "Km_Per_Litre" 1 "Litres_Per_100Km" 2 "Miles_Per_Gallon_UK" 3 "Miles_Per_Gallon_US" 4 "not_used" 5 "not_used" 6 "not_used" 7 "not_used" ;
VAL_ 158 CorneringEnable_Req 0 "True" 1 "False" ;
VAL_ 158 DistanceUnit_Req 0 "km" 1 "miles" ;
VAL_ 158 DRLEnable_Req 0 "True" 1 "False" ;
VAL_ 158 DynamicGrid_Req 0 "Dynamic Gridlines OFF" 1 "Dynamic Gridlines ON" ;
VAL_ 158 ExternalLightSensorLevel_Req 0 "Level_3" 1 "Level_2" 2 "Level_1" 3 "Level_0" ;
VAL_ 158 GreetingLightsEnable_Req 0 "True" 1 "False" ;
VAL_ 158 HourMode_Req 0 "0_24_h" 1 "0_12_h" ;
VAL_ 158 LanguageSelection_Req 0 "Italian" 1 "Deutsch" 2 "English" 3 "Espanol" 4 "Francais" 5 "Portugues" 6 "Polish" 7 "Dutch" 8 "Brazilian" 9 "Turkish" 10 "Mexican" 11 "English_US" 12 "Canadian" 13 "Russian" 14 "Chinese" 15 "Japanese" 16 "Korean" 17 "Arabic" ;
VAL_ 158 PamAlertMode_Req 0 "Off" 1 "Sound" 2 "Sound_Display" ;
VAL_ 158 PamChimeVolumeFront_Req 0 "Low" 1 "Medium" 2 "High" ;
VAL_ 158 PamChimeVolumeRear_Req 0 "Low" 1 "Medium" 2 "High" ;
VAL_ 158 PassiveEntry_Req 0 "On" 1 "Off" ;
VAL_ 158 PhoneRepetition_Req 0 "On" 1 "Off" ;
VAL_ 158 RainSensorLevel_Req 0 "Not_Enable" 1 "Enable" ;
VAL_ 158 RemoteDoorUnlock_Req 0 "Driver" 1 "All" ;
VAL_ 158 ResetTripA_Req 0 "Not_Active" 1 "Active" ;
VAL_ 158 ResetTripB_Req 0 "Not_Active" 1 "Active" ;
VAL_ 158 Sdw_Req 0 "Off" 1 "Sound" 2 "Sound_Display" ;
VAL_ 158 SdwChimeVolume_Req 0 "Low" 1 "Medium" 2 "High" ;
VAL_ 158 SoundHornLock_Req 0 "Off" 1 "1st Press" 2 "2nd Press" ;
VAL_ 158 SoundHornRemoteStart_Req 0 "On" 1 "Off" ;
VAL_ 158 SpeedLockDoorEnable_Req 0 "Not_Enable" 1 "Enable" ;
VAL_ 158 TemperatureUnit_Req 0 "°C" 1 "°F" ;
VAL_ 162 AutoUnlockDoorExit_Req 0 "Not_Enable" 1 "Enable" ;
VAL_ 162 EPB_MaintenanceMode_Req 0 "Off" 1 "On" ;
VAL_ 162 FlashLightWLock_Req 0 "Off" 1 "On" ;
VAL_ 162 FSFCWPlusActivationMode_Req 0 "Near" 1 "Med" 2 "Far" ;
VAL_ 162 FSFCWPlusSetting_Req 0 "Off" 1 "Audio" 2 "Brake" 3 "Audio_Brake" 4 "Not_Request" ;
VAL_ 162 HeadlightsOffDelay_Req 0 "0sec" 1 "30sec" 2 "60sec" 3 "90sec" ;
VAL_ 162 LDW_Intensity_Req 0 "Low" 1 "Med" 2 "High" ;
VAL_ 162 LDW_Sensibility_Req 0 "Early" 1 "Med" 2 "Late" ;
VAL_ 162 TyrePressureUnit_Req 0 "kPa" 1 "psi" 2 "bar" ;
VAL_ 1472 AverageFuelConsumptionAPlus 1023 "SNA" ;
VAL_ 1472 AverageSpeedAPlus 255 "SNA" ;
VAL_ 1472 PartialOdometerAPlus 1048575 "SNA" ;
VAL_ 1472 ResetTripAPlusACK 0 "No_ACK_required" 1 "ACK_KO" 2 "ACK_KO" 3 "ACK_OK" ;
VAL_ 1888 AutonomyDistance 2047 "SNA" ;
VAL_ 1888 InstantaneousFuelConsumption1 15 "SNA" ;
VAL_ 1888 InstantaneousFuelConsumption2 15 "SNA" ;
VAL_ 1888 InstantaneousFuelConsumption3 15 "SNA" ;
VAL_ 1476 AverageFuelConsumptionBPlus 1023 "SNA" ;
VAL_ 1476 AverageSpeedBPlus 255 "SNA" ;
VAL_ 1476 PartialOdometerBPlus 1048575 "SNA" ;
VAL_ 1476 ResetTripBPlusACK 0 "No_ACK_required" 1 "ACK_KO" 2 "ACK_KO" 3 "ACK_OK" ;
VAL_ 748 UConnReq 0 "NO_BASIC_REQUEST" 1 "LOCK_REQUEST" 2 "RELOCK_REQUEST" 3 "DRIVER_UNLOCK_REQUEST" 4 "ALL_UNLOCK_REQUEST" 5 "TRUNK_PLG_TOGGLE_REQUEST" 6 "LEFT_SLIDER_TOGGLE_REQUEST" 7 "RIGHT_SLIDER_TOGGLE_REQUEST" 8 "FLIPPER_GLASS_REQUEST" 9 "REMOTE_START_ON" 10 "REMOTE_START_OFF" 11 "GLOBAL_WINDOW_DOWN_REQUEST" 12 "OPEN_CONVERTIBLE_TOP" 13 "CLOSE_CONVERTIBLE_TOP" 14 "PANIC_TOGGLE_REQUEST" 15 "GLOBAL_WINDOW_UP_REQUEST " 16 "FOLLOW_ME" 31 "SNA" ;
VAL_ 748 UConnReqFOBNum 0 "FOB_DEFAULT" 1 "FOB_1" 2 "FOB_2" 3 "FOB_3" 4 "FOB_4" 5 "FOB_5" 6 "FOB_6" 7 "FOB_7" 8 "FOB_8" 15 "SNA" ;
VAL_ 992 VIN_MSG 0 "VIN_LO" 1 "VIN_MID" 2 "VIN_HI" 3 "SNA" ;
VAL_ 154 BlockSts 0 "Invalid_Status" 1 "Block" 2 "Unblock" 3 "Not_used" ;
